VERSION ""

NS_ :

BS_:

BU_: PFAF_HS LVMPC_HS DCDC_HS AMP_HS VICM2_HS FICM_HS ARS_HS MCP_B_HS MCP_A_HS ICCM_OBD_HS SAS_HS ACCM_HS VLBS_HS EBCM_OBD_HS EDI_HS HPCC_HS VITM_OBD_HS PTAM_HS OBCM_HS VICM_HS HCP_HS FDCM_HS APPS_HS ICCM_HS EOCM_F_HS GPCM_HS FSCM_ITBC_HS SCM_HS ITBC_HS VCM_HS HMIM_HS FCP_HS VES_HS Dummy_HS MCP_C_HS RWS_HS ONSTAR_HS EPS_HS TestTool_HS MCP_HS BCP_HS ALC_HS AHL_AFL_HS SADS_HS EPB_HS FSCM_HS AFS_HS FCM_HS TCCM_HS RDCM_HS PTO_HS PCM_HS EBCM_HS ACC_HS BCM_HS TCM_HS ECM_HS

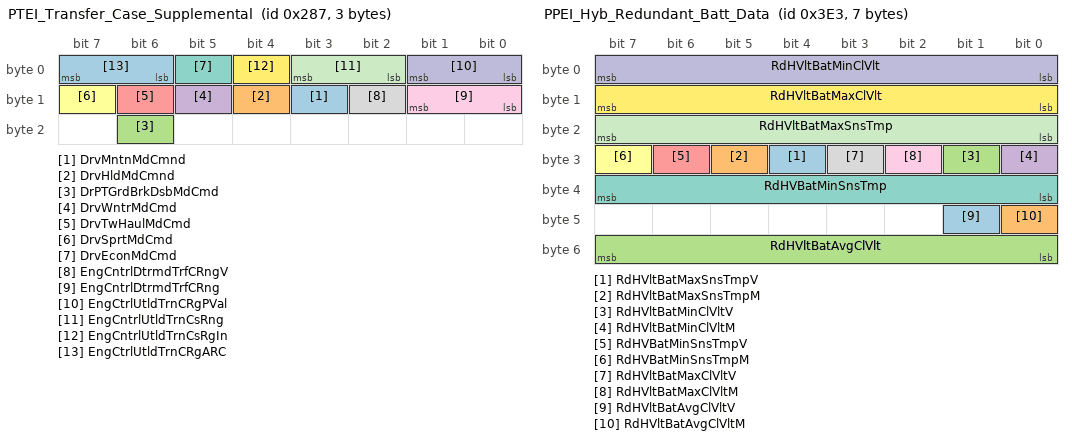
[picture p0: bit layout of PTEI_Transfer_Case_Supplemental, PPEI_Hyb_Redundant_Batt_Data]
BO_ 647 PTEI_Transfer_Case_Supplemental: 3 ECM_HS
 SG_ DrvMntnMdCmnd : 11|1@0+ (1,0) [0|1] ""  HCP_HS
 SG_ DrvHldMdCmnd : 12|1@0+ (1,0) [0|1] ""  HCP_HS
 SG_ DrPTGrdBrkDsbMdCmd : 22|1@0+ (1,0) [0|1] ""  TCM_HS
 SG_ DrvWntrMdCmd : 13|1@0+ (1,0) [0|1] ""  TCM_HS
 SG_ DrvTwHaulMdCmd : 14|1@0+ (1,0) [0|1] ""  TCM_HS
 SG_ DrvSprtMdCmd : 15|1@0+ (1,0) [0|1] ""  TCM_HS,HCP_HS
 SG_ DrvEconMdCmd : 5|1@0+ (1,0) [0|1] ""  TCM_HS
 SG_ EngCntrlDtrmdTrfCRngV : 10|1@0+ (1,0) [0|1] ""  ICCM_OBD_HS,ICCM_HS,TCM_HS
 SG_ EngCntrlDtrmdTrfCRng : 9|2@0+ (1,0) [0|3] ""  ICCM_OBD_HS,ICCM_HS,TCM_HS
 SG_ EngCtrlUtldTrnCRgPVal : 1|2@0+ (1,0) [0|3] ""  EBCM_OBD_HS,EBCM_HS,HCP_HS
 SG_ EngCntrlUtldTrnCsRng : 3|2@0+ (1,0) [0|3] ""  EBCM_OBD_HS,EBCM_HS,BCP_HS,HCP_HS
 SG_ EngCntrlUtldTrnCsRgIn : 4|1@0+ (1,0) [0|1] ""  EBCM_OBD_HS,EBCM_HS,HCP_HS
 SG_ EngCtrlUtldTrnCRgARC : 7|2@0+ (1,0) [0|3] ""  EBCM_OBD_HS,EBCM_HS,HCP_HS

BO_ 368 Environment_Id_Resp_5_HS: 3 ONSTAR_HS
 SG_ EnvIdRspSt5 : 17|2@0+ (1,0) [0|3] ""  BCM_HS
 SG_ EnvIdRsp5 : 7|16@0+ (1,0) [0|65535] ""  BCM_HS

BO_ 995 PPEI_Hyb_Redundant_Batt_Data: 7 VITM_OBD_HS
 SG_ RdHVltBatMaxSnsTmpV : 28|1@0+ (1,0) [0|1] ""  VICM_HS
 SG_ RdHVltBatMaxSnsTmpM : 29|1@0+ (1,0) [0|1] ""  VICM_HS
 SG_ RdHVltBatMinClVltV : 25|1@0+ (1,0) [0|1] ""  VICM_HS
 SG_ RdHVltBatMinClVltM : 24|1@0+ (1,0) [0|1] ""  VICM_HS
 SG_ RdHVBatMinSnsTmpV : 30|1@0+ (1,0) [0|1] ""  VICM_HS
 SG_ RdHVBatMinSnsTmpM : 31|1@0+ (1,0) [0|1] ""  VICM_HS
 SG_ RdHVBatMinSnsTmp : 39|8@0+ (0.5,-40) [-40|87.5] "deg C"  VICM_HS
 SG_ RdHVltBatMaxClVltV : 27|1@0+ (1,0) [0|1] ""  VICM_HS
 SG_ RdHVltBatMaxClVltM : 26|1@0+ (1,0) [0|1] ""  VICM_HS
 SG_ RdHVltBatMinClVlt : 7|8@0+ (0.02,0) [0|5.1] "V"  VICM_HS
 SG_ RdHVltBatMaxSnsTmp : 23|8@0+ (0.5,-40) [-40|87.5] "deg C"  VICM_HS
 SG_ RdHVltBatMaxClVlt : 15|8@0+ (0.02,0) [0|5.1] "V"  VICM_HS
 SG_ RdHVltBatAvgClVltV : 41|1@0+ (1,0) [0|1] ""  VICM_HS
 SG_ RdHVltBatAvgClVltM : 40|1@0+ (1,0) [0|1] ""  VICM_HS
 SG_ RdHVltBatAvgClVlt : 55|8@0+ (0.02,0) [0|5.1] "volts"  VICM_HS

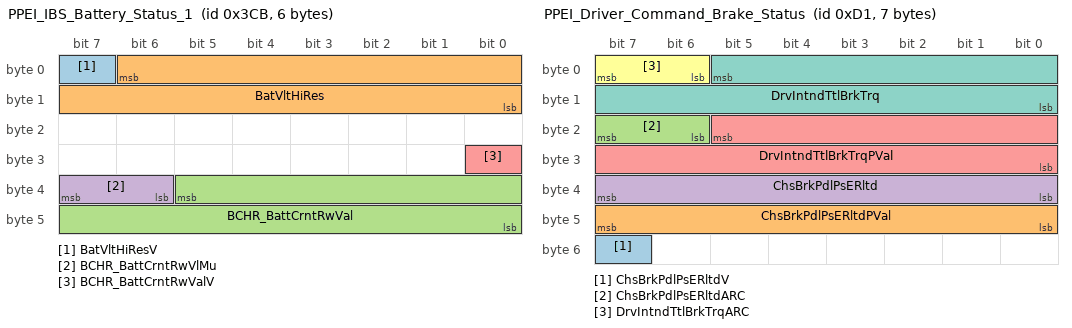
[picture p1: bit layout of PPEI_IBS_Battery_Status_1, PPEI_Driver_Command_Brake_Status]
BO_ 971 PPEI_IBS_Battery_Status_1: 6 BCM_HS
 SG_ BatVltHiResV : 7|1@0+ (1,0) [0|1] ""  ECM_HS
 SG_ BatVltHiRes : 6|15@0+ (0.001,0) [0|32.767] "volts"  ECM_HS
 SG_ BCHR_BattCrntRwVal : 37|14@0+ (0.001,-8.192) [-8.192|8.191] ""  ECM_HS
 SG_ BCHR_BattCrntRwVlMu : 39|2@0+ (1,0) [0|3] ""  ECM_HS
 SG_ BCHR_BattCrntRwValV : 24|1@0+ (1,0) [0|1] ""  ECM_HS

BO_ 209 PPEI_Driver_Command_Brake_Status: 7 EBCM_HS
 SG_ ChsBrkPdlPsERltdV : 55|1@0+ (1,0) [0|1] ""  ECM_HS
 SG_ ChsBrkPdlPsERltdPVal : 47|8@0+ (1,0) [0|255] ""  ECM_HS
 SG_ ChsBrkPdlPsERltdARC : 23|2@0+ (1,0) [0|3] ""  ECM_HS
 SG_ ChsBrkPdlPsERltd : 39|8@0+ (0.392157,0) [0|100.000035] "%"  ECM_HS
 SG_ DrvIntndTtlBrkTrqPVal : 21|14@0+ (1,0) [0|16383] ""  ECM_HS
 SG_ DrvIntndTtlBrkTrqARC : 7|2@0+ (1,0) [0|3] ""  ECM_HS
 SG_ DrvIntndTtlBrkTrq : 5|14@0+ (2,0) [0|32766] "Nm"  ECM_HS,HCP_HS,VICM_HS

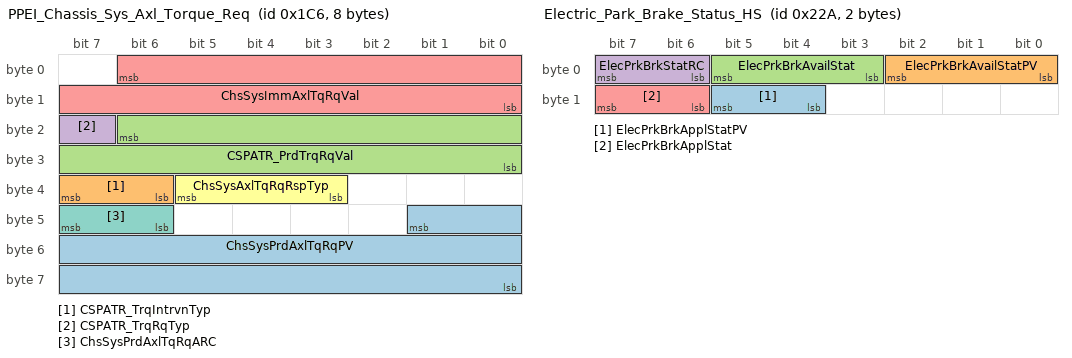
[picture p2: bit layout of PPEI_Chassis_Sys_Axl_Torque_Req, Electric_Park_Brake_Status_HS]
BO_ 454 PPEI_Chassis_Sys_Axl_Torque_Req: 8 EBCM_HS
 SG_ ChsSysPrdAxlTqRqPV : 41|18@0+ (1,0) [0|262143] ""  ECM_HS
 SG_ CSPATR_TrqIntrvnTyp : 39|2@0+ (1,0) [0|3] ""  ECM_HS
 SG_ CSPATR_PrdTrqRqVal : 22|15@0+ (2,-22534) [-22534|43000] "Nm"  ECM_HS
 SG_ CSPATR_TrqRqTyp : 23|1@0+ (1,0) [0|1] ""  ECM_HS
 SG_ ChsSysImmAxlTqRqVal : 6|15@0+ (2,-22534) [-22534|43000] "Nm"  ECM_HS
 SG_ ChsSysAxlTqRqRspTyp : 37|3@0+ (1,0) [0|7] ""  ECM_HS
 SG_ ChsSysPrdAxlTqRqARC : 47|2@0+ (1,0) [0|3] ""  ECM_HS

BO_ 554 Electric_Park_Brake_Status_HS: 2 EPB_HS
 SG_ ElecPrkBrkApplStatPV : 13|2@0+ (1,0) [0|3] ""  VICM_HS,EBCM_OBD_HS,EBCM_HS
 SG_ ElecPrkBrkAvailStatPV : 2|3@0+ (1,0) [0|7] ""  VICM_HS,EBCM_OBD_HS,EBCM_HS
 SG_ ElecPrkBrkAvailStat : 5|3@0+ (1,0) [0|7] ""  VICM_HS,EBCM_OBD_HS,EBCM_HS
 SG_ ElecPrkBrkStatRC : 7|2@0+ (1,0) [0|3] ""  VICM_HS,EBCM_OBD_HS,EBCM_HS
 SG_ ElecPrkBrkApplStat : 15|2@0+ (1,0) [0|3] ""  VICM_HS,EBCM_OBD_HS,EBCM_HS

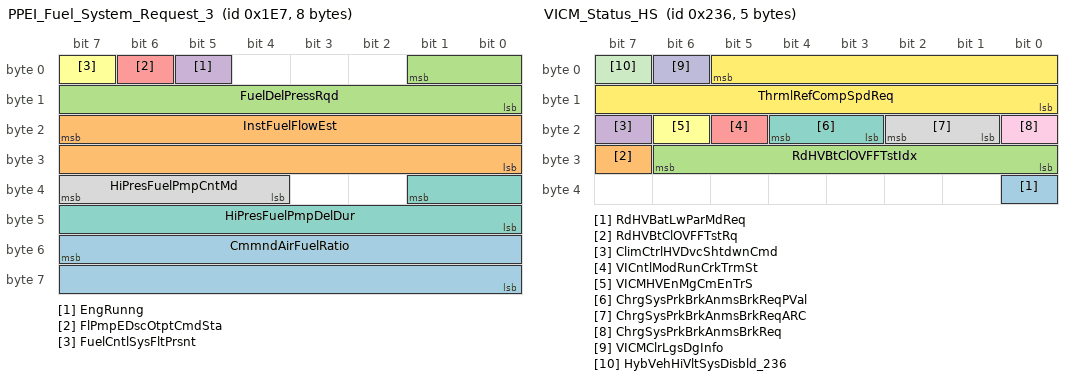
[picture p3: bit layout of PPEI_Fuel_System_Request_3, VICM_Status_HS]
BO_ 487 PPEI_Fuel_System_Request_3: 8 ECM_HS
 SG_ CmmndAirFuelRatio : 55|16@0+ (0.000488281,0) [0|31.999495335] ""  ICCM_OBD_HS,ICCM_HS,FSCM_ITBC_HS,FSCM_HS
 SG_ InstFuelFlowEst : 23|16@0+ (0.000976562,0) [0|63.99899067] "grams/s"  ICCM_OBD_HS,ICCM_HS,FSCM_ITBC_HS,FSCM_HS
 SG_ FuelDelPressRqd : 1|10@0+ (1,0) [0|1023] "kPa"  ICCM_OBD_HS,ICCM_HS,FSCM_ITBC_HS,FSCM_HS
 SG_ EngRunng : 5|1@0+ (1,0) [0|1] ""  ICCM_OBD_HS,ICCM_HS,FSCM_ITBC_HS,FSCM_HS
 SG_ FlPmpEDscOtptCmdSta : 6|1@0+ (1,0) [0|1] ""  ICCM_OBD_HS,ICCM_HS,FSCM_ITBC_HS,FSCM_HS
 SG_ FuelCntlSysFltPrsnt : 7|1@0+ (1,0) [0|1] ""  ICCM_OBD_HS,ICCM_HS,FSCM_ITBC_HS,FSCM_HS
 SG_ HiPresFuelPmpDelDur : 33|10@0+ (1,0) [0|1023] "deg"  ICCM_OBD_HS,ICCM_HS,FSCM_ITBC_HS,FSCM_HS
 SG_ HiPresFuelPmpCntMd : 39|4@0+ (1,0) [0|15] ""  ICCM_OBD_HS,ICCM_HS,FSCM_ITBC_HS,FSCM_HS

BO_ 566 VICM_Status_HS: 5 VICM_HS
 SG_ RdHVBatLwParMdReq : 32|1@0+ (1,0) [0|1] ""  VITM_OBD_HS
 SG_ RdHVBtClOVFFTstRq : 31|1@0+ (1,0) [0|1] ""  VITM_OBD_HS
 SG_ RdHVBtClOVFFTstIdx : 30|7@0+ (1,0) [0|127] ""  VITM_OBD_HS
 SG_ ClimCtrlHVDvcShtdwnCmd : 23|1@0+ (1,0) [0|1] ""  ACCM_HS
 SG_ VICntlModRunCrkTrmSt : 21|1@0+ (1,0) [0|1] ""  ACCM_HS
 SG_ VICMHVEnMgCmEnTrS : 22|1@0+ (1,0) [0|1] ""  VICM2_HS,VITM_OBD_HS,OBCM_HS
 SG_ ChrgSysPrkBrkAnmsBrkReqPVal : 20|2@0+ (1,0) [0|3] ""  EPB_HS
 SG_ ChrgSysPrkBrkAnmsBrkReqARC : 18|2@0+ (1,0) [0|3] ""  EPB_HS
 SG_ ChrgSysPrkBrkAnmsBrkReq : 16|1@0+ (1,0) [0|1] ""  EPB_HS
 SG_ VICMClrLgsDgInfo : 6|1@0+ (1,0) [0|1] ""  ACCM_HS
 SG_ HybVehHiVltSysDisbld_236 : 7|1@0+ (1,0) [0|1] ""  FCP_HS,ONSTAR_HS
 SG_ ThrmlRefCompSpdReq : 5|14@0+ (1,0) [0|16383] "rpm"  ACCM_HS

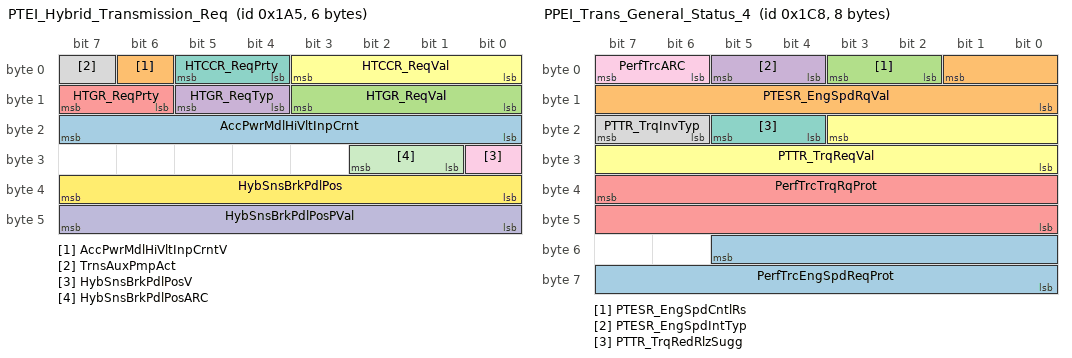
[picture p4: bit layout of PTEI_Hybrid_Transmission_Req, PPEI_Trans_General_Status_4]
BO_ 421 PTEI_Hybrid_Transmission_Req: 6 BCP_HS
 SG_ AccPwrMdlHiVltInpCrnt : 23|8@0+ (0.125,-5) [-5|26.875] "A"  MCP_HS
 SG_ AccPwrMdlHiVltInpCrntV : 6|1@0+ (1,0) [0|1] ""  MCP_HS
 SG_ HTGR_ReqVal : 11|4@0+ (1,0) [0|15] ""  TCM_HS
 SG_ HTGR_ReqTyp : 13|2@0+ (1,0) [0|3] ""  TCM_HS
 SG_ HTGR_ReqPrty : 15|2@0+ (1,0) [0|3] ""  TCM_HS
 SG_ HTCCR_ReqVal : 3|4@0+ (1,0) [0|15] ""  TCM_HS
 SG_ HTCCR_ReqPrty : 5|2@0+ (1,0) [0|3] ""  TCM_HS
 SG_ TrnsAuxPmpAct : 7|1@0+ (1,0) [0|1] ""  TCM_HS
 SG_ HybSnsBrkPdlPosV : 24|1@0+ (1,0) [0|1] ""  TCM_HS,PCM_HS,ECM_HS
 SG_ HybSnsBrkPdlPosPVal : 47|8@0+ (1,0) [0|255] ""  TCM_HS,PCM_HS,ECM_HS
 SG_ HybSnsBrkPdlPosARC : 26|2@0+ (1,0) [0|3] ""  TCM_HS,PCM_HS,ECM_HS
 SG_ HybSnsBrkPdlPos : 39|8@0+ (0.392157,0) [0|100.000035] "%"  TCM_HS,PCM_HS,ECM_HS

BO_ 456 PPEI_Trans_General_Status_4: 8 PTAM_HS
 SG_ PerfTrcEngSpdReqProt : 53|14@0+ (1,0) [0|16383] ""  PCM_HS,ECM_HS
 SG_ PTESR_EngSpdRqVal : 1|10@0+ (8,0) [0|8184] "rpm"  LVMPC_HS,PCM_HS,ECM_HS
 SG_ PTESR_EngSpdCntlRs : 3|2@0+ (1,0) [0|3] ""  LVMPC_HS,PCM_HS,ECM_HS
 SG_ PTESR_EngSpdIntTyp : 5|2@0+ (1,0) [0|3] ""  LVMPC_HS,PCM_HS,ECM_HS
 SG_ PerfTrcTrqRqProt : 39|16@0+ (1,0) [0|65535] ""  PCM_HS,ECM_HS
 SG_ PTTR_TrqReqVal : 19|12@0+ (0.5,-848) [-848|1199.5] "Nm"  ICCM_OBD_HS,ICCM_HS,PCM_HS,ECM_HS
 SG_ PTTR_TrqRedRlzSugg : 21|2@0+ (1,0) [0|3] ""  ICCM_OBD_HS,ICCM_HS,PCM_HS,ECM_HS
 SG_ PTTR_TrqInvTyp : 23|2@0+ (1,0) [0|3] ""  ICCM_OBD_HS,ICCM_HS,PCM_HS,ECM_HS
 SG_ PerfTrcARC : 7|2@0+ (1,0) [0|3] ""  PCM_HS,ECM_HS

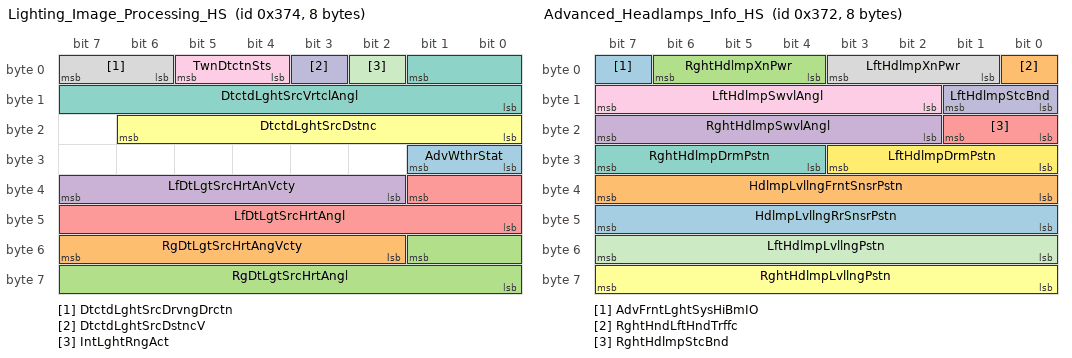
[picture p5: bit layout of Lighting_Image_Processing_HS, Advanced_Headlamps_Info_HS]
BO_ 884 Lighting_Image_Processing_HS: 8 FCM_HS
 SG_ AdvWthrStat : 25|2@0+ (1,0) [0|3] ""  EDI_HS,AHL_AFL_HS
 SG_ RgDtLgtSrcHrtAngVcty : 55|6@0- (1,0) [-32|31] "deg/sec"  AHL_AFL_HS
 SG_ RgDtLgtSrcHrtAngl : 49|10@0- (0.04,0) [-20.48|20.44] "deg"  AHL_AFL_HS
 SG_ LfDtLgtSrcHrtAnVcty : 39|6@0- (1,0) [-32|31] "deg/sec"  AHL_AFL_HS
 SG_ LfDtLgtSrcHrtAngl : 33|10@0- (0.04,0) [-20.48|20.44] "deg"  AHL_AFL_HS
 SG_ DtctdLghtSrcDstnc : 22|7@0+ (10,0) [0|1270] "m"  AHL_AFL_HS
 SG_ DtctdLghtSrcVrtclAngl : 1|10@0- (0.04,0) [-20.48|20.44] "deg"  AHL_AFL_HS
 SG_ DtctdLghtSrcDrvngDrctn : 7|2@0+ (1,0) [0|3] ""  AHL_AFL_HS
 SG_ TwnDtctnSts : 5|2@0+ (1,0) [0|3] ""  AHL_AFL_HS
 SG_ DtctdLghtSrcDstncV : 3|1@0+ (1,0) [0|1] ""  AHL_AFL_HS
 SG_ IntLghtRngAct : 2|1@0+ (1,0) [0|1] ""  AHL_AFL_HS

BO_ 882 Advanced_Headlamps_Info_HS: 8 AHL_AFL_HS
 SG_ AdvFrntLghtSysHiBmIO : 7|1@0+ (1,0) [0|1] ""  BCM_HS,FCM_HS
 SG_ RghtHndLftHndTrffc : 0|1@0+ (1,0) [0|1] ""  FCM_HS
 SG_ RghtHdlmpXnPwr : 6|3@0+ (1,32) [32|39] "Watt"  FCM_HS
 SG_ RghtHdlmpSwvlAngl : 23|6@0- (0.5,0) [-16|15.5] "deg"  FCM_HS
 SG_ RghtHdlmpStcBnd : 17|2@0+ (25,25) [25|100] "%"  FCM_HS
 SG_ RghtHdlmpLvllngPstn : 63|8@0- (0.05,0) [-6.4|6.35] "%"  FCM_HS
 SG_ RghtHdlmpDrmPstn : 31|4@0+ (1,1) [1|16] ""  FCM_HS
 SG_ LftHdlmpXnPwr : 3|3@0+ (1,32) [32|39] "Watt"  FCM_HS
 SG_ LftHdlmpSwvlAngl : 15|6@0- (0.5,0) [-16|15.5] "deg"  FCM_HS
 SG_ LftHdlmpStcBnd : 9|2@0+ (25,25) [25|100] "%"  FCM_HS
 SG_ LftHdlmpLvllngPstn : 55|8@0- (0.05,0) [-6.4|6.35] "%"  FCM_HS
 SG_ LftHdlmpDrmPstn : 27|4@0+ (1,1) [1|16] ""  FCM_HS
 SG_ HdlmpLvllngRrSnsrPstn : 47|8@0- (1,0) [-128|127] "mm"  FCM_HS
 SG_ HdlmpLvllngFrntSnsrPstn : 39|8@0- (1,0) [-128|127] "mm"  FCM_HS

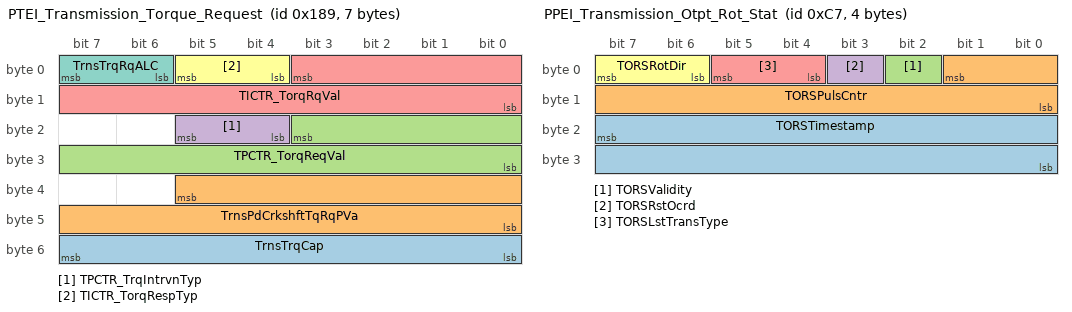
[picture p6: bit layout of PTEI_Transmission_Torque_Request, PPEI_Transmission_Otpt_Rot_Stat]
BO_ 393 PTEI_Transmission_Torque_Request: 7 ECM_HS
 SG_ TrnsTrqCap : 55|8@0+ (4,0) [0|1020] "Nm"  PCM_HS,ECM_HS
 SG_ TrnsPdCrkshftTqRqPVa : 37|14@0+ (1,0) [0|16383] ""  PCM_HS,ECM_HS
 SG_ TPCTR_TorqReqVal : 19|12@0+ (0.5,-848) [-848|1199.5] "Nm"  PCM_HS,ECM_HS
 SG_ TPCTR_TrqIntrvnTyp : 21|2@0+ (1,0) [0|3] ""  PCM_HS,ECM_HS
 SG_ TICTR_TorqRqVal : 3|12@0+ (0.5,-848) [-848|1199.5] "Nm"  PCM_HS,ECM_HS
 SG_ TICTR_TorqRespTyp : 5|2@0+ (1,0) [0|3] ""  PCM_HS,ECM_HS
 SG_ TrnsTrqRqALC : 7|2@0+ (1,0) [0|3] ""  PCM_HS,ECM_HS

BO_ 199 PPEI_Transmission_Otpt_Rot_Stat: 4 TCM_HS
 SG_ TORSTimestamp : 23|16@0+ (1,0) [0|65535] "counts"  ICCM_OBD_HS,ICCM_HS,TCCM_HS,BCP_HS
 SG_ TORSPulsCntr : 1|10@0+ (1,0) [0|1023] "counts"  ICCM_OBD_HS,ICCM_HS,TCCM_HS,BCP_HS
 SG_ TORSValidity : 2|1@0+ (1,0) [0|1] ""  ICCM_OBD_HS,ICCM_HS,TCCM_HS,BCP_HS
 SG_ TORSRstOcrd : 3|1@0+ (1,0) [0|1] ""  ICCM_OBD_HS,ICCM_HS,TCCM_HS,BCP_HS
 SG_ TORSLstTransType : 5|2@0+ (1,0) [0|3] ""  ICCM_OBD_HS,ICCM_HS,TCCM_HS,BCP_HS
 SG_ TORSRotDir : 7|2@0+ (1,0) [0|3] ""  ICCM_OBD_HS,ICCM_HS,TCCM_HS,BCP_HS

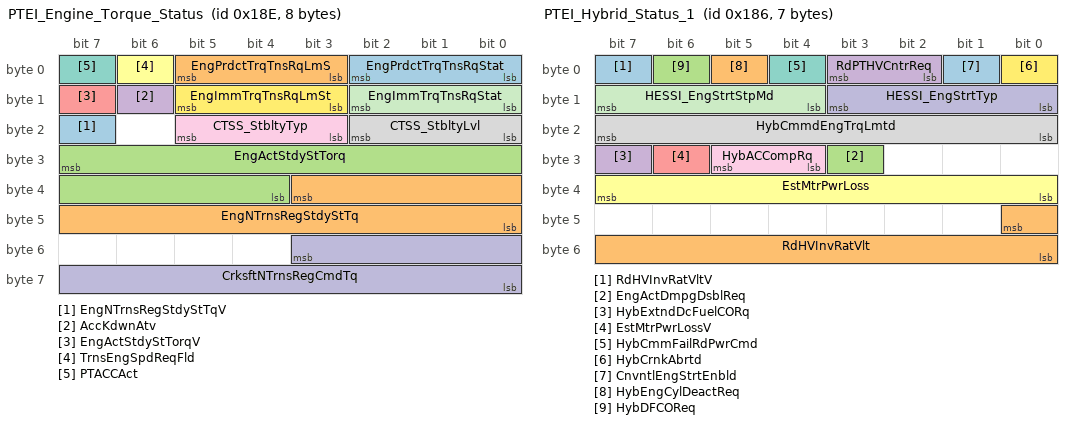
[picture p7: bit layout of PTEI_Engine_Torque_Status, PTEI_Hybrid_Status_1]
BO_ 398 PTEI_Engine_Torque_Status: 8 ECM_HS
 SG_ EngNTrnsRegStdyStTqV : 23|1@0+ (1,0) [0|1] ""  TCM_HS
 SG_ EngNTrnsRegStdyStTq : 35|12@0+ (0.5,-848) [-848|1199.5] "Nm"  TCM_HS
 SG_ EngActStdyStTorq : 31|12@0+ (0.5,-848) [-848|1199.5] "Nm"  TCCM_HS,TCM_HS
 SG_ AccKdwnAtv : 14|1@0+ (1,0) [0|1] ""  TCM_HS,TCCM_HS
 SG_ EngActStdyStTorqV : 15|1@0+ (1,0) [0|1] ""  TCM_HS,TCCM_HS
 SG_ TrnsEngSpdReqFld : 6|1@0+ (1,0) [0|1] ""  TCM_HS,TCCM_HS
 SG_ PTACCAct : 7|1@0+ (1,0) [0|1] ""  TCM_HS
 SG_ CTSS_StbltyLvl : 18|3@0+ (1,0) [0|7] ""  TCM_HS
 SG_ CTSS_StbltyTyp : 21|3@0+ (1,0) [0|7] ""  TCM_HS
 SG_ CrksftNTrnsRegCmdTq : 51|12@0+ (0.5,-848) [-848|1199.5] "Nm"  TCM_HS
 SG_ EngImmTrqTnsRqStat : 10|3@0+ (1,0) [0|7] ""  TCM_HS
 SG_ EngImmTrqTnsRqLmSt : 13|3@0+ (1,0) [0|7] ""  TCM_HS
 SG_ EngPrdctTrqTnsRqStat : 2|3@0+ (1,0) [0|7] ""  TCM_HS
 SG_ EngPrdctTrqTnsRqLmS : 5|3@0+ (1,0) [0|7] ""  TCM_HS

BO_ 464 PPEI_Front_Axle_Status: 4 TCCM_HS
 SG_ FrtAxlOpeMod : 31|3@0+ (1,0) [0|7] ""  EBCM_OBD_HS,EBCM_HS

BO_ 390 PTEI_Hybrid_Status_1: 7 HCP_HS
 SG_ RdHVInvRatVltV : 7|1@0+ (1,0) [0|1] ""  VICM_HS
 SG_ RdHVInvRatVlt : 40|9@0+ (1,0) [0|511] "volts"  VICM_HS
 SG_ EngActDmpgDsblReq : 27|1@0+ (1,0) [0|1] ""  PCM_HS,ECM_HS
 SG_ HybExtndDcFuelCORq : 31|1@0+ (1,0) [0|1] ""  PCM_HS,ECM_HS
 SG_ EstMtrPwrLossV : 30|1@0+ (1,0) [0|1] ""  TCM_HS
 SG_ EstMtrPwrLoss : 39|8@0+ (0.25,0) [0|63.75] "kW"  TCM_HS
 SG_ HybCmmFailRdPwrCmd : 4|1@0+ (1,0) [0|1] ""  PCM_HS,ECM_HS
 SG_ HybCmmdEngTrqLmtd : 23|8@0+ (0.75,-90) [-90|101.25] "Nm"  PCM_HS,ECM_HS
 SG_ HybACCompRq : 29|2@0+ (1,0) [0|3] ""  PCM_HS,ECM_HS
 SG_ HESSI_EngStrtTyp : 11|4@0+ (1,0) [0|15] ""  VICM2_HS,VICM_HS,PCM_HS,ECM_HS
 SG_ HESSI_EngStrtStpMd : 15|4@0+ (1,0) [0|15] ""  VICM2_HS,VICM_HS,PCM_HS,ECM_HS
 SG_ HybCrnkAbrtd : 0|1@0+ (1,0) [0|1] ""  PCM_HS,ECM_HS
 SG_ CnvntlEngStrtEnbld : 1|1@0+ (1,0) [0|1] ""  PCM_HS,ECM_HS
 SG_ HybEngCylDeactReq : 5|1@0+ (1,0) [0|1] ""  PCM_HS,ECM_HS
 SG_ HybDFCOReq : 6|1@0+ (1,0) [0|1] ""  PCM_HS,ECM_HS
 SG_ RdPTHVCntrReq : 3|2@0+ (1,0) [0|3] ""  VICM_HS

BO_ 817 Rear_Axle_General_Information_HS: 2 RDCM_HS
 SG_ RrDrvlnSysVehTpSpdLmVal : 15|8@0+ (2,0) [0|510] "km/h"  BCM_HS
 SG_ RrAxlTmpInhIO : 1|1@0+ (1,0) [0|1] ""  BCM_HS
 SG_ RrAxlMalfIO : 0|1@0+ (1,0) [0|1] ""  BCM_HS,EBCM_OBD_HS,EBCM_HS

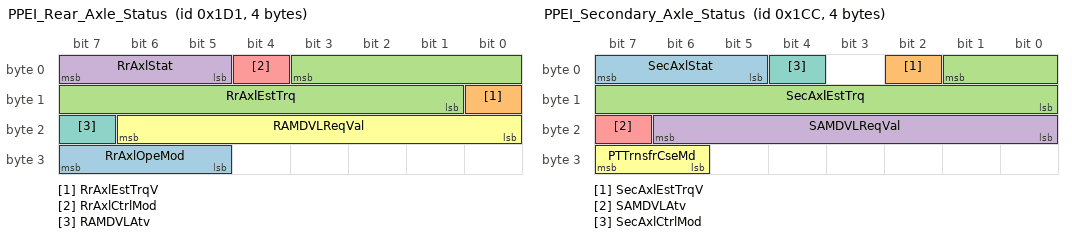
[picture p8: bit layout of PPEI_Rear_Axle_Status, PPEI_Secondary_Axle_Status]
BO_ 465 PPEI_Rear_Axle_Status: 4 TCCM_HS
 SG_ RrAxlOpeMod : 31|3@0+ (1,0) [0|3] ""  EBCM_OBD_HS,EBCM_HS
 SG_ RrAxlEstTrqV : 8|1@0+ (1,0) [0|1] ""  EBCM_OBD_HS,EBCM_HS
 SG_ RrAxlEstTrq : 3|11@0- (5,0) [-5120|5115] "Nm"  EBCM_OBD_HS,EBCM_HS
 SG_ RrAxlStat : 7|3@0+ (1,0) [0|3] ""  EBCM_OBD_HS,EBCM_HS
 SG_ RrAxlCtrlMod : 4|1@0+ (1,0) [0|1] ""  EBCM_OBD_HS,EBCM_HS
 SG_ RAMDVLReqVal : 22|7@0+ (2,0) [0|254] "rpm"  EBCM_OBD_HS,EBCM_HS
 SG_ RAMDVLAtv : 23|1@0+ (1,0) [0|1] ""  EBCM_OBD_HS,EBCM_HS

BO_ 460 PPEI_Secondary_Axle_Status: 4 TCCM_HS
 SG_ SecAxlStat : 7|3@0+ (1,0) [0|3] ""  EOCM_F_HS,ACC_HS,EBCM_OBD_HS,EBCM_HS
 SG_ SecAxlEstTrqV : 2|1@0+ (1,0) [0|1] ""  EBCM_OBD_HS,EBCM_HS
 SG_ SecAxlEstTrq : 1|10@0+ (10,0) [0|10230] "Nm"  EBCM_OBD_HS,EBCM_HS
 SG_ SAMDVLReqVal : 22|7@0+ (2,0) [0|254] ""  EBCM_OBD_HS,EBCM_HS
 SG_ SAMDVLAtv : 23|1@0+ (1,0) [0|1] ""  EBCM_OBD_HS,EBCM_HS
 SG_ PTTrnsfrCseMd : 31|2@0+ (1,0) [0|3] ""  PCM_HS,TCM_HS,ECM_HS
 SG_ SecAxlCtrlMod : 4|1@0+ (1,0) [0|1] ""  EBCM_OBD_HS,EBCM_HS

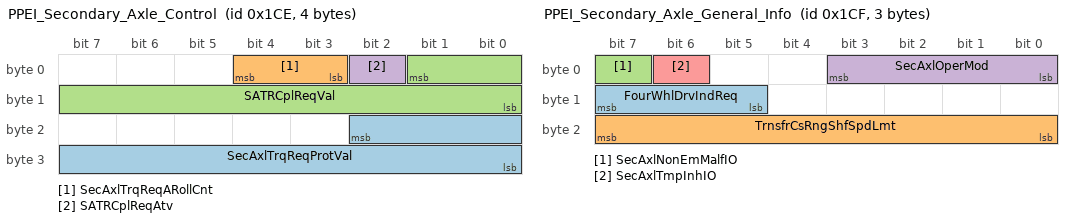
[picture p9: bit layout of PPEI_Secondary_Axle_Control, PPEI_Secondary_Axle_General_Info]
BO_ 462 PPEI_Secondary_Axle_Control: 4 EBCM_HS
 SG_ SecAxlTrqReqProtVal : 18|11@0+ (1,0) [0|2047] "Counts"  TCCM_HS
 SG_ SecAxlTrqReqARollCnt : 4|2@0+ (1,0) [0|3] "Counts"  TCCM_HS
 SG_ SATRCplReqVal : 1|10@0+ (10,0) [0|10230] "Nm"  TCCM_HS
 SG_ SATRCplReqAtv : 2|1@0+ (1,0) [0|1] ""  TCCM_HS

BO_ 463 PPEI_Secondary_Axle_General_Info: 3 ECM_HS
 SG_ FourWhlDrvIndReq : 15|3@0+ (1,0) [0|8] ""  BCM_HS
 SG_ TrnsfrCsRngShfSpdLmt : 23|8@0+ (1,0) [0|255] "km / h"  BCM_HS
 SG_ SecAxlNonEmMalfIO : 7|1@0+ (1,0) [0|1] ""  BCM_HS
 SG_ SecAxlOperMod : 3|4@0+ (1,0) [0|3] ""  VICM_HS,BCM_HS,FCP_HS,ONSTAR_HS,TCM_HS,PCM_HS,ECM_HS,ACC_HS,EOCM_F_HS,EBCM_OBD_HS,EBCM_HS
 SG_ SecAxlTmpInhIO : 6|1@0+ (1,0) [0|1] ""  BCM_HS,FCP_HS,ONSTAR_HS

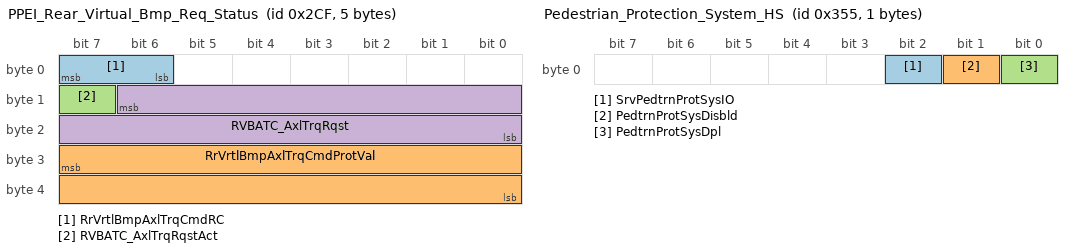
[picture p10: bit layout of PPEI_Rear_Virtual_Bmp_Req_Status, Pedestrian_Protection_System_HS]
BO_ 719 PPEI_Rear_Virtual_Bmp_Req_Status: 5 EOCM_F_HS
 SG_ RrVrtlBmpAxlTrqCmdRC : 7|2@0+ (1,0) [0|3] ""  PCM_HS,ECM_HS
 SG_ RrVrtlBmpAxlTrqCmdProtVal : 31|16@0+ (1,0) [0|65535] ""  PCM_HS,ECM_HS
 SG_ RVBATC_AxlTrqRqstAct : 15|1@0+ (1,0) [0|1] ""  PCM_HS,ECM_HS
 SG_ RVBATC_AxlTrqRqst : 14|15@0+ (2,-22534) [-22534|43000] "NM"  PCM_HS,ECM_HS

BO_ 853 Pedestrian_Protection_System_HS: 1 APPS_HS
 SG_ SrvPedtrnProtSysIO : 2|1@0+ (1,0) [0|1] ""  BCM_HS
 SG_ PedtrnProtSysDisbld : 1|1@0+ (1,0) [0|1] ""  BCM_HS
 SG_ PedtrnProtSysDpl : 0|1@0+ (1,0) [0|1] ""  BCM_HS

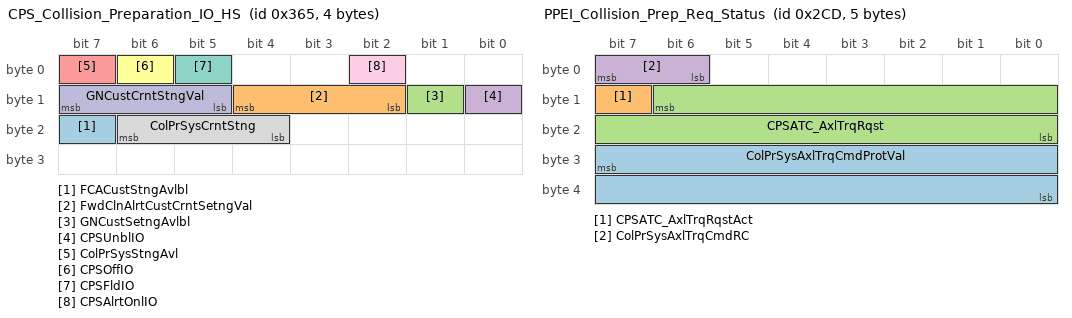
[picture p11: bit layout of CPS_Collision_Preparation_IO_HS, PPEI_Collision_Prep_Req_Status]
BO_ 869 CPS_Collision_Preparation_IO_HS: 4 EOCM_F_HS
 SG_ FCACustStngAvlbl : 23|1@0+ (1,0) [0|1] ""  BCM_HS
 SG_ FwdClnAlrtCustCrntSetngVal : 12|3@0+ (1,0) [0|7] ""  BCM_HS
 SG_ GNCustSetngAvlbl : 9|1@0+ (1,0) [0|1] ""  BCM_HS
 SG_ CPSUnblIO : 8|1@0+ (1,0) [0|1] ""  BCM_HS
 SG_ ColPrSysStngAvl : 7|1@0+ (1,0) [0|1] ""  BCM_HS
 SG_ CPSOffIO : 6|1@0+ (1,0) [0|1] ""  BCM_HS
 SG_ CPSFldIO : 5|1@0+ (1,0) [0|1] ""  BCM_HS
 SG_ ColPrSysCrntStng : 22|3@0+ (1,0) [0|7] ""  BCM_HS
 SG_ CPSAlrtOnlIO : 2|1@0+ (1,0) [0|1] ""  BCM_HS
 SG_ GNCustCrntStngVal : 15|3@0+ (1,0) [0|7] ""  BCM_HS

BO_ 717 PPEI_Collision_Prep_Req_Status: 5 EOCM_F_HS
 SG_ ColPrSysAxlTrqCmdProtVal : 31|16@0+ (1,0) [0|65535] ""  PCM_HS,ECM_HS
 SG_ CPSATC_AxlTrqRqstAct : 15|1@0+ (1,0) [0|1] ""  PCM_HS,ECM_HS
 SG_ CPSATC_AxlTrqRqst : 14|15@0+ (2,-22534) [-22534|43000] "NM"  PCM_HS,ECM_HS
 SG_ ColPrSysAxlTrqCmdRC : 7|2@0+ (1,0) [0|3] ""  PCM_HS,ECM_HS

BO_ 568 A_12V_System_Status_HS: 1 VICM_HS
 SG_ a_12VSysVlt : 7|8@0+ (0.125,0) [0|31.875] "volts"  VICM2_HS,ICCM_OBD_HS,ICCM_HS,FSCM_HS,ACCM_HS

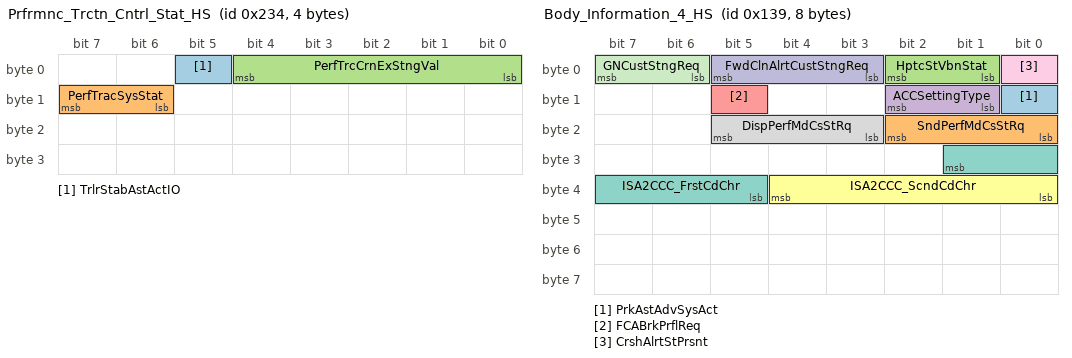
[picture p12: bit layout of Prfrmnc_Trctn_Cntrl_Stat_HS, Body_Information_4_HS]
BO_ 564 Prfrmnc_Trctn_Cntrl_Stat_HS: 4 PTAM_HS
 SG_ TrlrStabAstActIO : 5|1@0+ (1,0) [0|1] ""  BCM_HS
 SG_ PerfTracSysStat : 15|2@0+ (1,0) [0|3] ""  EBCM_OBD_HS,EBCM_HS
 SG_ PerfTrcCrnExStngVal : 4|5@0+ (1,0) [0|31] ""  LVMPC_HS,BCM_HS

BO_ 313 Body_Information_4_HS: 8 BCM_HS
 SG_ PrkAstAdvSysAct : 8|1@0+ (1,0) [0|1] ""  ACC_HS
 SG_ SndPerfMdCsStRq : 18|3@0+ (1,0) [0|7] ""  EBCM_OBD_HS,EBCM_HS
 SG_ HptcStVbnStat : 2|2@0+ (1,0) [0|3] ""  ACC_HS
 SG_ ACCSettingType : 10|2@0+ (1,0) [0|3] ""  ACC_HS
 SG_ FCABrkPrflReq : 13|1@0+ (1,0) [0|1] ""  EBCM_OBD_HS,EBCM_HS
 SG_ ISA2CCC_ScndCdChr : 36|5@0+ (1,0) [0|31] ""  AHL_AFL_HS
 SG_ ISA2CCC_FrstCdChr : 25|5@0+ (1,0) [0|31] ""  AHL_AFL_HS
 SG_ DispPerfMdCsStRq : 21|3@0+ (1,0) [0|7] ""  EBCM_OBD_HS,EBCM_HS
 SG_ CrshAlrtStPrsnt : 0|1@0+ (1,0) [0|1] ""  EBCM_OBD_HS,EBCM_HS,ACC_HS
 SG_ FwdClnAlrtCustStngReq : 5|3@0+ (1,0) [0|7] ""  EOCM_F_HS,ACC_HS
 SG_ GNCustStngReq : 7|2@0+ (1,0) [0|3] ""  EOCM_F_HS,ACC_HS

BO_ 818 Front_Axle_General_Info_HS: 1 FDCM_HS
 SG_ FrntAxlTmpInhIO : 1|1@0+ (1,0) [0|1] ""  BCM_HS
 SG_ FrAxlMalfIO : 0|1@0+ (1,0) [0|1] ""  BCM_HS

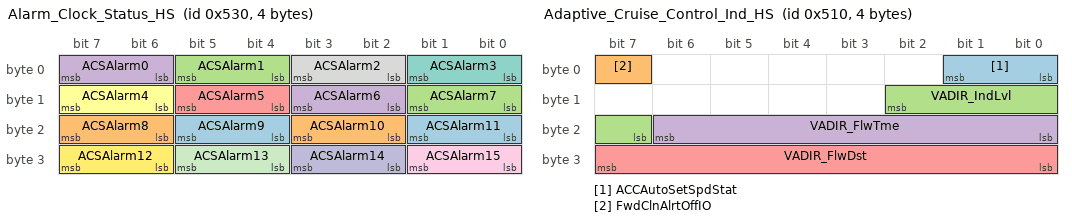
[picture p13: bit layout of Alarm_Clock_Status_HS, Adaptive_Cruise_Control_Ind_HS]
BO_ 1328 Alarm_Clock_Status_HS: 4 BCM_HS
 SG_ ACSAlarm9 : 21|2@0+ (1,0) [0|3] ""  ICCM_OBD_HS,ICCM_HS,ALC_HS
 SG_ ACSAlarm8 : 23|2@0+ (1,0) [0|3] ""  ICCM_OBD_HS,ICCM_HS,ALC_HS
 SG_ ACSAlarm7 : 9|2@0+ (1,0) [0|3] ""  ICCM_OBD_HS,ICCM_HS,ALC_HS
 SG_ ACSAlarm6 : 11|2@0+ (1,0) [0|3] ""  ICCM_OBD_HS,ICCM_HS,ALC_HS
 SG_ ACSAlarm5 : 13|2@0+ (1,0) [0|3] ""  ICCM_OBD_HS,ICCM_HS,ALC_HS
 SG_ ACSAlarm4 : 15|2@0+ (1,0) [0|3] ""  ICCM_OBD_HS,ICCM_HS,ALC_HS
 SG_ ACSAlarm3 : 1|2@0+ (1,0) [0|3] ""  ICCM_OBD_HS,ICCM_HS,ALC_HS
 SG_ ACSAlarm2 : 3|2@0+ (1,0) [0|3] ""  ICCM_OBD_HS,ICCM_HS,ALC_HS
 SG_ ACSAlarm15 : 25|2@0+ (1,0) [0|3] ""  ICCM_OBD_HS,ICCM_HS,ALC_HS
 SG_ ACSAlarm14 : 27|2@0+ (1,0) [0|3] ""  ICCM_OBD_HS,ICCM_HS,ALC_HS
 SG_ ACSAlarm13 : 29|2@0+ (1,0) [0|3] ""  ICCM_OBD_HS,ICCM_HS,ALC_HS
 SG_ ACSAlarm12 : 31|2@0+ (1,0) [0|3] ""  ICCM_OBD_HS,ICCM_HS,ALC_HS
 SG_ ACSAlarm11 : 17|2@0+ (1,0) [0|3] ""  ICCM_OBD_HS,ICCM_HS,ALC_HS
 SG_ ACSAlarm10 : 19|2@0+ (1,0) [0|3] ""  ICCM_OBD_HS,ICCM_HS,ALC_HS
 SG_ ACSAlarm1 : 5|2@0+ (1,0) [0|3] ""  ICCM_OBD_HS,ICCM_HS,ALC_HS
 SG_ ACSAlarm0 : 7|2@0+ (1,0) [0|3] ""  ICCM_OBD_HS,ICCM_HS,ALC_HS

BO_ 1296 Adaptive_Cruise_Control_Ind_HS: 4 ACC_HS
 SG_ ACCAutoSetSpdStat : 1|2@0+ (1,0) [0|3] ""  FCM_HS,BCM_HS
 SG_ FwdClnAlrtOffIO : 7|1@0+ (1,0) [0|1] ""  BCM_HS
 SG_ VADIR_IndLvl : 10|4@0+ (1,0) [0|15] ""  BCM_HS
 SG_ VADIR_FlwTme : 22|7@0+ (0.1,0) [0|12.7] "s"  BCM_HS
 SG_ VADIR_FlwDst : 31|8@0+ (1,0) [0|255] "m"  BCM_HS

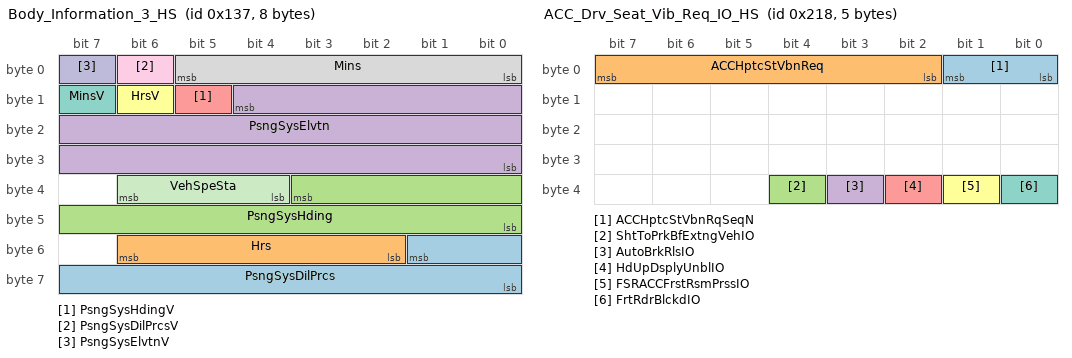
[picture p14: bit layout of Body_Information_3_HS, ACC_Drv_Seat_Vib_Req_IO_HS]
BO_ 311 Body_Information_3_HS: 8 BCM_HS
 SG_ PsngSysDilPrcs : 49|10@0+ (0.1,0) [0|102.3] ""  ACC_HS
 SG_ Hrs : 54|5@0+ (1,0) [0|31] "h"  ACC_HS
 SG_ PsngSysHding : 35|12@0+ (0.1,0) [0|409.5] "deg"  ACC_HS
 SG_ PsngSysElvtn : 12|21@0+ (1,-100000) [-100000|1997151] "cm"  ACC_HS
 SG_ PsngSysHdingV : 13|1@0+ (1,0) [0|1] ""  ACC_HS
 SG_ HrsV : 14|1@0+ (1,0) [0|1] ""  ACC_HS
 SG_ MinsV : 15|1@0+ (1,0) [0|1] ""  ACC_HS
 SG_ Mins : 5|6@0+ (1,0) [0|63] "min"  ACC_HS
 SG_ PsngSysDilPrcsV : 6|1@0+ (1,0) [0|1] ""  ACC_HS
 SG_ PsngSysElvtnV : 7|1@0+ (1,0) [0|1] ""  ACC_HS
 SG_ VehSpeSta : 38|3@0+ (1,0) [0|7] ""  ACC_HS

BO_ 536 ACC_Drv_Seat_Vib_Req_IO_HS: 5 ACC_HS
 SG_ ACCHptcStVbnRqSeqN : 1|2@0+ (1,0) [0|3] ""  BCM_HS
 SG_ ACCHptcStVbnReq : 7|6@0+ (1,0) [0|63] ""  BCM_HS
 SG_ ShtToPrkBfExtngVehIO : 36|1@0+ (1,0) [0|1] ""  BCM_HS
 SG_ AutoBrkRlsIO : 35|1@0+ (1,0) [0|1] ""  BCM_HS
 SG_ HdUpDsplyUnblIO : 34|1@0+ (1,0) [0|1] ""  BCM_HS
 SG_ FSRACCFrstRsmPrssIO : 33|1@0+ (1,0) [0|1] ""  BCM_HS
 SG_ FrtRdrBlckdIO : 32|1@0+ (1,0) [0|1] ""  BCM_HS

BO_ 570 Fwd_Cln_Alrt_Drv_Seat_Vib_Req_HS: 1 ACC_HS
 SG_ FCAHptcStVbnRqSeqN : 1|2@0+ (1,0) [0|3] ""  BCM_HS
 SG_ FCAHptcStVbnReq : 7|6@0+ (1,0) [0|63] ""  BCM_HS

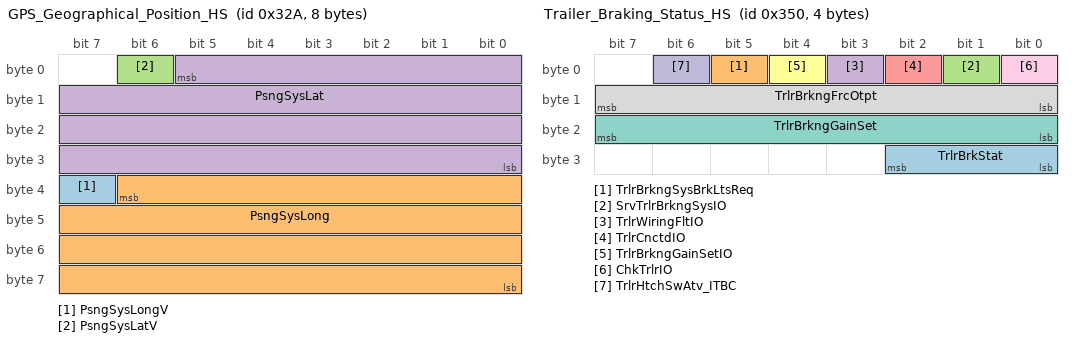
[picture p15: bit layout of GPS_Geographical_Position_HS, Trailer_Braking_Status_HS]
BO_ 810 GPS_Geographical_Position_HS: 8 BCM_HS
 SG_ PsngSysLongV : 39|1@0+ (1,0) [0|1] ""  LVMPC_HS,ACC_HS
 SG_ PsngSysLong : 38|31@0- (1,0) [-1073741824|1073741823] "ms arc"  LVMPC_HS,ACC_HS
 SG_ PsngSysLatV : 6|1@0+ (1,0) [0|1] ""  LVMPC_HS,ACC_HS
 SG_ PsngSysLat : 5|30@0- (1,0) [-536870912|536870911] "ms arc"  LVMPC_HS,ACC_HS

BO_ 848 Trailer_Braking_Status_HS: 4 FSCM_ITBC_HS
 SG_ TrlrBrkStat : 26|3@0+ (1,0) [0|7] ""  EBCM_OBD_HS,EBCM_HS
 SG_ TrlrBrkngSysBrkLtsReq : 5|1@0+ (1,0) [0|1] ""  BCM_HS
 SG_ SrvTrlrBrkngSysIO : 1|1@0+ (1,0) [0|1] ""  BCM_HS
 SG_ TrlrWiringFltIO : 3|1@0+ (1,0) [0|1] ""  BCM_HS
 SG_ TrlrCnctdIO : 2|1@0+ (1,0) [0|1] ""  BCM_HS
 SG_ TrlrBrkngGainSetIO : 4|1@0+ (1,0) [0|1] ""  BCM_HS
 SG_ TrlrBrkngGainSet : 23|8@0+ (0.392157,0) [0|100.000035] "%"  EBCM_OBD_HS,EBCM_HS,BCM_HS
 SG_ TrlrBrkngFrcOtpt : 15|8@0+ (0.392157,0) [0|100.000035] "%"  EBCM_OBD_HS,EBCM_HS,BCM_HS
 SG_ ChkTrlrIO : 0|1@0+ (1,0) [0|1] ""  BCM_HS
 SG_ TrlrHtchSwAtv_ITBC : 6|1@0+ (1,0) [0|1] ""  EOCM_F_HS,ICCM_OBD_HS,ICCM_HS,ALC_HS,SADS_HS,BCM_HS

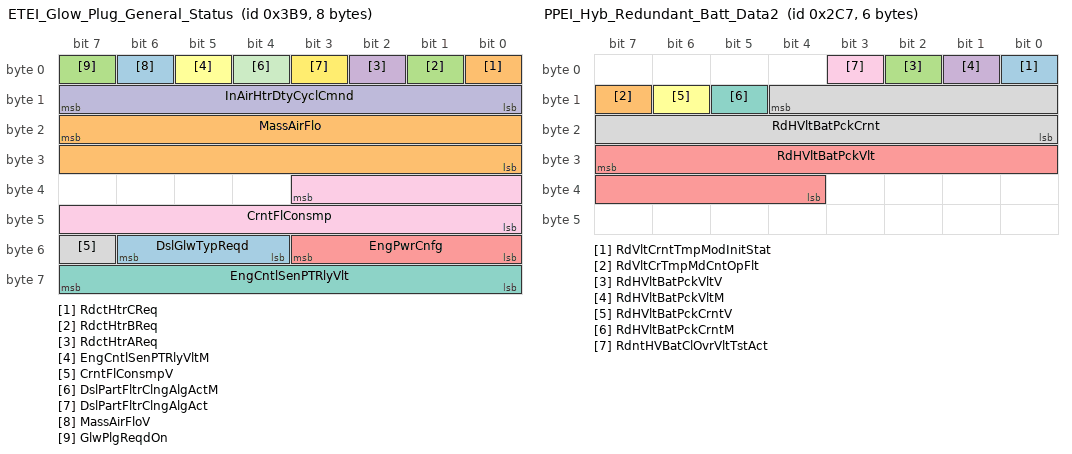
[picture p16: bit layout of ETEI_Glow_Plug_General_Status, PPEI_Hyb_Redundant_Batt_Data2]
BO_ 953 ETEI_Glow_Plug_General_Status: 8 ECM_HS
 SG_ DslGlwTypReqd : 54|3@0+ (1,0) [0|7] ""  GPCM_HS
 SG_ RdctHtrCReq : 0|1@0+ (1,0) [0|1] ""  GPCM_HS
 SG_ RdctHtrBReq : 1|1@0+ (1,0) [0|1] ""  GPCM_HS
 SG_ RdctHtrAReq : 2|1@0+ (1,0) [0|1] ""  GPCM_HS
 SG_ EngPwrCnfg : 51|4@0+ (1,0) [0|15] ""  GPCM_HS
 SG_ EngCntlSenPTRlyVltM : 5|1@0+ (1,0) [0|1] ""  GPCM_HS
 SG_ EngCntlSenPTRlyVlt : 63|8@0+ (0.1,0) [0|25.5] "volts"  GPCM_HS
 SG_ CrntFlConsmpV : 55|1@0+ (1,0) [0|1] ""  GPCM_HS
 SG_ CrntFlConsmp : 35|12@0+ (0.05,0) [0|204.75] "mm3/stk"  GPCM_HS
 SG_ InAirHtrDtyCyclCmnd : 15|8@0+ (0.392157,0) [0|100.000035] "%"  GPCM_HS
 SG_ DslPartFltrClngAlgActM : 4|1@0+ (1,0) [0|1] ""  GPCM_HS
 SG_ DslPartFltrClngAlgAct : 3|1@0+ (1,0) [0|1] ""  GPCM_HS
 SG_ MassAirFloV : 6|1@0+ (1,0) [0|1] ""  GPCM_HS
 SG_ MassAirFlo : 23|16@0+ (0.01,0) [0|655.35] "grams/s"  GPCM_HS
 SG_ GlwPlgReqdOn : 7|1@0+ (1,0) [0|1] ""  GPCM_HS

BO_ 711 PPEI_Hyb_Redundant_Batt_Data2: 6 VITM_OBD_HS
 SG_ RdVltCrntTmpModInitStat : 0|1@0+ (1,0) [0|1] ""  VICM_HS
 SG_ RdVltCrTmpMdCntOpFlt : 15|1@0+ (1,0) [0|1] ""  VICM_HS
 SG_ RdHVltBatPckVltV : 2|1@0+ (1,0) [0|1] ""  VICM_HS
 SG_ RdHVltBatPckVltM : 1|1@0+ (1,0) [0|1] ""  VICM_HS
 SG_ RdHVltBatPckVlt : 31|12@0+ (0.125,0) [0|511.875] "V"  VICM_HS
 SG_ RdHVltBatPckCrntV : 14|1@0+ (1,0) [0|1] ""  VICM_HS
 SG_ RdHVltBatPckCrntM : 13|1@0+ (1,0) [0|1] ""  VICM_HS
 SG_ RdHVltBatPckCrnt : 12|13@0- (0.15,0) [-614.4|614.25] "A"  VICM_HS
 SG_ RdntHVBatClOvrVltTstAct : 3|1@0+ (1,0) [0|1] ""  VICM_HS

BO_ 1011 PPEI_Hybrid_General_Status_3: 2 BCP_HS

BO_ 304 Content_Theft_Sensor_Status_HS: 1 BCM_HS
 SG_ PedFrndlyAlrtCsStReq : 5|3@0+ (1,0) [0|7] ""  PFAF_HS
 SG_ AlrmStat : 2|3@0+ (1,0) [0|7] ""  VLBS_HS,ICCM_OBD_HS,ICCM_HS,ALC_HS

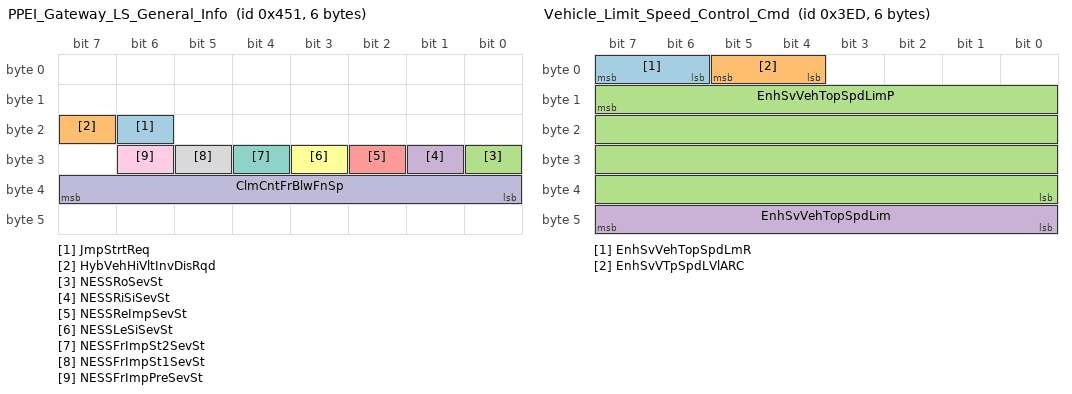
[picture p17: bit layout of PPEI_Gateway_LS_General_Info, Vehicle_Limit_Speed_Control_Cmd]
BO_ 1105 PPEI_Gateway_LS_General_Info: 6 BCM_HS
 SG_ JmpStrtReq : 22|1@0+ (1,0) [0|1] ""  BCP_HS
 SG_ HybVehHiVltInvDisRqd : 23|1@0+ (1,0) [0|1] ""  BCP_HS
 SG_ NESSRoSevSt : 24|1@0+ (1,0) [0|1] ""  ECM_HS,BCP_HS
 SG_ NESSRiSiSevSt : 25|1@0+ (1,0) [0|1] ""  ECM_HS,BCP_HS
 SG_ NESSReImpSevSt : 26|1@0+ (1,0) [0|1] ""  ECM_HS,BCP_HS
 SG_ NESSLeSiSevSt : 27|1@0+ (1,0) [0|1] ""  ECM_HS,BCP_HS
 SG_ NESSFrImpSt2SevSt : 28|1@0+ (1,0) [0|1] ""  ECM_HS,BCP_HS
 SG_ NESSFrImpSt1SevSt : 29|1@0+ (1,0) [0|1] ""  ECM_HS,BCP_HS
 SG_ NESSFrImpPreSevSt : 30|1@0+ (1,0) [0|1] ""  ECM_HS,BCP_HS
 SG_ ClmCntFrBlwFnSp : 39|8@0+ (0.392157,0) [0|100.000035] "%"  EBCM_OBD_HS,EBCM_HS,BCP_HS

BO_ 1005 Vehicle_Limit_Speed_Control_Cmd: 6 ONSTAR_HS
 SG_ EnhSvVehTopSpdLmR : 7|2@0+ (1,0) [0|3] ""  PCM_HS,ECM_HS
 SG_ EnhSvVTpSpdLVlARC : 5|2@0+ (1,0) [0|3] ""  PCM_HS,ECM_HS
 SG_ EnhSvVehTopSpdLimP : 15|32@0+ (1,0) [0|4294967295] ""  PCM_HS,ECM_HS
 SG_ EnhSvVehTopSpdLim : 47|8@0+ (2,0) [0|510] "km / h"  PCM_HS,ECM_HS

BO_ 688 Starter_Generator_Status_3: 5 BCP_HS
 SG_ StrtrGenSpdV : 39|1@0+ (1,0) [0|1] ""  PCM_HS,ECM_HS,EBCM_OBD_HS,EBCM_HS
 SG_ StrtrGenSpd : 21|14@0+ (1,0) [0|16383] "rpm"  PCM_HS,ECM_HS,EBCM_OBD_HS,EBCM_HS

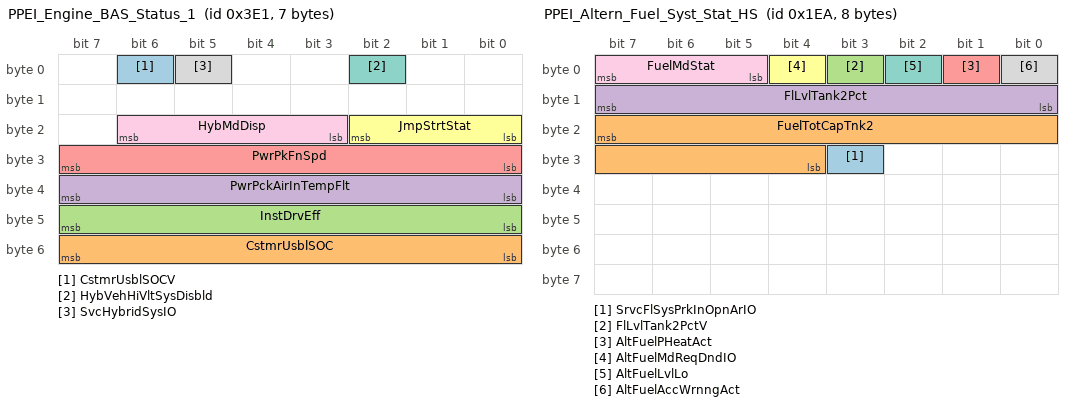
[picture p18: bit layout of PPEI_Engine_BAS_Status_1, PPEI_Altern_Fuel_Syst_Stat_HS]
BO_ 993 PPEI_Engine_BAS_Status_1: 7 BCP_HS
 SG_ CstmrUsblSOCV : 6|1@0+ (1,0) [0|1] ""  BCM_HS
 SG_ CstmrUsblSOC : 55|8@0+ (0.39216,0) [0|100.0008] "%"  BCM_HS
 SG_ InstDrvEff : 47|8@0- (0.7874,0) [-100.7872|99.9998] "%"  BCM_HS
 SG_ PwrPckAirInTempFlt : 39|8@0+ (1,-40) [-40|215] "deg C"  BCM_HS
 SG_ PwrPkFnSpd : 31|8@0+ (0.392157,0) [0|100.000035] "%"  BCM_HS
 SG_ JmpStrtStat : 18|3@0+ (1,0) [0|7] ""  BCM_HS
 SG_ HybVehHiVltSysDisbld : 2|1@0+ (1,0) [0|1] ""  FCP_HS,ONSTAR_HS
 SG_ SvcHybridSysIO : 5|1@0+ (1,0) [0|1] ""  BCM_HS
 SG_ HybMdDisp : 22|4@0+ (1,0) [0|15] ""  BCM_HS

BO_ 490 PPEI_Altern_Fuel_Syst_Stat_HS: 8 ECM_HS
 SG_ SrvcFlSysPrkInOpnArIO : 27|1@0+ (1,0) [0|1] ""  BCM_HS
 SG_ FuelTotCapTnk2 : 23|12@0+ (0.125,0) [0|511.875] "liters"  BCM_HS
 SG_ FlLvlTank2PctV : 3|1@0+ (1,0) [0|1] ""  BCM_HS
 SG_ FlLvlTank2Pct : 15|8@0+ (0.392157,0) [0|100.000035] "%"  BCM_HS
 SG_ AltFuelPHeatAct : 1|1@0+ (1,0) [0|1] ""  ECM_HS,BCM_HS
 SG_ AltFuelMdReqDndIO : 4|1@0+ (1,0) [0|1] ""  BCM_HS
 SG_ AltFuelLvlLo : 2|1@0+ (1,0) [0|1] ""  BCM_HS,ECM_HS
 SG_ AltFuelAccWrnngAct : 0|1@0+ (1,0) [0|1] ""  BCM_HS
 SG_ FuelMdStat : 7|3@0+ (1,0) [0|7] ""  ECM_HS,BCM_HS

BO_ 431 PTEI_Trans_General_Status_2: 8 TCM_HS
 SG_ TransVehTopSpdLim : 63|8@0+ (2,0) [0|510] "km / h"  PCM_HS,ECM_HS
 SG_ TransMinVoltReq : 55|8@0+ (0.07843,0) [0|19.99965] "volts"  PCM_HS,ECM_HS
 SG_ TDslPrtFltrIdlRgtnMdAtv : 6|1@0+ (1,0) [0|1] ""  PCM_HS,ECM_HS
 SG_ DrvlneTrqStabStat : 38|3@0+ (1,0) [0|7] ""  PCM_HS,ECM_HS
 SG_ TrnsTrqCnvCltCmdMdF : 19|1@0+ (1,0) [0|1] ""  PCM_HS,ECM_HS
 SG_ AutoTransGrSftDirectFl : 16|1@0+ (1,0) [0|1] ""  PCM_HS,ECM_HS
 SG_ AutoTransGrSftDirect : 18|2@0+ (1,0) [0|3] ""  PCM_HS,ECM_HS
 SG_ TrnsTrqCnvCltCmndMd : 22|3@0+ (1,0) [0|7] ""  PCM_HS,ECM_HS
 SG_ TrnsTrqCnvCltDsrSlp : 35|12@0- (1,0) [-2048|2047] "rpm"  PCM_HS,ECM_HS
 SG_ TrnsStWntrMdOvrd : 25|2@0+ (1,0) [0|3] ""  PCM_HS,ECM_HS
 SG_ TrnsStTwHaulMdOvrd : 27|2@0+ (1,0) [0|3] ""  PCM_HS,ECM_HS
 SG_ TrnsStSprtMdOvrd : 29|2@0+ (1,0) [0|3] ""  PCM_HS,ECM_HS
 SG_ TrnsStEconMdOvrd : 31|2@0+ (1,0) [0|3] ""  PCM_HS,ECM_HS
 SG_ TrnsInpCltchStat : 2|3@0+ (1,0) [0|7] ""  PCM_HS,ECM_HS
 SG_ TrnsAntcptdCrpTrqRRnV : 7|1@0+ (1,0) [0|1] ""  PCM_HS,ECM_HS
 SG_ TrnsAntcptdCrpTrqRRn : 15|8@0+ (0.5,0) [0|127.5] "Nm"  PCM_HS,ECM_HS
 SG_ TrnCltAdpAtv : 3|1@0+ (1,0) [0|1] ""  PCM_HS,ECM_HS
 SG_ TransCrnkPermsnStat : 5|1@0+ (1,0) [0|1] ""  PCM_HS,ECM_HS
 SG_ WrmUpShftPtrn : 4|1@0+ (1,0) [0|1] ""  PCM_HS,ECM_HS

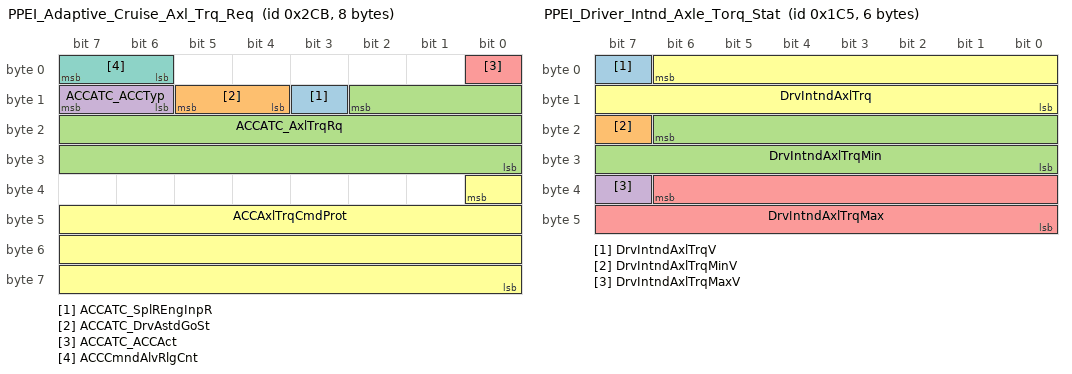
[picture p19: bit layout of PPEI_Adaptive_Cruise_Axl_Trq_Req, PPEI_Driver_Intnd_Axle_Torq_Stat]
BO_ 715 PPEI_Adaptive_Cruise_Axl_Trq_Req: 8 ACC_HS
 SG_ ACCATC_SplREngInpR : 11|1@0+ (1,0) [0|1] ""  PCM_HS,ECM_HS
 SG_ ACCATC_DrvAstdGoSt : 13|2@0+ (1,0) [0|3] ""  PCM_HS,ECM_HS
 SG_ ACCATC_AxlTrqRq : 10|19@0+ (0.125,-22534) [-22534|43001.875] "Nm"  PCM_HS,ECM_HS
 SG_ ACCATC_ACCTyp : 15|2@0+ (1,0) [0|3] ""  PCM_HS,ECM_HS
 SG_ ACCATC_ACCAct : 0|1@0+ (1,0) [0|1] ""  PCM_HS,ECM_HS
 SG_ ACCAxlTrqCmdProt : 32|25@0+ (1,0) [0|33554431] ""  PCM_HS,ECM_HS
 SG_ ACCCmndAlvRlgCnt : 7|2@0+ (1,0) [0|3] ""  PCM_HS,ECM_HS

BO_ 1267 PPEI_Powertrain_Config_Data_2: 1 ECM_HS
 SG_ VehMassNom : 7|8@0+ (20,500) [500|5600] "kg"  EOCM_F_HS,ACC_HS

BO_ 453 PPEI_Driver_Intnd_Axle_Torq_Stat: 6 ECM_HS
 SG_ DrvIntndAxlTrqV : 7|1@0+ (1,0) [0|1] ""  ICCM_OBD_HS,ICCM_HS,EBCM_OBD_HS,EBCM_HS,VICM_HS,HCP_HS,EOCM_F_HS,ACC_HS
 SG_ DrvIntndAxlTrqMinV : 23|1@0+ (1,0) [0|1] ""  EOCM_F_HS,ACC_HS
 SG_ DrvIntndAxlTrqMin : 22|15@0+ (2,-22534) [-22534|43000] "Nm"  EOCM_F_HS,ACC_HS
 SG_ DrvIntndAxlTrqMaxV : 39|1@0+ (1,0) [0|1] ""  EOCM_F_HS,ACC_HS
 SG_ DrvIntndAxlTrqMax : 38|15@0+ (2,-22534) [-22534|43000] "Nm"  EOCM_F_HS,ACC_HS
 SG_ DrvIntndAxlTrq : 6|15@0+ (2,-22534) [-22534|43000] "Nm"  ICCM_OBD_HS,ICCM_HS,EBCM_OBD_HS,EBCM_HS,VICM_HS,HCP_HS,EOCM_F_HS,ACC_HS

BO_TX_BU_ 647 : PCM_HS,ECM_HS;
BO_TX_BU_ 368 : VLBS_HS,ONSTAR_HS;
BO_TX_BU_ 209 : EBCM_OBD_HS,EBCM_HS;
BO_TX_BU_ 454 : EBCM_OBD_HS,EBCM_HS;
BO_TX_BU_ 456 : EBCM_OBD_HS,EBCM_HS,PTAM_HS;
BO_TX_BU_ 393 : PCM_HS,TCM_HS,ECM_HS;
BO_TX_BU_ 398 : PCM_HS,ECM_HS;
BO_TX_BU_ 390 : BCP_HS,HCP_HS;
BO_TX_BU_ 817 : ICCM_OBD_HS,ICCM_HS,RDCM_HS;
BO_TX_BU_ 462 : EBCM_OBD_HS,EBCM_HS;
BO_TX_BU_ 463 : RDCM_HS,TCCM_HS,PCM_HS,ECM_HS;
BO_TX_BU_ 869 : ACC_HS,EOCM_F_HS;
BO_TX_BU_ 717 : ACC_HS,EOCM_F_HS;
BO_TX_BU_ 564 : EBCM_OBD_HS,EBCM_HS,PTAM_HS;
BO_TX_BU_ 953 : PCM_HS,ECM_HS;
BO_TX_BU_ 1005 : VLBS_HS,FCP_HS,ONSTAR_HS;
BO_TX_BU_ 490 : VCM_HS,FICM_HS,PCM_HS,ECM_HS;
BO_TX_BU_ 715 : EOCM_F_HS,ACC_HS;
BO_TX_BU_ 1267 : PCM_HS,ECM_HS;
BO_TX_BU_ 453 : PCM_HS,ECM_HS;
CM_ SG_ 398 EngNTrnsRegStdyStTqV "ETEI 3.1";
CM_ SG_ 398 EngNTrnsRegStdyStTq "ETEI 3.1";
CM_ SG_ 398 EngActStdyStTorq "ETEI 3.1";
CM_ SG_ 398 EngActStdyStTorqV "ETEI 3.1";
CM_ SG_ 390 HybDFCOReq "DFCO = Deceleration Fuel Cut Off";
CM_ BO_ 719 "Application Is Tx ing this frame at the rate of 40 ms";
CM_ BO_ 869 "Note that the ACC algorithm will transmit this message at a 50 ms periodic rate and the EOCM algorithm will transmit this message at a 40 ms periodic rate";
CM_ BO_ 717 "Note that the ACC algorithm will transmit this message at a 50 ms periodic rate and the EOCM algorithm will transmit this message at a 40 ms periodic rate";
CM_ SG_ 311 PsngSysHding "The 'usable' range is somewhat less than the encoded range (0.0 to 359.9 degrees).  0.0 degrees represents North, 90.0 degrees represents East.";
CM_ SG_ 810 PsngSysLong "The units of the data are milli-arcseconds (1/3,600,000 of a degree).  The actual 'usable' range of this data is somewhat less than the encoded range (+/- 648,000,000, corresponding to +/- 180 degrees)";
CM_ SG_ 810 PsngSysLat "The units of the data are milli-arcseconds (1/3,600,000 of a degree).  The actual 'usable' range of this data is somewhat less than the encoded range (+/- 324,000,000, corresponding to +/- 90 degrees)";
CM_ SG_ 1005 EnhSvVehTopSpdLimP "4 ASCII characters";
CM_ BO_ 715 "Note that the ACC algorithm will transmit this message at a 50 ms periodic rate and the EOCM algorithm will transmit this message at a 40 ms periodic rate";
BA_DEF_ SG_  "VNSigSLHS_VNReq" ENUM  "No","Yes";
BA_DEF_ SG_  "VNSigSLHSSharedDiagnostic" ENUM  "No","Yes";
BA_DEF_ SG_  "SignalType" STRING ;
BA_DEF_ SG_  "PacketOrder" INT 0 65535;
BA_DEF_ SG_  "SignalLongName" STRING ;
BA_DEF_ SG_  "GenSigStartValue" INT 0 65535;
BA_DEF_ SG_  "VNSigAllNodes" ENUM  "No","Yes";
BA_DEF_ SG_  "GenSigDeltaValue" INT 0 0;
BA_DEF_ SG_  "GenSigSendType" ENUM  "not used","not used","not used","not used","not used","not used","not used","NoSigSendType","not used","not used","OnAnyChange","OnChangeIfActive","OnDelta";
BA_DEF_ SG_  "GenSigSendOnInit" ENUM  "Not Initialized","Application","Handler";
BA_DEF_ BO_  "AppGenMsgCycleTime" INT 0 0;
BA_DEF_ BO_  "GenMsgILSupport" ENUM  "No","Yes";
BA_DEF_ BO_  "TpApplType" STRING ;
BA_DEF_ BO_  "Prio" INT 0 7;
BA_DEF_ BO_  "MessageSubnet" ENUM  "LS","MS","HS","CE","PE","HV","FO";
BA_DEF_ BO_  "DiagState" ENUM  "No","Yes";
BA_DEF_ BO_  "GenMsgDelayTime" INT 0 100000;
BA_DEF_ BO_  "GenMsgCycleTime" INT 0 100000;
BA_DEF_ BO_  "GenMsgSendType" ENUM  "cyclicX","spontanX","cyclicIfActiveX","spontanWithDelay","cyclicAndSpontanX","cyclicAndSpontanWithDelay","spontanWithRepitition","cyclicIfActiveAndSpontanWD";
BA_DEF_ BO_  "DiagResponse" ENUM  "No","Yes";
BA_DEF_ BO_  "DiagRequest" ENUM  "No","Yes";
BA_DEF_ BO_  "NmMessage" ENUM  "No","Yes";
BA_DEF_REL_ BU_SG_REL_  "GenSigSuprvRespComment" STRING ;
BA_DEF_REL_ BU_SG_REL_  "GenSigVBitResp" ENUM  "No","Yes";
BA_DEF_REL_ BU_SG_REL_  "GenSigVBitRespComment" STRING ;
BA_DEF_REL_ BU_SG_REL_  "GenSigVDAFailComment" STRING ;
BA_DEF_REL_ BU_SG_REL_  "GenSigVDAFailResp" ENUM  "No","Yes";
BA_DEF_REL_ BU_SG_REL_  "GenSigRxStartValue" STRING ;
BA_DEF_REL_ BU_SG_REL_  "GenSigSuprvRespSubValue" INT 0 65535;
BA_DEF_REL_ BU_SG_REL_  "GenSigSuprvResp" ENUM  "None","Notify App","Substitute Default";
BA_DEF_REL_ BU_SG_REL_  "GenSigTimeoutMsg" HEX -2147483648 268435455;
BA_DEF_REL_ BU_SG_REL_  "GenSigTimeoutTime" INT 0 15000;
BA_DEF_DEF_  "VNSigSLHS_VNReq" "No";
BA_DEF_DEF_  "VNSigSLHSSharedDiagnostic" "No";
BA_DEF_DEF_  "SignalType" "";
BA_DEF_DEF_  "PacketOrder" 0;
BA_DEF_DEF_  "SignalLongName" "";
BA_DEF_DEF_  "GenSigStartValue" 0;
BA_DEF_DEF_  "VNSigAllNodes" "No";
BA_DEF_DEF_  "GenSigDeltaValue" 0;
BA_DEF_DEF_  "GenSigSendType" "NoSigSendType";
BA_DEF_DEF_  "GenSigSendOnInit" "Not Initialized";
BA_DEF_DEF_  "AppGenMsgCycleTime" 0;
BA_DEF_DEF_  "GenMsgILSupport" "Yes";
BA_DEF_DEF_  "TpApplType" "";
BA_DEF_DEF_  "Prio" 4;
BA_DEF_DEF_  "MessageSubnet" "FO";
BA_DEF_DEF_  "DiagState" "No";
BA_DEF_DEF_  "GenMsgDelayTime" 0;
BA_DEF_DEF_  "GenMsgCycleTime" 0;
BA_DEF_DEF_  "GenMsgSendType" "spontanX";
BA_DEF_DEF_  "DiagResponse" "No";
BA_DEF_DEF_  "DiagRequest" "No";
BA_DEF_DEF_  "NmMessage" "No";
BA_DEF_DEF_REL_ "GenSigSuprvRespComment" "";
BA_DEF_DEF_REL_ "GenSigVBitResp" "No";
BA_DEF_DEF_REL_ "GenSigVBitRespComment" "";
BA_DEF_DEF_REL_ "GenSigVDAFailComment" "";
BA_DEF_DEF_REL_ "GenSigVDAFailResp" "No";
BA_DEF_DEF_REL_ "GenSigRxStartValue" "";
BA_DEF_DEF_REL_ "GenSigSuprvRespSubValue" 0;
BA_DEF_DEF_REL_ "GenSigSuprvResp" "None";
BA_DEF_DEF_REL_ "GenSigTimeoutMsg" 0;
BA_DEF_DEF_REL_ "GenSigTimeoutTime" 0;
BA_ "Prio" BO_ 647 0;
BA_ "MessageSubnet" BO_ 647 2;
BA_ "GenMsgCycleTime" BO_ 647 25;
BA_ "GenMsgSendType" BO_ 647 0;
BA_ "Prio" BO_ 368 0;
BA_ "MessageSubnet" BO_ 368 2;
BA_ "GenMsgCycleTime" BO_ 368 100;
BA_ "GenMsgSendType" BO_ 368 0;
BA_ "Prio" BO_ 995 0;
BA_ "MessageSubnet" BO_ 995 2;
BA_ "GenMsgCycleTime" BO_ 995 100;
BA_ "GenMsgSendType" BO_ 995 0;
BA_ "Prio" BO_ 971 0;
BA_ "MessageSubnet" BO_ 971 2;
BA_ "GenMsgCycleTime" BO_ 971 100;
BA_ "GenMsgSendType" BO_ 971 0;
BA_ "Prio" BO_ 209 0;
BA_ "MessageSubnet" BO_ 209 2;
BA_ "GenMsgCycleTime" BO_ 209 10;
BA_ "GenMsgSendType" BO_ 209 0;
BA_ "Prio" BO_ 454 0;
BA_ "MessageSubnet" BO_ 454 2;
BA_ "GenMsgCycleTime" BO_ 454 25;
BA_ "GenMsgSendType" BO_ 454 0;
BA_ "Prio" BO_ 554 0;
BA_ "MessageSubnet" BO_ 554 2;
BA_ "GenMsgCycleTime" BO_ 554 100;
BA_ "GenMsgSendType" BO_ 554 0;
BA_ "Prio" BO_ 487 0;
BA_ "MessageSubnet" BO_ 487 2;
BA_ "GenMsgCycleTime" BO_ 487 12;
BA_ "GenMsgSendType" BO_ 487 0;
BA_ "Prio" BO_ 566 0;
BA_ "MessageSubnet" BO_ 566 2;
BA_ "GenMsgCycleTime" BO_ 566 100;
BA_ "GenMsgSendType" BO_ 566 0;
BA_ "Prio" BO_ 421 0;
BA_ "MessageSubnet" BO_ 421 2;
BA_ "GenMsgCycleTime" BO_ 421 25;
BA_ "GenMsgSendType" BO_ 421 0;
BA_ "Prio" BO_ 456 0;
BA_ "MessageSubnet" BO_ 456 2;
BA_ "GenMsgCycleTime" BO_ 456 12;
BA_ "GenMsgSendType" BO_ 456 0;
BA_ "Prio" BO_ 884 0;
BA_ "MessageSubnet" BO_ 884 2;
BA_ "GenMsgCycleTime" BO_ 884 40;
BA_ "GenMsgSendType" BO_ 884 0;
BA_ "Prio" BO_ 882 0;
BA_ "MessageSubnet" BO_ 882 2;
BA_ "GenMsgCycleTime" BO_ 882 40;
BA_ "GenMsgSendType" BO_ 882 0;
BA_ "Prio" BO_ 393 0;
BA_ "MessageSubnet" BO_ 393 2;
BA_ "GenMsgCycleTime" BO_ 393 25;
BA_ "GenMsgSendType" BO_ 393 0;
BA_ "Prio" BO_ 199 0;
BA_ "MessageSubnet" BO_ 199 2;
BA_ "GenMsgCycleTime" BO_ 199 12;
BA_ "GenMsgSendType" BO_ 199 0;
BA_ "Prio" BO_ 398 0;
BA_ "MessageSubnet" BO_ 398 2;
BA_ "GenMsgCycleTime" BO_ 398 12;
BA_ "GenMsgSendType" BO_ 398 0;
BA_ "Prio" BO_ 464 0;
BA_ "MessageSubnet" BO_ 464 2;
BA_ "GenMsgCycleTime" BO_ 464 20;
BA_ "GenMsgSendType" BO_ 464 0;
BA_ "Prio" BO_ 390 0;
BA_ "MessageSubnet" BO_ 390 2;
BA_ "GenMsgCycleTime" BO_ 390 12;
BA_ "GenMsgSendType" BO_ 390 0;
BA_ "Prio" BO_ 817 0;
BA_ "MessageSubnet" BO_ 817 2;
BA_ "GenMsgCycleTime" BO_ 817 100;
BA_ "GenMsgSendType" BO_ 817 0;
BA_ "Prio" BO_ 465 0;
BA_ "MessageSubnet" BO_ 465 2;
BA_ "GenMsgCycleTime" BO_ 465 20;
BA_ "GenMsgSendType" BO_ 465 0;
BA_ "Prio" BO_ 460 0;
BA_ "MessageSubnet" BO_ 460 2;
BA_ "GenMsgCycleTime" BO_ 460 20;
BA_ "GenMsgSendType" BO_ 460 0;
BA_ "Prio" BO_ 462 0;
BA_ "MessageSubnet" BO_ 462 2;
BA_ "GenMsgCycleTime" BO_ 462 20;
BA_ "GenMsgSendType" BO_ 462 0;
BA_ "Prio" BO_ 463 0;
BA_ "MessageSubnet" BO_ 463 2;
BA_ "GenMsgCycleTime" BO_ 463 100;
BA_ "GenMsgSendType" BO_ 463 0;
BA_ "AppGenMsgCycleTime" BO_ 719 40;
BA_ "Prio" BO_ 719 0;
BA_ "MessageSubnet" BO_ 719 2;
BA_ "Prio" BO_ 853 0;
BA_ "MessageSubnet" BO_ 853 2;
BA_ "GenMsgCycleTime" BO_ 853 100;
BA_ "GenMsgSendType" BO_ 853 0;
BA_ "AppGenMsgCycleTime" BO_ 869 40;
BA_ "Prio" BO_ 869 0;
BA_ "MessageSubnet" BO_ 869 2;
BA_ "AppGenMsgCycleTime" BO_ 717 40;
BA_ "Prio" BO_ 717 0;
BA_ "MessageSubnet" BO_ 717 2;
BA_ "Prio" BO_ 568 0;
BA_ "MessageSubnet" BO_ 568 2;
BA_ "GenMsgCycleTime" BO_ 568 10;
BA_ "GenMsgSendType" BO_ 568 0;
BA_ "Prio" BO_ 564 0;
BA_ "MessageSubnet" BO_ 564 2;
BA_ "GenMsgCycleTime" BO_ 564 100;
BA_ "GenMsgSendType" BO_ 564 0;
BA_ "Prio" BO_ 313 0;
BA_ "MessageSubnet" BO_ 313 2;
BA_ "GenMsgCycleTime" BO_ 313 100;
BA_ "GenMsgSendType" BO_ 313 0;
BA_ "Prio" BO_ 818 0;
BA_ "MessageSubnet" BO_ 818 2;
BA_ "GenMsgCycleTime" BO_ 818 100;
BA_ "GenMsgSendType" BO_ 818 0;
BA_ "Prio" BO_ 1328 0;
BA_ "MessageSubnet" BO_ 1328 2;
BA_ "GenMsgCycleTime" BO_ 1328 1000;
BA_ "GenMsgSendType" BO_ 1328 0;
BA_ "Prio" BO_ 1296 0;
BA_ "MessageSubnet" BO_ 1296 2;
BA_ "GenMsgCycleTime" BO_ 1296 100;
BA_ "GenMsgSendType" BO_ 1296 0;
BA_ "Prio" BO_ 311 0;
BA_ "MessageSubnet" BO_ 311 2;
BA_ "GenMsgCycleTime" BO_ 311 100;
BA_ "GenMsgSendType" BO_ 311 0;
BA_ "Prio" BO_ 536 0;
BA_ "MessageSubnet" BO_ 536 2;
BA_ "GenMsgCycleTime" BO_ 536 200;
BA_ "GenMsgSendType" BO_ 536 0;
BA_ "Prio" BO_ 570 0;
BA_ "MessageSubnet" BO_ 570 2;
BA_ "GenMsgCycleTime" BO_ 570 200;
BA_ "GenMsgSendType" BO_ 570 0;
BA_ "Prio" BO_ 810 0;
BA_ "MessageSubnet" BO_ 810 2;
BA_ "GenMsgCycleTime" BO_ 810 100;
BA_ "GenMsgSendType" BO_ 810 0;
BA_ "Prio" BO_ 848 0;
BA_ "MessageSubnet" BO_ 848 2;
BA_ "GenMsgCycleTime" BO_ 848 50;
BA_ "GenMsgSendType" BO_ 848 0;
BA_ "Prio" BO_ 953 0;
BA_ "MessageSubnet" BO_ 953 2;
BA_ "GenMsgCycleTime" BO_ 953 100;
BA_ "GenMsgSendType" BO_ 953 0;
BA_ "Prio" BO_ 711 0;
BA_ "MessageSubnet" BO_ 711 2;
BA_ "GenMsgCycleTime" BO_ 711 25;
BA_ "GenMsgSendType" BO_ 711 0;
BA_ "Prio" BO_ 1011 0;
BA_ "MessageSubnet" BO_ 1011 2;
BA_ "GenMsgCycleTime" BO_ 1011 500;
BA_ "GenMsgSendType" BO_ 1011 0;
BA_ "Prio" BO_ 304 0;
BA_ "MessageSubnet" BO_ 304 2;
BA_ "GenMsgCycleTime" BO_ 304 1000;
BA_ "GenMsgSendType" BO_ 304 0;
BA_ "Prio" BO_ 1105 0;
BA_ "MessageSubnet" BO_ 1105 2;
BA_ "GenMsgCycleTime" BO_ 1105 25;
BA_ "GenMsgSendType" BO_ 1105 0;
BA_ "Prio" BO_ 1005 0;
BA_ "MessageSubnet" BO_ 1005 2;
BA_ "GenMsgCycleTime" BO_ 1005 250;
BA_ "GenMsgSendType" BO_ 1005 0;
BA_ "Prio" BO_ 688 0;
BA_ "MessageSubnet" BO_ 688 2;
BA_ "GenMsgCycleTime" BO_ 688 20;
BA_ "GenMsgSendType" BO_ 688 0;
BA_ "Prio" BO_ 993 0;
BA_ "MessageSubnet" BO_ 993 2;
BA_ "GenMsgCycleTime" BO_ 993 100;
BA_ "GenMsgSendType" BO_ 993 0;
BA_ "Prio" BO_ 490 0;
BA_ "MessageSubnet" BO_ 490 2;
BA_ "GenMsgCycleTime" BO_ 490 12;
BA_ "GenMsgSendType" BO_ 490 0;
BA_ "Prio" BO_ 431 0;
BA_ "MessageSubnet" BO_ 431 2;
BA_ "GenMsgCycleTime" BO_ 431 25;
BA_ "GenMsgSendType" BO_ 431 0;
BA_ "AppGenMsgCycleTime" BO_ 715 40;
BA_ "Prio" BO_ 715 0;
BA_ "MessageSubnet" BO_ 715 2;
BA_ "Prio" BO_ 1267 0;
BA_ "MessageSubnet" BO_ 1267 2;
BA_ "GenMsgCycleTime" BO_ 1267 1000;
BA_ "GenMsgSendType" BO_ 1267 0;
BA_ "Prio" BO_ 453 0;
BA_ "MessageSubnet" BO_ 453 2;
BA_ "GenMsgCycleTime" BO_ 453 25;
BA_ "GenMsgSendType" BO_ 453 0;
BA_ "SignalType" SG_ 647 DrvMntnMdCmnd "BLN";
BA_ "SignalLongName" SG_ 647 DrvMntnMdCmnd "Driver Mountain Mode Commanded";
BA_ "VNSigAllNodes" SG_ 647 DrvMntnMdCmnd 1;
BA_ "SignalType" SG_ 647 DrvHldMdCmnd "BLN";
BA_ "SignalLongName" SG_ 647 DrvHldMdCmnd "Driver Hold Mode Commanded";
BA_ "VNSigAllNodes" SG_ 647 DrvHldMdCmnd 1;
BA_ "SignalType" SG_ 647 DrPTGrdBrkDsbMdCmd "BLN";
BA_ "SignalLongName" SG_ 647 DrPTGrdBrkDsbMdCmd "Driver Powertrain Grade Braking Disable Mode Commanded";
BA_ "VNSigAllNodes" SG_ 647 DrPTGrdBrkDsbMdCmd 1;
BA_ "SignalType" SG_ 647 DrvWntrMdCmd "BLN";
BA_ "SignalLongName" SG_ 647 DrvWntrMdCmd "Driver Winter Mode Commanded";
BA_ "VNSigAllNodes" SG_ 647 DrvWntrMdCmd 1;
BA_ "SignalType" SG_ 647 DrvTwHaulMdCmd "BLN";
BA_ "SignalLongName" SG_ 647 DrvTwHaulMdCmd "Driver Tow Haul Mode Commanded";
BA_ "VNSigAllNodes" SG_ 647 DrvTwHaulMdCmd 1;
BA_ "SignalType" SG_ 647 DrvSprtMdCmd "BLN";
BA_ "SignalLongName" SG_ 647 DrvSprtMdCmd "Driver Sport Mode Commanded";
BA_ "VNSigAllNodes" SG_ 647 DrvSprtMdCmd 1;
BA_ "SignalType" SG_ 647 DrvEconMdCmd "BLN";
BA_ "SignalLongName" SG_ 647 DrvEconMdCmd "Driver Economy Mode Commanded";
BA_ "VNSigAllNodes" SG_ 647 DrvEconMdCmd 1;
BA_ "SignalType" SG_ 647 EngCntrlDtrmdTrfCRngV "ENM";
BA_ "SignalLongName" SG_ 647 EngCntrlDtrmdTrfCRngV "Engine Controller Determined Transfer Case Range Validity";
BA_ "VNSigAllNodes" SG_ 647 EngCntrlDtrmdTrfCRngV 1;
BA_ "SignalType" SG_ 647 EngCntrlDtrmdTrfCRng "ENM";
BA_ "SignalLongName" SG_ 647 EngCntrlDtrmdTrfCRng "Engine Controller Determined Transfer Case Range";
BA_ "VNSigAllNodes" SG_ 647 EngCntrlDtrmdTrfCRng 1;
BA_ "SignalType" SG_ 647 EngCtrlUtldTrnCRgPVal "UNM";
BA_ "SignalLongName" SG_ 647 EngCtrlUtldTrnCRgPVal "Engine Controller Utilized Transfer Case Range Protection Value";
BA_ "VNSigAllNodes" SG_ 647 EngCtrlUtldTrnCRgPVal 1;
BA_ "SignalType" SG_ 647 EngCntrlUtldTrnCsRng "ENM";
BA_ "SignalLongName" SG_ 647 EngCntrlUtldTrnCsRng "Engine Controller Utilized Transfer Case Range";
BA_ "VNSigAllNodes" SG_ 647 EngCntrlUtldTrnCsRng 1;
BA_ "SignalType" SG_ 647 EngCntrlUtldTrnCsRgIn "BLN";
BA_ "SignalLongName" SG_ 647 EngCntrlUtldTrnCsRgIn "Engine Controller Utilized Transfer Case Range Inconsistent";
BA_ "VNSigAllNodes" SG_ 647 EngCntrlUtldTrnCsRgIn 1;
BA_ "SignalType" SG_ 647 EngCtrlUtldTrnCRgARC "UNM";
BA_ "SignalLongName" SG_ 647 EngCtrlUtldTrnCRgARC "Engine Controller Utilized Transfer Case Range Alive Rolling Count";
BA_ "VNSigAllNodes" SG_ 647 EngCtrlUtldTrnCRgARC 1;
BA_ "SignalType" SG_ 368 EnvIdRspSt5 "ENM";
BA_ "SignalLongName" SG_ 368 EnvIdRspSt5 "Environment Identification Response Status 5";
BA_ "VNSigAllNodes" SG_ 368 EnvIdRspSt5 1;
BA_ "SignalType" SG_ 368 EnvIdRsp5 "UNM";
BA_ "SignalLongName" SG_ 368 EnvIdRsp5 "Environment Identification Response 5";
BA_ "VNSigAllNodes" SG_ 368 EnvIdRsp5 1;
BA_ "SignalType" SG_ 995 RdHVltBatMaxSnsTmpV "ENM";
BA_ "SignalLongName" SG_ 995 RdHVltBatMaxSnsTmpV "Redundant High Voltage Battery Maximum Sensor Temperature Validity";
BA_ "VNSigAllNodes" SG_ 995 RdHVltBatMaxSnsTmpV 1;
BA_ "SignalType" SG_ 995 RdHVltBatMaxSnsTmpM "ENM";
BA_ "SignalLongName" SG_ 995 RdHVltBatMaxSnsTmpM "Redundant High Voltage Battery Maximum Sensor Temperature Mask";
BA_ "VNSigAllNodes" SG_ 995 RdHVltBatMaxSnsTmpM 1;
BA_ "SignalType" SG_ 995 RdHVltBatMinClVltV "ENM";
BA_ "SignalLongName" SG_ 995 RdHVltBatMinClVltV "Redundant High Voltage Battery Minimum Cell Voltage Validity";
BA_ "VNSigAllNodes" SG_ 995 RdHVltBatMinClVltV 1;
BA_ "SignalType" SG_ 995 RdHVltBatMinClVltM "ENM";
BA_ "SignalLongName" SG_ 995 RdHVltBatMinClVltM "Redundant High Voltage Battery Minimum Cell Voltage Mask";
BA_ "VNSigAllNodes" SG_ 995 RdHVltBatMinClVltM 1;
BA_ "SignalType" SG_ 995 RdHVBatMinSnsTmpV "ENM";
BA_ "SignalLongName" SG_ 995 RdHVBatMinSnsTmpV "Redundant High Voltage Battery Minimum Sensor Temperature Validity";
BA_ "VNSigAllNodes" SG_ 995 RdHVBatMinSnsTmpV 1;
BA_ "SignalType" SG_ 995 RdHVBatMinSnsTmpM "ENM";
BA_ "SignalLongName" SG_ 995 RdHVBatMinSnsTmpM "Redundant High Voltage Battery Minimum Sensor Temperature Mask";
BA_ "VNSigAllNodes" SG_ 995 RdHVBatMinSnsTmpM 1;
BA_ "SignalType" SG_ 995 RdHVBatMinSnsTmp "UNM";
BA_ "SignalLongName" SG_ 995 RdHVBatMinSnsTmp "Redundant High Voltage Battery Minimum Sensor Temperature";
BA_ "VNSigAllNodes" SG_ 995 RdHVBatMinSnsTmp 1;
BA_ "SignalType" SG_ 995 RdHVltBatMaxClVltV "ENM";
BA_ "SignalLongName" SG_ 995 RdHVltBatMaxClVltV "Redundant High Voltage Battery Maximum Cell Voltage Validity";
BA_ "VNSigAllNodes" SG_ 995 RdHVltBatMaxClVltV 1;
BA_ "SignalType" SG_ 995 RdHVltBatMaxClVltM "ENM";
BA_ "SignalLongName" SG_ 995 RdHVltBatMaxClVltM "Redundant High Voltage Battery Maximum Cell Voltage Mask";
BA_ "VNSigAllNodes" SG_ 995 RdHVltBatMaxClVltM 1;
BA_ "SignalType" SG_ 995 RdHVltBatMinClVlt "UNM";
BA_ "SignalLongName" SG_ 995 RdHVltBatMinClVlt "Redundant High Voltage Battery Minimum Cell Voltage";
BA_ "VNSigAllNodes" SG_ 995 RdHVltBatMinClVlt 1;
BA_ "SignalType" SG_ 995 RdHVltBatMaxSnsTmp "UNM";
BA_ "SignalLongName" SG_ 995 RdHVltBatMaxSnsTmp "Redundant High Voltage Battery Maximum Sensor Temperature";
BA_ "VNSigAllNodes" SG_ 995 RdHVltBatMaxSnsTmp 1;
BA_ "SignalType" SG_ 995 RdHVltBatMaxClVlt "UNM";
BA_ "SignalLongName" SG_ 995 RdHVltBatMaxClVlt "Redundant High Voltage Battery Maximum Cell Voltage";
BA_ "VNSigAllNodes" SG_ 995 RdHVltBatMaxClVlt 1;
BA_ "SignalType" SG_ 995 RdHVltBatAvgClVltV "ENM";
BA_ "SignalLongName" SG_ 995 RdHVltBatAvgClVltV "Redundant High Voltage Battery Average Cell Voltage Validity";
BA_ "VNSigAllNodes" SG_ 995 RdHVltBatAvgClVltV 1;
BA_ "SignalType" SG_ 995 RdHVltBatAvgClVltM "ENM";
BA_ "SignalLongName" SG_ 995 RdHVltBatAvgClVltM "Redundant High Voltage Battery Average Cell Voltage Mask";
BA_ "VNSigAllNodes" SG_ 995 RdHVltBatAvgClVltM 1;
BA_ "SignalType" SG_ 995 RdHVltBatAvgClVlt "UNM";
BA_ "SignalLongName" SG_ 995 RdHVltBatAvgClVlt "Redundant High Voltage Battery Average Cell Voltage";
BA_ "VNSigAllNodes" SG_ 995 RdHVltBatAvgClVlt 1;
BA_ "SignalType" SG_ 971 BatVltHiResV "ENM";
BA_ "SignalLongName" SG_ 971 BatVltHiResV "Battery Voltage High Resolution Validity";
BA_ "VNSigAllNodes" SG_ 971 BatVltHiResV 1;
BA_ "SignalType" SG_ 971 BatVltHiRes "UNM";
BA_ "SignalLongName" SG_ 971 BatVltHiRes "Battery Voltage High Resolution";
BA_ "VNSigAllNodes" SG_ 971 BatVltHiRes 1;
BA_ "SignalType" SG_ 971 BCHR_BattCrntRwVal "UNM";
BA_ "PacketOrder" SG_ 971 BCHR_BattCrntRwVal 3;
BA_ "SignalLongName" SG_ 971 BCHR_BattCrntRwVal "Battery Current High Resolution : Battery Current Raw Value";
BA_ "VNSigAllNodes" SG_ 971 BCHR_BattCrntRwVal 1;
BA_ "SignalType" SG_ 971 BCHR_BattCrntRwVlMu "ENM";
BA_ "PacketOrder" SG_ 971 BCHR_BattCrntRwVlMu 2;
BA_ "SignalLongName" SG_ 971 BCHR_BattCrntRwVlMu "Battery Current High Resolution : Battery Current Raw Value Multiplier";
BA_ "VNSigAllNodes" SG_ 971 BCHR_BattCrntRwVlMu 1;
BA_ "SignalType" SG_ 971 BCHR_BattCrntRwValV "ENM";
BA_ "PacketOrder" SG_ 971 BCHR_BattCrntRwValV 1;
BA_ "SignalLongName" SG_ 971 BCHR_BattCrntRwValV "Battery Current High Resolution : Battery Current Raw Value Validity";
BA_ "VNSigAllNodes" SG_ 971 BCHR_BattCrntRwValV 1;
BA_ "SignalType" SG_ 209 ChsBrkPdlPsERltdV "ENM";
BA_ "SignalLongName" SG_ 209 ChsBrkPdlPsERltdV "Chassis Brake Pedal Position Emissions Related Validity";
BA_ "VNSigAllNodes" SG_ 209 ChsBrkPdlPsERltdV 1;
BA_ "SignalType" SG_ 209 ChsBrkPdlPsERltdPVal "UNM";
BA_ "SignalLongName" SG_ 209 ChsBrkPdlPsERltdPVal "Chassis Brake Pedal Position Emissions Related Protection Value";
BA_ "VNSigAllNodes" SG_ 209 ChsBrkPdlPsERltdPVal 1;
BA_ "SignalType" SG_ 209 ChsBrkPdlPsERltdARC "UNM";
BA_ "SignalLongName" SG_ 209 ChsBrkPdlPsERltdARC "Chassis Brake Pedal Position Emissions Related Alive Rolling Count";
BA_ "VNSigAllNodes" SG_ 209 ChsBrkPdlPsERltdARC 1;
BA_ "SignalType" SG_ 209 ChsBrkPdlPsERltd "UNM";
BA_ "SignalLongName" SG_ 209 ChsBrkPdlPsERltd "Chassis Brake Pedal Position Emissions Related";
BA_ "VNSigAllNodes" SG_ 209 ChsBrkPdlPsERltd 1;
BA_ "SignalType" SG_ 209 DrvIntndTtlBrkTrqPVal "UNM";
BA_ "SignalLongName" SG_ 209 DrvIntndTtlBrkTrqPVal "Driver Intended Total Brake Torque Protection Value";
BA_ "VNSigAllNodes" SG_ 209 DrvIntndTtlBrkTrqPVal 1;
BA_ "SignalType" SG_ 209 DrvIntndTtlBrkTrqARC "UNM";
BA_ "SignalLongName" SG_ 209 DrvIntndTtlBrkTrqARC "Driver Intended Total Brake Torque Alive Rolling Count";
BA_ "VNSigAllNodes" SG_ 209 DrvIntndTtlBrkTrqARC 1;
BA_ "SignalType" SG_ 209 DrvIntndTtlBrkTrq "UNM";
BA_ "SignalLongName" SG_ 209 DrvIntndTtlBrkTrq "Driver Intended Total Brake Torque";
BA_ "VNSigAllNodes" SG_ 209 DrvIntndTtlBrkTrq 1;
BA_ "SignalType" SG_ 454 ChsSysPrdAxlTqRqPV "UNM";
BA_ "SignalLongName" SG_ 454 ChsSysPrdAxlTqRqPV "Chassis System Predicted Axle Torque Request Protection Value";
BA_ "VNSigAllNodes" SG_ 454 ChsSysPrdAxlTqRqPV 1;
BA_ "SignalType" SG_ 454 CSPATR_TrqIntrvnTyp "ENM";
BA_ "PacketOrder" SG_ 454 CSPATR_TrqIntrvnTyp 3;
BA_ "SignalLongName" SG_ 454 CSPATR_TrqIntrvnTyp "Chassis System Predicted Axle Torque Request : Torque Intervention Type";
BA_ "VNSigAllNodes" SG_ 454 CSPATR_TrqIntrvnTyp 1;
BA_ "SignalType" SG_ 454 CSPATR_PrdTrqRqVal "UNM";
BA_ "PacketOrder" SG_ 454 CSPATR_PrdTrqRqVal 2;
BA_ "SignalLongName" SG_ 454 CSPATR_PrdTrqRqVal "Chassis System Predicted Axle Torque Request : Predicted Torque Request Value";
BA_ "VNSigAllNodes" SG_ 454 CSPATR_PrdTrqRqVal 1;
BA_ "SignalType" SG_ 454 CSPATR_TrqRqTyp "ENM";
BA_ "PacketOrder" SG_ 454 CSPATR_TrqRqTyp 1;
BA_ "SignalLongName" SG_ 454 CSPATR_TrqRqTyp "Chassis System Predicted Axle Torque Request : Torque Request Type";
BA_ "VNSigAllNodes" SG_ 454 CSPATR_TrqRqTyp 1;
BA_ "SignalType" SG_ 454 ChsSysImmAxlTqRqVal "UNM";
BA_ "SignalLongName" SG_ 454 ChsSysImmAxlTqRqVal "Chassis System Immediate Axle Torque Request Value";
BA_ "VNSigAllNodes" SG_ 454 ChsSysImmAxlTqRqVal 1;
BA_ "SignalType" SG_ 454 ChsSysAxlTqRqRspTyp "ENM";
BA_ "SignalLongName" SG_ 454 ChsSysAxlTqRqRspTyp "Chassis System Axle Torque Request Response Type";
BA_ "VNSigAllNodes" SG_ 454 ChsSysAxlTqRqRspTyp 1;
BA_ "SignalType" SG_ 454 ChsSysPrdAxlTqRqARC "UNM";
BA_ "SignalLongName" SG_ 454 ChsSysPrdAxlTqRqARC "Chassis System Predicted Axle Torque Request Alive Rolling Count";
BA_ "VNSigAllNodes" SG_ 454 ChsSysPrdAxlTqRqARC 1;
BA_ "SignalType" SG_ 554 ElecPrkBrkApplStatPV "UNM";
BA_ "SignalLongName" SG_ 554 ElecPrkBrkApplStatPV "Electric Park Brake Application Status Protection Value";
BA_ "VNSigAllNodes" SG_ 554 ElecPrkBrkApplStatPV 1;
BA_ "SignalType" SG_ 554 ElecPrkBrkAvailStatPV "UNM";
BA_ "SignalLongName" SG_ 554 ElecPrkBrkAvailStatPV "Electric Park Brake Availability Status Protection Value";
BA_ "VNSigAllNodes" SG_ 554 ElecPrkBrkAvailStatPV 1;
BA_ "SignalType" SG_ 554 ElecPrkBrkAvailStat "ENM";
BA_ "SignalLongName" SG_ 554 ElecPrkBrkAvailStat "Electric Park Brake Availability Status";
BA_ "VNSigAllNodes" SG_ 554 ElecPrkBrkAvailStat 1;
BA_ "SignalType" SG_ 554 ElecPrkBrkStatRC "UNM";
BA_ "SignalLongName" SG_ 554 ElecPrkBrkStatRC "Electric Park Brake Status Rolling Count";
BA_ "VNSigAllNodes" SG_ 554 ElecPrkBrkStatRC 1;
BA_ "SignalType" SG_ 554 ElecPrkBrkApplStat "ENM";
BA_ "SignalLongName" SG_ 554 ElecPrkBrkApplStat "Electric Park Brake Application Status";
BA_ "VNSigAllNodes" SG_ 554 ElecPrkBrkApplStat 1;
BA_ "SignalType" SG_ 487 CmmndAirFuelRatio "UNM";
BA_ "SignalLongName" SG_ 487 CmmndAirFuelRatio "Commanded Air Fuel Ratio";
BA_ "VNSigAllNodes" SG_ 487 CmmndAirFuelRatio 1;
BA_ "SignalType" SG_ 487 InstFuelFlowEst "UNM";
BA_ "SignalLongName" SG_ 487 InstFuelFlowEst "Instantaneous Fuel Flow Estimate";
BA_ "VNSigAllNodes" SG_ 487 InstFuelFlowEst 1;
BA_ "SignalType" SG_ 487 FuelDelPressRqd "UNM";
BA_ "SignalLongName" SG_ 487 FuelDelPressRqd "Fuel Delivery Pressure Requested";
BA_ "VNSigAllNodes" SG_ 487 FuelDelPressRqd 1;
BA_ "SignalType" SG_ 487 EngRunng "BLN";
BA_ "SignalLongName" SG_ 487 EngRunng "Engine Running";
BA_ "VNSigAllNodes" SG_ 487 EngRunng 1;
BA_ "SignalType" SG_ 487 FlPmpEDscOtptCmdSta "ENM";
BA_ "SignalLongName" SG_ 487 FlPmpEDscOtptCmdSta "Fuel Pump Enabled Discrete Output Commanded Status";
BA_ "VNSigAllNodes" SG_ 487 FlPmpEDscOtptCmdSta 1;
BA_ "SignalType" SG_ 487 FuelCntlSysFltPrsnt "BLN";
BA_ "SignalLongName" SG_ 487 FuelCntlSysFltPrsnt "Fuel Control System Fault Present";
BA_ "VNSigAllNodes" SG_ 487 FuelCntlSysFltPrsnt 1;
BA_ "SignalType" SG_ 487 HiPresFuelPmpDelDur "UNM";
BA_ "SignalLongName" SG_ 487 HiPresFuelPmpDelDur "High Pressure Fuel Pump Delivery Duration";
BA_ "VNSigAllNodes" SG_ 487 HiPresFuelPmpDelDur 1;
BA_ "SignalType" SG_ 487 HiPresFuelPmpCntMd "ENM";
BA_ "SignalLongName" SG_ 487 HiPresFuelPmpCntMd "High Pressure Fuel Pump Control Mode";
BA_ "VNSigAllNodes" SG_ 487 HiPresFuelPmpCntMd 1;
BA_ "SignalType" SG_ 566 RdHVBatLwParMdReq "BLN";
BA_ "SignalLongName" SG_ 566 RdHVBatLwParMdReq "Redundant High Voltage Battery Low Parasitic Mode Requested";
BA_ "VNSigAllNodes" SG_ 566 RdHVBatLwParMdReq 1;
BA_ "SignalType" SG_ 566 RdHVBtClOVFFTstRq "BLN";
BA_ "SignalLongName" SG_ 566 RdHVBtClOVFFTstRq "Redundant High Voltage Battery Cell Over Voltage Fault Flag Test Req";
BA_ "VNSigAllNodes" SG_ 566 RdHVBtClOVFFTstRq 1;
BA_ "SignalType" SG_ 566 RdHVBtClOVFFTstIdx "UNM";
BA_ "SignalLongName" SG_ 566 RdHVBtClOVFFTstIdx "Redundant High Voltage Battery Cell Over Voltage Fault Flag Test Index";
BA_ "VNSigAllNodes" SG_ 566 RdHVBtClOVFFTstIdx 1;
BA_ "SignalType" SG_ 566 ClimCtrlHVDvcShtdwnCmd "BLN";
BA_ "SignalLongName" SG_ 566 ClimCtrlHVDvcShtdwnCmd "Climate Control High Voltage Device Shutdown Commanded";
BA_ "VNSigAllNodes" SG_ 566 ClimCtrlHVDvcShtdwnCmd 1;
BA_ "SignalType" SG_ 566 VICntlModRunCrkTrmSt "ENM";
BA_ "SignalLongName" SG_ 566 VICntlModRunCrkTrmSt "Vehicle Integration Control Module Run Crank Terminal Status";
BA_ "VNSigAllNodes" SG_ 566 VICntlModRunCrkTrmSt 1;
BA_ "SignalType" SG_ 566 VICMHVEnMgCmEnTrS "ENM";
BA_ "SignalLongName" SG_ 566 VICMHVEnMgCmEnTrS "VICM High Voltage Energy Management Comm Enable Terminal Status";
BA_ "VNSigAllNodes" SG_ 566 VICMHVEnMgCmEnTrS 1;
BA_ "SignalType" SG_ 566 ChrgSysPrkBrkAnmsBrkReqPVal "UNM";
BA_ "SignalLongName" SG_ 566 ChrgSysPrkBrkAnmsBrkReqPVal "Charging System Park Brake Autonomous Apply Request Protection Value";
BA_ "VNSigAllNodes" SG_ 566 ChrgSysPrkBrkAnmsBrkReqPVal 1;
BA_ "SignalType" SG_ 566 ChrgSysPrkBrkAnmsBrkReqARC "UNM";
BA_ "SignalLongName" SG_ 566 ChrgSysPrkBrkAnmsBrkReqARC "Charging System Park Brake Autonomous Apply Request Alive Rolling Count";
BA_ "VNSigAllNodes" SG_ 566 ChrgSysPrkBrkAnmsBrkReqARC 1;
BA_ "SignalType" SG_ 566 ChrgSysPrkBrkAnmsBrkReq "BLN";
BA_ "SignalLongName" SG_ 566 ChrgSysPrkBrkAnmsBrkReq "Charging System Park Brake Autonomous Apply Request";
BA_ "VNSigAllNodes" SG_ 566 ChrgSysPrkBrkAnmsBrkReq 1;
BA_ "SignalType" SG_ 566 VICMClrLgsDgInfo "BLN";
BA_ "SignalLongName" SG_ 566 VICMClrLgsDgInfo "Vehicle Integration Controller Module Clear Legislative Diagnostic Info";
BA_ "VNSigAllNodes" SG_ 566 VICMClrLgsDgInfo 1;
BA_ "SignalType" SG_ 566 HybVehHiVltSysDisbld_236 "BLN";
BA_ "SignalLongName" SG_ 566 HybVehHiVltSysDisbld_236 "Hybrid Vehicle High Voltage System Disabled";
BA_ "VNSigAllNodes" SG_ 566 HybVehHiVltSysDisbld_236 1;
BA_ "SignalType" SG_ 566 ThrmlRefCompSpdReq "UNM";
BA_ "SignalLongName" SG_ 566 ThrmlRefCompSpdReq "Thermal Refrigerant Compressor Speed Request";
BA_ "VNSigAllNodes" SG_ 566 ThrmlRefCompSpdReq 1;
BA_ "SignalType" SG_ 421 AccPwrMdlHiVltInpCrnt "UNM";
BA_ "SignalLongName" SG_ 421 AccPwrMdlHiVltInpCrnt "Accessory Power Module High Voltage Input Current";
BA_ "GenSigStartValue" SG_ 421 AccPwrMdlHiVltInpCrnt 40;
BA_ "VNSigAllNodes" SG_ 421 AccPwrMdlHiVltInpCrnt 1;
BA_ "SignalType" SG_ 421 AccPwrMdlHiVltInpCrntV "ENM";
BA_ "SignalLongName" SG_ 421 AccPwrMdlHiVltInpCrntV "Accessory Power Module High Voltage Input Current Validity";
BA_ "VNSigAllNodes" SG_ 421 AccPwrMdlHiVltInpCrntV 1;
BA_ "SignalType" SG_ 421 HTGR_ReqVal "ENM";
BA_ "SignalLongName" SG_ 421 HTGR_ReqVal "Hybrid Transmission Gear Request : Request Value";
BA_ "VNSigAllNodes" SG_ 421 HTGR_ReqVal 1;
BA_ "SignalType" SG_ 421 HTGR_ReqTyp "ENM";
BA_ "SignalLongName" SG_ 421 HTGR_ReqTyp "Hybrid Transmission Gear Request : Request Type";
BA_ "VNSigAllNodes" SG_ 421 HTGR_ReqTyp 1;
BA_ "SignalType" SG_ 421 HTGR_ReqPrty "ENM";
BA_ "SignalLongName" SG_ 421 HTGR_ReqPrty "Hybrid Transmission Gear Request : Request Priority";
BA_ "VNSigAllNodes" SG_ 421 HTGR_ReqPrty 1;
BA_ "SignalType" SG_ 421 HTCCR_ReqVal "ENM";
BA_ "SignalLongName" SG_ 421 HTCCR_ReqVal "Hybrid Torque Converter Clutch Request : Request Value";
BA_ "VNSigAllNodes" SG_ 421 HTCCR_ReqVal 1;
BA_ "SignalType" SG_ 421 HTCCR_ReqPrty "ENM";
BA_ "SignalLongName" SG_ 421 HTCCR_ReqPrty "Hybrid Torque Converter Clutch Request : Request Priority";
BA_ "VNSigAllNodes" SG_ 421 HTCCR_ReqPrty 1;
BA_ "SignalType" SG_ 421 TrnsAuxPmpAct "BLN";
BA_ "SignalLongName" SG_ 421 TrnsAuxPmpAct "Transmission Auxiliary Pump Active";
BA_ "VNSigAllNodes" SG_ 421 TrnsAuxPmpAct 1;
BA_ "SignalType" SG_ 421 HybSnsBrkPdlPosV "ENM";
BA_ "SignalLongName" SG_ 421 HybSnsBrkPdlPosV "Hybrid Sensed Brake Pedal Position Validity";
BA_ "VNSigAllNodes" SG_ 421 HybSnsBrkPdlPosV 1;
BA_ "SignalType" SG_ 421 HybSnsBrkPdlPosPVal "UNM";
BA_ "SignalLongName" SG_ 421 HybSnsBrkPdlPosPVal "Hybrid Sensed Brake Pedal Position Protection Value";
BA_ "VNSigAllNodes" SG_ 421 HybSnsBrkPdlPosPVal 1;
BA_ "SignalType" SG_ 421 HybSnsBrkPdlPosARC "UNM";
BA_ "SignalLongName" SG_ 421 HybSnsBrkPdlPosARC "Hybrid Sensed Brake Pedal Position Alive Rolling Count";
BA_ "VNSigAllNodes" SG_ 421 HybSnsBrkPdlPosARC 1;
BA_ "SignalType" SG_ 421 HybSnsBrkPdlPos "UNM";
BA_ "SignalLongName" SG_ 421 HybSnsBrkPdlPos "Hybrid Sensed Brake Pedal Position";
BA_ "VNSigAllNodes" SG_ 421 HybSnsBrkPdlPos 1;
BA_ "SignalType" SG_ 456 PerfTrcEngSpdReqProt "UNM";
BA_ "SignalLongName" SG_ 456 PerfTrcEngSpdReqProt "Performance Traction Engine Speed Request Protection";
BA_ "VNSigAllNodes" SG_ 456 PerfTrcEngSpdReqProt 1;
BA_ "SignalType" SG_ 456 PTESR_EngSpdRqVal "UNM";
BA_ "PacketOrder" SG_ 456 PTESR_EngSpdRqVal 3;
BA_ "SignalLongName" SG_ 456 PTESR_EngSpdRqVal "Performance Traction Engine Speed Request : Engine Speed Request Value";
BA_ "VNSigAllNodes" SG_ 456 PTESR_EngSpdRqVal 1;
BA_ "SignalType" SG_ 456 PTESR_EngSpdCntlRs "ENM";
BA_ "PacketOrder" SG_ 456 PTESR_EngSpdCntlRs 2;
BA_ "SignalLongName" SG_ 456 PTESR_EngSpdCntlRs "Performance Traction Engine Speed Request : Engine Speed Control Response";
BA_ "VNSigAllNodes" SG_ 456 PTESR_EngSpdCntlRs 1;
BA_ "SignalType" SG_ 456 PTESR_EngSpdIntTyp "ENM";
BA_ "PacketOrder" SG_ 456 PTESR_EngSpdIntTyp 1;
BA_ "SignalLongName" SG_ 456 PTESR_EngSpdIntTyp "Performance Traction Engine Speed Request : Engine Speed Intervention Type";
BA_ "VNSigAllNodes" SG_ 456 PTESR_EngSpdIntTyp 1;
BA_ "SignalType" SG_ 456 PerfTrcTrqRqProt "UNM";
BA_ "SignalLongName" SG_ 456 PerfTrcTrqRqProt "Performance Traction Torque Request Protection";
BA_ "VNSigAllNodes" SG_ 456 PerfTrcTrqRqProt 1;
BA_ "SignalType" SG_ 456 PTTR_TrqReqVal "UNM";
BA_ "PacketOrder" SG_ 456 PTTR_TrqReqVal 3;
BA_ "SignalLongName" SG_ 456 PTTR_TrqReqVal "Performance Traction Torque Request : Torque Request Value";
BA_ "VNSigAllNodes" SG_ 456 PTTR_TrqReqVal 1;
BA_ "SignalType" SG_ 456 PTTR_TrqRedRlzSugg "ENM";
BA_ "PacketOrder" SG_ 456 PTTR_TrqRedRlzSugg 2;
BA_ "SignalLongName" SG_ 456 PTTR_TrqRedRlzSugg "Performance Traction Torque Request : Torque Reduction Realization Suggestion";
BA_ "VNSigAllNodes" SG_ 456 PTTR_TrqRedRlzSugg 1;
BA_ "SignalType" SG_ 456 PTTR_TrqInvTyp "ENM";
BA_ "PacketOrder" SG_ 456 PTTR_TrqInvTyp 1;
BA_ "SignalLongName" SG_ 456 PTTR_TrqInvTyp "Performance Traction Torque Request : Torque Intervention Type";
BA_ "VNSigAllNodes" SG_ 456 PTTR_TrqInvTyp 1;
BA_ "SignalType" SG_ 456 PerfTrcARC "UNM";
BA_ "SignalLongName" SG_ 456 PerfTrcARC "Performance Traction Alive Rolling Count";
BA_ "VNSigAllNodes" SG_ 456 PerfTrcARC 1;
BA_ "SignalType" SG_ 884 AdvWthrStat "ENM";
BA_ "SignalLongName" SG_ 884 AdvWthrStat "Adverse Weather Status";
BA_ "VNSigAllNodes" SG_ 884 AdvWthrStat 1;
BA_ "SignalType" SG_ 884 RgDtLgtSrcHrtAngVcty "SNM";
BA_ "SignalLongName" SG_ 884 RgDtLgtSrcHrtAngVcty "Right Detected Light Source Horizontal Angular Velocity";
BA_ "VNSigAllNodes" SG_ 884 RgDtLgtSrcHrtAngVcty 1;
BA_ "SignalType" SG_ 884 RgDtLgtSrcHrtAngl "SNM";
BA_ "SignalLongName" SG_ 884 RgDtLgtSrcHrtAngl "Right Detected Light Source Horizontal Angle";
BA_ "VNSigAllNodes" SG_ 884 RgDtLgtSrcHrtAngl 1;
BA_ "SignalType" SG_ 884 LfDtLgtSrcHrtAnVcty "SNM";
BA_ "SignalLongName" SG_ 884 LfDtLgtSrcHrtAnVcty "Left Detected Light Source Horizontal Angular Velocity";
BA_ "VNSigAllNodes" SG_ 884 LfDtLgtSrcHrtAnVcty 1;
BA_ "SignalType" SG_ 884 LfDtLgtSrcHrtAngl "SNM";
BA_ "SignalLongName" SG_ 884 LfDtLgtSrcHrtAngl "Left Detected Light Source Horizontal Angle";
BA_ "VNSigAllNodes" SG_ 884 LfDtLgtSrcHrtAngl 1;
BA_ "SignalType" SG_ 884 DtctdLghtSrcDstnc "UNM";
BA_ "SignalLongName" SG_ 884 DtctdLghtSrcDstnc "Detected Light Source Distance";
BA_ "VNSigAllNodes" SG_ 884 DtctdLghtSrcDstnc 1;
BA_ "SignalType" SG_ 884 DtctdLghtSrcVrtclAngl "SNM";
BA_ "SignalLongName" SG_ 884 DtctdLghtSrcVrtclAngl "Detected Light Source Vertical Angle";
BA_ "VNSigAllNodes" SG_ 884 DtctdLghtSrcVrtclAngl 1;
BA_ "SignalType" SG_ 884 DtctdLghtSrcDrvngDrctn "ENM";
BA_ "SignalLongName" SG_ 884 DtctdLghtSrcDrvngDrctn "Detected Light Source Driving Direction";
BA_ "VNSigAllNodes" SG_ 884 DtctdLghtSrcDrvngDrctn 1;
BA_ "SignalType" SG_ 884 TwnDtctnSts "ENM";
BA_ "SignalLongName" SG_ 884 TwnDtctnSts "Town Detection Status";
BA_ "VNSigAllNodes" SG_ 884 TwnDtctnSts 1;
BA_ "SignalType" SG_ 884 DtctdLghtSrcDstncV "ENM";
BA_ "SignalLongName" SG_ 884 DtctdLghtSrcDstncV "Detected Light Source Distance Validity";
BA_ "VNSigAllNodes" SG_ 884 DtctdLghtSrcDstncV 1;
BA_ "SignalType" SG_ 884 IntLghtRngAct "BLN";
BA_ "SignalLongName" SG_ 884 IntLghtRngAct "Intelligent Light Ranging Active";
BA_ "VNSigAllNodes" SG_ 884 IntLghtRngAct 1;
BA_ "SignalType" SG_ 882 AdvFrntLghtSysHiBmIO "BLN";
BA_ "SignalLongName" SG_ 882 AdvFrntLghtSysHiBmIO "Advanced Front Lighting System High Beam Indication On";
BA_ "VNSigAllNodes" SG_ 882 AdvFrntLghtSysHiBmIO 1;
BA_ "SignalType" SG_ 882 RghtHndLftHndTrffc "ENM";
BA_ "SignalLongName" SG_ 882 RghtHndLftHndTrffc "Righthand Lefthand Traffic";
BA_ "VNSigAllNodes" SG_ 882 RghtHndLftHndTrffc 1;
BA_ "SignalType" SG_ 882 RghtHdlmpXnPwr "UNM";
BA_ "SignalLongName" SG_ 882 RghtHdlmpXnPwr "Right Headlamp Xenon Power";
BA_ "VNSigAllNodes" SG_ 882 RghtHdlmpXnPwr 1;
BA_ "SignalType" SG_ 882 RghtHdlmpSwvlAngl "SNM";
BA_ "SignalLongName" SG_ 882 RghtHdlmpSwvlAngl "Right Headlamp Swivel Angle";
BA_ "VNSigAllNodes" SG_ 882 RghtHdlmpSwvlAngl 1;
BA_ "SignalType" SG_ 882 RghtHdlmpStcBnd "UNM";
BA_ "SignalLongName" SG_ 882 RghtHdlmpStcBnd "Right Headlamp Static Bend";
BA_ "VNSigAllNodes" SG_ 882 RghtHdlmpStcBnd 1;
BA_ "SignalType" SG_ 882 RghtHdlmpLvllngPstn "SNM";
BA_ "SignalLongName" SG_ 882 RghtHdlmpLvllngPstn "Right Headlamp Levelling Position";
BA_ "VNSigAllNodes" SG_ 882 RghtHdlmpLvllngPstn 1;
BA_ "SignalType" SG_ 882 RghtHdlmpDrmPstn "UNM";
BA_ "SignalLongName" SG_ 882 RghtHdlmpDrmPstn "Right Headlamp Drum Position";
BA_ "VNSigAllNodes" SG_ 882 RghtHdlmpDrmPstn 1;
BA_ "SignalType" SG_ 882 LftHdlmpXnPwr "UNM";
BA_ "SignalLongName" SG_ 882 LftHdlmpXnPwr "Left Headlamp Xenon Power";
BA_ "VNSigAllNodes" SG_ 882 LftHdlmpXnPwr 1;
BA_ "SignalType" SG_ 882 LftHdlmpSwvlAngl "SNM";
BA_ "SignalLongName" SG_ 882 LftHdlmpSwvlAngl "Left Headlamp Swivel Angle";
BA_ "VNSigAllNodes" SG_ 882 LftHdlmpSwvlAngl 1;
BA_ "SignalType" SG_ 882 LftHdlmpStcBnd "UNM";
BA_ "SignalLongName" SG_ 882 LftHdlmpStcBnd "Left Headlamp Static Bend";
BA_ "VNSigAllNodes" SG_ 882 LftHdlmpStcBnd 1;
BA_ "SignalType" SG_ 882 LftHdlmpLvllngPstn "SNM";
BA_ "SignalLongName" SG_ 882 LftHdlmpLvllngPstn "Left Headlamp Levelling Position";
BA_ "VNSigAllNodes" SG_ 882 LftHdlmpLvllngPstn 1;
BA_ "SignalType" SG_ 882 LftHdlmpDrmPstn "UNM";
BA_ "SignalLongName" SG_ 882 LftHdlmpDrmPstn "Left Headlamp Drum Position";
BA_ "VNSigAllNodes" SG_ 882 LftHdlmpDrmPstn 1;
BA_ "SignalType" SG_ 882 HdlmpLvllngRrSnsrPstn "SNM";
BA_ "SignalLongName" SG_ 882 HdlmpLvllngRrSnsrPstn "Headlamp Levelling Rear Sensor Position";
BA_ "VNSigAllNodes" SG_ 882 HdlmpLvllngRrSnsrPstn 1;
BA_ "SignalType" SG_ 882 HdlmpLvllngFrntSnsrPstn "SNM";
BA_ "SignalLongName" SG_ 882 HdlmpLvllngFrntSnsrPstn "Headlamp Levelling Front Sensor Position";
BA_ "VNSigAllNodes" SG_ 882 HdlmpLvllngFrntSnsrPstn 1;
BA_ "SignalType" SG_ 393 TrnsTrqCap "UNM";
BA_ "SignalLongName" SG_ 393 TrnsTrqCap "Transmission Torque Capacity";
BA_ "VNSigAllNodes" SG_ 393 TrnsTrqCap 1;
BA_ "SignalType" SG_ 393 TrnsPdCrkshftTqRqPVa "UNM";
BA_ "SignalLongName" SG_ 393 TrnsPdCrkshftTqRqPVa "Transmission Predicted Crankshaft Torque Request Protection Value";
BA_ "VNSigAllNodes" SG_ 393 TrnsPdCrkshftTqRqPVa 1;
BA_ "SignalType" SG_ 393 TPCTR_TorqReqVal "UNM";
BA_ "PacketOrder" SG_ 393 TPCTR_TorqReqVal 2;
BA_ "SignalLongName" SG_ 393 TPCTR_TorqReqVal "Transmission Predicted Crankshaft Torque Request : Torque Request Value";
BA_ "VNSigAllNodes" SG_ 393 TPCTR_TorqReqVal 1;
BA_ "SignalType" SG_ 393 TPCTR_TrqIntrvnTyp "ENM";
BA_ "PacketOrder" SG_ 393 TPCTR_TrqIntrvnTyp 1;
BA_ "SignalLongName" SG_ 393 TPCTR_TrqIntrvnTyp "Transmission Predicted Crankshaft Torque Request : Torque Intervention Type";
BA_ "VNSigAllNodes" SG_ 393 TPCTR_TrqIntrvnTyp 1;
BA_ "SignalType" SG_ 393 TICTR_TorqRqVal "UNM";
BA_ "PacketOrder" SG_ 393 TICTR_TorqRqVal 2;
BA_ "SignalLongName" SG_ 393 TICTR_TorqRqVal "Transmission Immediate Crankshaft Torque Request : Torque Request Value";
BA_ "VNSigAllNodes" SG_ 393 TICTR_TorqRqVal 1;
BA_ "SignalType" SG_ 393 TICTR_TorqRespTyp "ENM";
BA_ "PacketOrder" SG_ 393 TICTR_TorqRespTyp 1;
BA_ "SignalLongName" SG_ 393 TICTR_TorqRespTyp "Transmission Immediate Crankshaft Torque Request : Torque Response Type";
BA_ "VNSigAllNodes" SG_ 393 TICTR_TorqRespTyp 1;
BA_ "SignalType" SG_ 393 TrnsTrqRqALC "UNM";
BA_ "SignalLongName" SG_ 393 TrnsTrqRqALC "Transmission Torque Request Alive Rolling Count";
BA_ "VNSigAllNodes" SG_ 393 TrnsTrqRqALC 1;
BA_ "SignalType" SG_ 199 TORSTimestamp "UNM";
BA_ "PacketOrder" SG_ 199 TORSTimestamp 6;
BA_ "SignalLongName" SG_ 199 TORSTimestamp "Transmission Output Rotational Status : Transmission Output Rotational Status Timestamp";
BA_ "VNSigAllNodes" SG_ 199 TORSTimestamp 1;
BA_ "SignalType" SG_ 199 TORSPulsCntr "UNM";
BA_ "PacketOrder" SG_ 199 TORSPulsCntr 5;
BA_ "SignalLongName" SG_ 199 TORSPulsCntr "Transmission Output Rotational Status : Transmission Output Rotational Status Pulse Counter";
BA_ "VNSigAllNodes" SG_ 199 TORSPulsCntr 1;
BA_ "SignalType" SG_ 199 TORSValidity "ENM";
BA_ "PacketOrder" SG_ 199 TORSValidity 4;
BA_ "SignalLongName" SG_ 199 TORSValidity "Transmission Output Rotational Status : Transmission Output Rotational Status Validity";
BA_ "VNSigAllNodes" SG_ 199 TORSValidity 1;
BA_ "SignalType" SG_ 199 TORSRstOcrd "BLN";
BA_ "PacketOrder" SG_ 199 TORSRstOcrd 3;
BA_ "SignalLongName" SG_ 199 TORSRstOcrd "Transmission Output Rotational Status : Transmission Output Rotational Status Reset Occurred";
BA_ "VNSigAllNodes" SG_ 199 TORSRstOcrd 1;
BA_ "SignalType" SG_ 199 TORSLstTransType "ENM";
BA_ "PacketOrder" SG_ 199 TORSLstTransType 2;
BA_ "SignalLongName" SG_ 199 TORSLstTransType "Transmission Output Rotational Status : Transmission Output Rotational Status Last Transition Type";
BA_ "VNSigAllNodes" SG_ 199 TORSLstTransType 1;
BA_ "SignalType" SG_ 199 TORSRotDir "ENM";
BA_ "PacketOrder" SG_ 199 TORSRotDir 1;
BA_ "SignalLongName" SG_ 199 TORSRotDir "Transmission Output Rotational Status : Transmission Output Rotational Status Rotation Direction";
BA_ "VNSigAllNodes" SG_ 199 TORSRotDir 1;
BA_ "SignalType" SG_ 398 EngNTrnsRegStdyStTqV "ENM";
BA_ "SignalLongName" SG_ 398 EngNTrnsRegStdyStTqV "Engine Non-Transmission Regulated Steady State Torque Validity";
BA_ "VNSigAllNodes" SG_ 398 EngNTrnsRegStdyStTqV 1;
BA_ "SignalType" SG_ 398 EngNTrnsRegStdyStTq "UNM";
BA_ "SignalLongName" SG_ 398 EngNTrnsRegStdyStTq "Engine Non-Transmission Regulated Steady State Torque";
BA_ "VNSigAllNodes" SG_ 398 EngNTrnsRegStdyStTq 1;
BA_ "SignalType" SG_ 398 EngActStdyStTorq "UNM";
BA_ "SignalLongName" SG_ 398 EngActStdyStTorq "Engine Actual Steady State Torque";
BA_ "VNSigAllNodes" SG_ 398 EngActStdyStTorq 1;
BA_ "SignalType" SG_ 398 AccKdwnAtv "BLN";
BA_ "SignalLongName" SG_ 398 AccKdwnAtv "Accelerator Kick Down Detected";
BA_ "VNSigAllNodes" SG_ 398 AccKdwnAtv 1;
BA_ "SignalType" SG_ 398 EngActStdyStTorqV "ENM";
BA_ "SignalLongName" SG_ 398 EngActStdyStTorqV "Engine Actual Steady State Torque Validity";
BA_ "VNSigAllNodes" SG_ 398 EngActStdyStTorqV 1;
BA_ "SignalType" SG_ 398 TrnsEngSpdReqFld "BLN";
BA_ "SignalLongName" SG_ 398 TrnsEngSpdReqFld "Transmission Engine Speed Request Failed";
BA_ "VNSigAllNodes" SG_ 398 TrnsEngSpdReqFld 1;
BA_ "SignalType" SG_ 398 PTACCAct "BLN";
BA_ "SignalLongName" SG_ 398 PTACCAct "Powertrain Adaptive Cruise Control Active";
BA_ "VNSigAllNodes" SG_ 398 PTACCAct 1;
BA_ "SignalType" SG_ 398 CTSS_StbltyLvl "ENM";
BA_ "PacketOrder" SG_ 398 CTSS_StbltyLvl 2;
BA_ "SignalLongName" SG_ 398 CTSS_StbltyLvl "Crankshaft Torque Stability Status : Stability Level";
BA_ "VNSigAllNodes" SG_ 398 CTSS_StbltyLvl 1;
BA_ "SignalType" SG_ 398 CTSS_StbltyTyp "ENM";
BA_ "PacketOrder" SG_ 398 CTSS_StbltyTyp 1;
BA_ "SignalLongName" SG_ 398 CTSS_StbltyTyp "Crankshaft Torque Stability Status : Stability Type";
BA_ "VNSigAllNodes" SG_ 398 CTSS_StbltyTyp 1;
BA_ "SignalType" SG_ 398 CrksftNTrnsRegCmdTq "UNM";
BA_ "SignalLongName" SG_ 398 CrksftNTrnsRegCmdTq "Crankshaft Non-Transmission Regulated Commanded Torque";
BA_ "VNSigAllNodes" SG_ 398 CrksftNTrnsRegCmdTq 1;
BA_ "SignalType" SG_ 398 EngImmTrqTnsRqStat "ENM";
BA_ "SignalLongName" SG_ 398 EngImmTrqTnsRqStat "Engine Immediate Torque Transmission Request Status";
BA_ "VNSigAllNodes" SG_ 398 EngImmTrqTnsRqStat 1;
BA_ "SignalType" SG_ 398 EngImmTrqTnsRqLmSt "ENM";
BA_ "SignalLongName" SG_ 398 EngImmTrqTnsRqLmSt "Engine Immediate Torque Transmission Request Limiting Status";
BA_ "VNSigAllNodes" SG_ 398 EngImmTrqTnsRqLmSt 1;
BA_ "SignalType" SG_ 398 EngPrdctTrqTnsRqStat "ENM";
BA_ "SignalLongName" SG_ 398 EngPrdctTrqTnsRqStat "Engine Predicted Torque Transmission Request Status";
BA_ "VNSigAllNodes" SG_ 398 EngPrdctTrqTnsRqStat 1;
BA_ "SignalType" SG_ 398 EngPrdctTrqTnsRqLmS "ENM";
BA_ "SignalLongName" SG_ 398 EngPrdctTrqTnsRqLmS "Engine Predicted Torque Transmission Request Limiting Status";
BA_ "VNSigAllNodes" SG_ 398 EngPrdctTrqTnsRqLmS 1;
BA_ "SignalType" SG_ 464 FrtAxlOpeMod "ENM";
BA_ "SignalLongName" SG_ 464 FrtAxlOpeMod "Front Axle Operational Mode";
BA_ "VNSigAllNodes" SG_ 464 FrtAxlOpeMod 1;
BA_ "SignalType" SG_ 390 RdHVInvRatVltV "ENM";
BA_ "SignalLongName" SG_ 390 RdHVInvRatVltV "Redundant High Voltage Inverter Rationalized Voltage Validity";
BA_ "VNSigAllNodes" SG_ 390 RdHVInvRatVltV 1;
BA_ "SignalType" SG_ 390 RdHVInvRatVlt "UNM";
BA_ "SignalLongName" SG_ 390 RdHVInvRatVlt "Redundant High Voltage Inverter Rationalized Voltage";
BA_ "VNSigAllNodes" SG_ 390 RdHVInvRatVlt 1;
BA_ "SignalType" SG_ 390 EngActDmpgDsblReq "BLN";
BA_ "SignalLongName" SG_ 390 EngActDmpgDsblReq "Engine Active Damping Disable Requested";
BA_ "VNSigAllNodes" SG_ 390 EngActDmpgDsblReq 1;
BA_ "SignalType" SG_ 390 HybExtndDcFuelCORq "BLN";
BA_ "SignalLongName" SG_ 390 HybExtndDcFuelCORq "Hybrid Extended Deceleration Fuel Cut Off Requested";
BA_ "VNSigAllNodes" SG_ 390 HybExtndDcFuelCORq 1;
BA_ "SignalType" SG_ 390 EstMtrPwrLossV "ENM";
BA_ "SignalLongName" SG_ 390 EstMtrPwrLossV "Estimated Motor Power Loss Validity";
BA_ "VNSigAllNodes" SG_ 390 EstMtrPwrLossV 1;
BA_ "SignalType" SG_ 390 EstMtrPwrLoss "UNM";
BA_ "SignalLongName" SG_ 390 EstMtrPwrLoss "Estimated Motor Power Loss";
BA_ "VNSigAllNodes" SG_ 390 EstMtrPwrLoss 1;
BA_ "SignalType" SG_ 390 HybCmmFailRdPwrCmd "BLN";
BA_ "SignalLongName" SG_ 390 HybCmmFailRdPwrCmd "Hybrid Communication Failure Reduced Power Commanded";
BA_ "VNSigAllNodes" SG_ 390 HybCmmFailRdPwrCmd 1;
BA_ "SignalType" SG_ 390 HybCmmdEngTrqLmtd "UNM";
BA_ "SignalLongName" SG_ 390 HybCmmdEngTrqLmtd "Hybrid Commanded Engine Torque Limited";
BA_ "VNSigAllNodes" SG_ 390 HybCmmdEngTrqLmtd 1;
BA_ "SignalType" SG_ 390 HybACCompRq "ENM";
BA_ "SignalLongName" SG_ 390 HybACCompRq "Hybrid Air Conditioning Compressor Request";
BA_ "VNSigAllNodes" SG_ 390 HybACCompRq 1;
BA_ "SignalType" SG_ 390 HESSI_EngStrtTyp "ENM";
BA_ "PacketOrder" SG_ 390 HESSI_EngStrtTyp 2;
BA_ "SignalLongName" SG_ 390 HESSI_EngStrtTyp "Hybrid Engine Start Stop Information : Engine Start Type";
BA_ "VNSigAllNodes" SG_ 390 HESSI_EngStrtTyp 1;
BA_ "SignalType" SG_ 390 HESSI_EngStrtStpMd "ENM";
BA_ "PacketOrder" SG_ 390 HESSI_EngStrtStpMd 1;
BA_ "SignalLongName" SG_ 390 HESSI_EngStrtStpMd "Hybrid Engine Start Stop Information : Engine Start Stop Mode";
BA_ "VNSigAllNodes" SG_ 390 HESSI_EngStrtStpMd 1;
BA_ "SignalType" SG_ 390 HybCrnkAbrtd "BLN";
BA_ "SignalLongName" SG_ 390 HybCrnkAbrtd "Hybrid Crank Aborted";
BA_ "VNSigAllNodes" SG_ 390 HybCrnkAbrtd 1;
BA_ "SignalType" SG_ 390 CnvntlEngStrtEnbld "BLN";
BA_ "SignalLongName" SG_ 390 CnvntlEngStrtEnbld "Conventional Engine Start Enabled";
BA_ "VNSigAllNodes" SG_ 390 CnvntlEngStrtEnbld 1;
BA_ "SignalType" SG_ 390 HybEngCylDeactReq "BLN";
BA_ "SignalLongName" SG_ 390 HybEngCylDeactReq "Hybrid Engine Cylinder Deactivation Requested";
BA_ "VNSigAllNodes" SG_ 390 HybEngCylDeactReq 1;
BA_ "SignalType" SG_ 390 HybDFCOReq "ENM";
BA_ "SignalLongName" SG_ 390 HybDFCOReq "Hybrid Deceleration Fuel Cut Off Request";
BA_ "VNSigAllNodes" SG_ 390 HybDFCOReq 1;
BA_ "SignalType" SG_ 390 RdPTHVCntrReq "ENM";
BA_ "SignalLongName" SG_ 390 RdPTHVCntrReq "Redundant Powertrain High Voltage Contactor Request";
BA_ "VNSigAllNodes" SG_ 390 RdPTHVCntrReq 1;
BA_ "SignalType" SG_ 817 RrDrvlnSysVehTpSpdLmVal "UNM";
BA_ "SignalLongName" SG_ 817 RrDrvlnSysVehTpSpdLmVal "Rear Driveline System Vehicle Top Speed Limit Value";
BA_ "VNSigAllNodes" SG_ 817 RrDrvlnSysVehTpSpdLmVal 1;
BA_ "SignalType" SG_ 817 RrAxlTmpInhIO "BLN";
BA_ "SignalLongName" SG_ 817 RrAxlTmpInhIO "Rear Axle Temporary Inhibit Indication On";
BA_ "VNSigAllNodes" SG_ 817 RrAxlTmpInhIO 1;
BA_ "SignalType" SG_ 817 RrAxlMalfIO "BLN";
BA_ "SignalLongName" SG_ 817 RrAxlMalfIO "Rear Axle Malfunction Indication On";
BA_ "VNSigAllNodes" SG_ 817 RrAxlMalfIO 1;
BA_ "SignalType" SG_ 465 RrAxlOpeMod "ENM";
BA_ "SignalLongName" SG_ 465 RrAxlOpeMod "Rear Axle Operational Mode";
BA_ "VNSigAllNodes" SG_ 465 RrAxlOpeMod 1;
BA_ "SignalType" SG_ 465 RrAxlEstTrqV "ENM";
BA_ "SignalLongName" SG_ 465 RrAxlEstTrqV "Rear Axle Estimated Torque Validity";
BA_ "VNSigAllNodes" SG_ 465 RrAxlEstTrqV 1;
BA_ "SignalType" SG_ 465 RrAxlEstTrq "SNM";
BA_ "SignalLongName" SG_ 465 RrAxlEstTrq "Rear Axle Estimated Torque";
BA_ "VNSigAllNodes" SG_ 465 RrAxlEstTrq 1;
BA_ "SignalType" SG_ 465 RrAxlStat "ENM";
BA_ "SignalLongName" SG_ 465 RrAxlStat "Rear Axle Status";
BA_ "VNSigAllNodes" SG_ 465 RrAxlStat 1;
BA_ "SignalType" SG_ 465 RrAxlCtrlMod "ENM";
BA_ "SignalLongName" SG_ 465 RrAxlCtrlMod "Rear Axle Control Mode";
BA_ "VNSigAllNodes" SG_ 465 RrAxlCtrlMod 1;
BA_ "SignalType" SG_ 465 RAMDVLReqVal "UNM";
BA_ "SignalLongName" SG_ 465 RAMDVLReqVal "Rear Axle Maximum Differential Velocity Limit : Request Value";
BA_ "VNSigAllNodes" SG_ 465 RAMDVLReqVal 1;
BA_ "SignalType" SG_ 465 RAMDVLAtv "BLN";
BA_ "SignalLongName" SG_ 465 RAMDVLAtv "Rear Axle Maximum Differential Velocity Limit : Active";
BA_ "VNSigAllNodes" SG_ 465 RAMDVLAtv 1;
BA_ "SignalType" SG_ 460 SecAxlStat "ENM";
BA_ "SignalLongName" SG_ 460 SecAxlStat "Secondary Axle Status";
BA_ "VNSigAllNodes" SG_ 460 SecAxlStat 1;
BA_ "SignalType" SG_ 460 SecAxlEstTrqV "ENM";
BA_ "SignalLongName" SG_ 460 SecAxlEstTrqV "Secondary Axle Estimated Torque Validity";
BA_ "VNSigAllNodes" SG_ 460 SecAxlEstTrqV 1;
BA_ "SignalType" SG_ 460 SecAxlEstTrq "UNM";
BA_ "SignalLongName" SG_ 460 SecAxlEstTrq "Secondary Axle Estimated Torque";
BA_ "VNSigAllNodes" SG_ 460 SecAxlEstTrq 1;
BA_ "SignalType" SG_ 460 SAMDVLReqVal "UNM";
BA_ "SignalLongName" SG_ 460 SAMDVLReqVal "Secondary Axle Maximum Differential Velocity Limit : Request Value";
BA_ "VNSigAllNodes" SG_ 460 SAMDVLReqVal 1;
BA_ "SignalType" SG_ 460 SAMDVLAtv "BLN";
BA_ "SignalLongName" SG_ 460 SAMDVLAtv "Secondary Axle Maximum Differential Velocity Limit : Active";
BA_ "VNSigAllNodes" SG_ 460 SAMDVLAtv 1;
BA_ "SignalType" SG_ 460 PTTrnsfrCseMd "ENM";
BA_ "SignalLongName" SG_ 460 PTTrnsfrCseMd "Powertrain Transfer Case Mode";
BA_ "VNSigAllNodes" SG_ 460 PTTrnsfrCseMd 1;
BA_ "SignalType" SG_ 460 SecAxlCtrlMod "ENM";
BA_ "SignalLongName" SG_ 460 SecAxlCtrlMod "Secondary Axle Control Mode";
BA_ "VNSigAllNodes" SG_ 460 SecAxlCtrlMod 1;
BA_ "SignalType" SG_ 462 SecAxlTrqReqProtVal "UNM";
BA_ "SignalLongName" SG_ 462 SecAxlTrqReqProtVal "Secondary Axle Torque Request Protection Value";
BA_ "VNSigAllNodes" SG_ 462 SecAxlTrqReqProtVal 1;
BA_ "SignalType" SG_ 462 SecAxlTrqReqARollCnt "UNM";
BA_ "SignalLongName" SG_ 462 SecAxlTrqReqARollCnt "Secondary Axle Torque Request Alive Rolling Count";
BA_ "VNSigAllNodes" SG_ 462 SecAxlTrqReqARollCnt 1;
BA_ "SignalType" SG_ 462 SATRCplReqVal "UNM";
BA_ "PacketOrder" SG_ 462 SATRCplReqVal 1;
BA_ "SignalLongName" SG_ 462 SATRCplReqVal "Secondary Axle Torque Request : Coupling Request Value";
BA_ "VNSigAllNodes" SG_ 462 SATRCplReqVal 1;
BA_ "SignalType" SG_ 462 SATRCplReqAtv "BLN";
BA_ "SignalLongName" SG_ 462 SATRCplReqAtv "Secondary Axle Torque Request : Coupling Request Active";
BA_ "VNSigAllNodes" SG_ 462 SATRCplReqAtv 1;
BA_ "SignalType" SG_ 463 FourWhlDrvIndReq "ENM";
BA_ "SignalLongName" SG_ 463 FourWhlDrvIndReq "Four Wheel Drive Indication Request";
BA_ "VNSigAllNodes" SG_ 463 FourWhlDrvIndReq 1;
BA_ "SignalType" SG_ 463 TrnsfrCsRngShfSpdLmt "UNM";
BA_ "SignalLongName" SG_ 463 TrnsfrCsRngShfSpdLmt "Transfer Case Range Shift Speed Limit";
BA_ "VNSigAllNodes" SG_ 463 TrnsfrCsRngShfSpdLmt 1;
BA_ "SignalType" SG_ 463 SecAxlNonEmMalfIO "BLN";
BA_ "SignalLongName" SG_ 463 SecAxlNonEmMalfIO "Secondary Axle Non-emissions Malf Ind On";
BA_ "VNSigAllNodes" SG_ 463 SecAxlNonEmMalfIO 1;
BA_ "SignalType" SG_ 463 SecAxlOperMod "ENM";
BA_ "SignalLongName" SG_ 463 SecAxlOperMod "Secondary Axle Operational Mode";
BA_ "VNSigAllNodes" SG_ 463 SecAxlOperMod 1;
BA_ "SignalType" SG_ 463 SecAxlTmpInhIO "BLN";
BA_ "SignalLongName" SG_ 463 SecAxlTmpInhIO "Secondary Axle Temporary Inhibit Indication On";
BA_ "VNSigAllNodes" SG_ 463 SecAxlTmpInhIO 1;
BA_ "SignalType" SG_ 719 RrVrtlBmpAxlTrqCmdRC "UNM";
BA_ "SignalLongName" SG_ 719 RrVrtlBmpAxlTrqCmdRC "Rear Virtual Bumper Axle Torque Command Rolling Count";
BA_ "VNSigAllNodes" SG_ 719 RrVrtlBmpAxlTrqCmdRC 1;
BA_ "SignalType" SG_ 719 RrVrtlBmpAxlTrqCmdProtVal "UNM";
BA_ "SignalLongName" SG_ 719 RrVrtlBmpAxlTrqCmdProtVal "Rear Virtual Bumper Axle Torque Command Protection Value";
BA_ "VNSigAllNodes" SG_ 719 RrVrtlBmpAxlTrqCmdProtVal 1;
BA_ "SignalType" SG_ 719 RVBATC_AxlTrqRqstAct "BLN";
BA_ "PacketOrder" SG_ 719 RVBATC_AxlTrqRqstAct 1;
BA_ "SignalLongName" SG_ 719 RVBATC_AxlTrqRqstAct "Rear Virtual Bumper Axle Torque Command : Axle Torque Request Active";
BA_ "VNSigAllNodes" SG_ 719 RVBATC_AxlTrqRqstAct 1;
BA_ "SignalType" SG_ 719 RVBATC_AxlTrqRqst "UNM";
BA_ "PacketOrder" SG_ 719 RVBATC_AxlTrqRqst 2;
BA_ "SignalLongName" SG_ 719 RVBATC_AxlTrqRqst "Rear Virtual Bumper Axle Torque Command : Axle Torque Request";
BA_ "GenSigStartValue" SG_ 719 RVBATC_AxlTrqRqst 32767;
BA_ "VNSigAllNodes" SG_ 719 RVBATC_AxlTrqRqst 1;
BA_ "SignalType" SG_ 853 SrvPedtrnProtSysIO "BLN";
BA_ "SignalLongName" SG_ 853 SrvPedtrnProtSysIO "Service Pedestrian Protection System Indication On";
BA_ "VNSigAllNodes" SG_ 853 SrvPedtrnProtSysIO 1;
BA_ "SignalType" SG_ 853 PedtrnProtSysDisbld "BLN";
BA_ "SignalLongName" SG_ 853 PedtrnProtSysDisbld "Pedestrian Protection System Disabled";
BA_ "VNSigAllNodes" SG_ 853 PedtrnProtSysDisbld 1;
BA_ "SignalType" SG_ 853 PedtrnProtSysDpl "BLN";
BA_ "SignalLongName" SG_ 853 PedtrnProtSysDpl "Pedestrian Protection System Deployed";
BA_ "VNSigAllNodes" SG_ 853 PedtrnProtSysDpl 1;
BA_ "SignalType" SG_ 869 FCACustStngAvlbl "BLN";
BA_ "SignalLongName" SG_ 869 FCACustStngAvlbl "Forward Collision Alert Customization Setting Available";
BA_ "VNSigAllNodes" SG_ 869 FCACustStngAvlbl 1;
BA_ "SignalType" SG_ 869 FwdClnAlrtCustCrntSetngVal "ENM";
BA_ "SignalLongName" SG_ 869 FwdClnAlrtCustCrntSetngVal "Forward Collision Alert Customization Current Setting Value";
BA_ "VNSigAllNodes" SG_ 869 FwdClnAlrtCustCrntSetngVal 1;
BA_ "SignalType" SG_ 869 GNCustSetngAvlbl "BLN";
BA_ "SignalLongName" SG_ 869 GNCustSetngAvlbl "Go Notifier Customization Setting Available";
BA_ "VNSigAllNodes" SG_ 869 GNCustSetngAvlbl 1;
BA_ "SignalType" SG_ 869 CPSUnblIO "BLN";
BA_ "SignalLongName" SG_ 869 CPSUnblIO "Collision Preparation System Unavailable Indication On";
BA_ "VNSigAllNodes" SG_ 869 CPSUnblIO 1;
BA_ "SignalType" SG_ 869 ColPrSysStngAvl "BLN";
BA_ "SignalLongName" SG_ 869 ColPrSysStngAvl "Collision Preparation System Setting Available";
BA_ "VNSigAllNodes" SG_ 869 ColPrSysStngAvl 1;
BA_ "SignalType" SG_ 869 CPSOffIO "BLN";
BA_ "SignalLongName" SG_ 869 CPSOffIO "Collision Preparation System Off Indication On";
BA_ "VNSigAllNodes" SG_ 869 CPSOffIO 1;
BA_ "SignalType" SG_ 869 CPSFldIO "BLN";
BA_ "SignalLongName" SG_ 869 CPSFldIO "Collision Preparation System Failed Indication On";
BA_ "VNSigAllNodes" SG_ 869 CPSFldIO 1;
BA_ "SignalType" SG_ 869 ColPrSysCrntStng "ENM";
BA_ "SignalLongName" SG_ 869 ColPrSysCrntStng "Collision Preparation System Current Setting Value";
BA_ "VNSigAllNodes" SG_ 869 ColPrSysCrntStng 1;
BA_ "SignalType" SG_ 869 CPSAlrtOnlIO "BLN";
BA_ "SignalLongName" SG_ 869 CPSAlrtOnlIO "Collision Preparation System Alert Only Indication On";
BA_ "VNSigAllNodes" SG_ 869 CPSAlrtOnlIO 1;
BA_ "SignalType" SG_ 869 GNCustCrntStngVal "ENM";
BA_ "SignalLongName" SG_ 869 GNCustCrntStngVal "Go Notifier Customization Current Setting Value";
BA_ "VNSigAllNodes" SG_ 869 GNCustCrntStngVal 1;
BA_ "SignalType" SG_ 717 ColPrSysAxlTrqCmdProtVal "UNM";
BA_ "SignalLongName" SG_ 717 ColPrSysAxlTrqCmdProtVal "Collision Preparation System Axle Torque Command Protection Value";
BA_ "VNSigAllNodes" SG_ 717 ColPrSysAxlTrqCmdProtVal 1;
BA_ "SignalType" SG_ 717 CPSATC_AxlTrqRqstAct "BLN";
BA_ "PacketOrder" SG_ 717 CPSATC_AxlTrqRqstAct 1;
BA_ "SignalLongName" SG_ 717 CPSATC_AxlTrqRqstAct "Collision Preparation System Axle Torque Command : Axle Torque Request Active";
BA_ "VNSigAllNodes" SG_ 717 CPSATC_AxlTrqRqstAct 1;
BA_ "SignalType" SG_ 717 CPSATC_AxlTrqRqst "UNM";
BA_ "PacketOrder" SG_ 717 CPSATC_AxlTrqRqst 2;
BA_ "SignalLongName" SG_ 717 CPSATC_AxlTrqRqst "Collision Preparation System Axle Torque Command : Axle Torque Request";
BA_ "GenSigStartValue" SG_ 717 CPSATC_AxlTrqRqst 32767;
BA_ "VNSigAllNodes" SG_ 717 CPSATC_AxlTrqRqst 1;
BA_ "SignalType" SG_ 717 ColPrSysAxlTrqCmdRC "UNM";
BA_ "SignalLongName" SG_ 717 ColPrSysAxlTrqCmdRC "Collision Preparation System Axle Torque Command Rolling Count";
BA_ "VNSigAllNodes" SG_ 717 ColPrSysAxlTrqCmdRC 1;
BA_ "SignalType" SG_ 568 a_12VSysVlt "UNM";
BA_ "SignalLongName" SG_ 568 a_12VSysVlt "12V System Voltage";
BA_ "VNSigAllNodes" SG_ 568 a_12VSysVlt 1;
BA_ "SignalType" SG_ 564 TrlrStabAstActIO "BLN";
BA_ "SignalLongName" SG_ 564 TrlrStabAstActIO "Trailer Stability Assist Active Indication On";
BA_ "VNSigAllNodes" SG_ 564 TrlrStabAstActIO 1;
BA_ "SignalType" SG_ 564 PerfTracSysStat "ENM";
BA_ "SignalLongName" SG_ 564 PerfTracSysStat "Performance Traction System Status";
BA_ "VNSigAllNodes" SG_ 564 PerfTracSysStat 1;
BA_ "SignalType" SG_ 564 PerfTrcCrnExStngVal "ENM";
BA_ "SignalLongName" SG_ 564 PerfTrcCrnExStngVal "Performance Traction Corner Exit Setting Value";
BA_ "VNSigAllNodes" SG_ 564 PerfTrcCrnExStngVal 1;
BA_ "SignalType" SG_ 313 PrkAstAdvSysAct "BLN";
BA_ "SignalLongName" SG_ 313 PrkAstAdvSysAct "Parking Assistance Advanced  System Active";
BA_ "VNSigAllNodes" SG_ 313 PrkAstAdvSysAct 1;
BA_ "SignalType" SG_ 313 SndPerfMdCsStRq "ENM";
BA_ "SignalLongName" SG_ 313 SndPerfMdCsStRq "Sound Performance Mode Customization Setting Request";
BA_ "VNSigAllNodes" SG_ 313 SndPerfMdCsStRq 1;
BA_ "SignalType" SG_ 313 HptcStVbnStat "ENM";
BA_ "SignalLongName" SG_ 313 HptcStVbnStat "Haptic Seat Vibration Status";
BA_ "VNSigAllNodes" SG_ 313 HptcStVbnStat 1;
BA_ "SignalType" SG_ 313 ACCSettingType "ENM";
BA_ "SignalLongName" SG_ 313 ACCSettingType "Adaptive Cruise Control Setting Type";
BA_ "VNSigAllNodes" SG_ 313 ACCSettingType 1;
BA_ "SignalType" SG_ 313 FCABrkPrflReq "BLN";
BA_ "SignalLongName" SG_ 313 FCABrkPrflReq "Forward Collision Alert Brake Prefill Request";
BA_ "VNSigAllNodes" SG_ 313 FCABrkPrflReq 1;
BA_ "PacketOrder" SG_ 313 ISA2CCC_ScndCdChr 1;
BA_ "SignalType" SG_ 313 ISA2CCC_ScndCdChr "ENM";
BA_ "SignalLongName" SG_ 313 ISA2CCC_ScndCdChr "International Standard Alpha 2 Coded Country Code : Second Code Character";
BA_ "VNSigAllNodes" SG_ 313 ISA2CCC_ScndCdChr 1;
BA_ "SignalType" SG_ 313 ISA2CCC_FrstCdChr "ENM";
BA_ "PacketOrder" SG_ 313 ISA2CCC_FrstCdChr 2;
BA_ "SignalLongName" SG_ 313 ISA2CCC_FrstCdChr "International Standard Alpha 2 Coded Country Code : First Code Character";
BA_ "VNSigAllNodes" SG_ 313 ISA2CCC_FrstCdChr 1;
BA_ "SignalType" SG_ 313 DispPerfMdCsStRq "ENM";
BA_ "SignalLongName" SG_ 313 DispPerfMdCsStRq "Display Performance Mode Customization Setting Request";
BA_ "VNSigAllNodes" SG_ 313 DispPerfMdCsStRq 1;
BA_ "SignalType" SG_ 313 CrshAlrtStPrsnt "BLN";
BA_ "SignalLongName" SG_ 313 CrshAlrtStPrsnt "Crash Alert Seat Present";
BA_ "VNSigAllNodes" SG_ 313 CrshAlrtStPrsnt 1;
BA_ "SignalType" SG_ 313 FwdClnAlrtCustStngReq "ENM";
BA_ "SignalLongName" SG_ 313 FwdClnAlrtCustStngReq "Forward Collision Alert Customization Setting Request";
BA_ "VNSigAllNodes" SG_ 313 FwdClnAlrtCustStngReq 1;
BA_ "SignalType" SG_ 313 GNCustStngReq "ENM";
BA_ "SignalLongName" SG_ 313 GNCustStngReq "Go Notifier Customization Setting Request";
BA_ "VNSigAllNodes" SG_ 313 GNCustStngReq 1;
BA_ "SignalType" SG_ 818 FrntAxlTmpInhIO "BLN";
BA_ "SignalLongName" SG_ 818 FrntAxlTmpInhIO "Front Axle Temporary Inhibit Indication On";
BA_ "VNSigAllNodes" SG_ 818 FrntAxlTmpInhIO 1;
BA_ "SignalType" SG_ 818 FrAxlMalfIO "BLN";
BA_ "SignalLongName" SG_ 818 FrAxlMalfIO "Front Axle Malfunction Indication On";
BA_ "VNSigAllNodes" SG_ 818 FrAxlMalfIO 1;
BA_ "SignalType" SG_ 1328 ACSAlarm9 "ENM";
BA_ "PacketOrder" SG_ 1328 ACSAlarm9 10;
BA_ "SignalLongName" SG_ 1328 ACSAlarm9 "Alarm Clock Status : Alarm 9";
BA_ "VNSigAllNodes" SG_ 1328 ACSAlarm9 1;
BA_ "SignalType" SG_ 1328 ACSAlarm8 "ENM";
BA_ "PacketOrder" SG_ 1328 ACSAlarm8 9;
BA_ "SignalLongName" SG_ 1328 ACSAlarm8 "Alarm Clock Status : Alarm 8";
BA_ "VNSigAllNodes" SG_ 1328 ACSAlarm8 1;
BA_ "SignalType" SG_ 1328 ACSAlarm7 "ENM";
BA_ "PacketOrder" SG_ 1328 ACSAlarm7 8;
BA_ "SignalLongName" SG_ 1328 ACSAlarm7 "Alarm Clock Status : Alarm 7";
BA_ "VNSigAllNodes" SG_ 1328 ACSAlarm7 1;
BA_ "SignalType" SG_ 1328 ACSAlarm6 "ENM";
BA_ "PacketOrder" SG_ 1328 ACSAlarm6 7;
BA_ "SignalLongName" SG_ 1328 ACSAlarm6 "Alarm Clock Status : Alarm 6";
BA_ "VNSigAllNodes" SG_ 1328 ACSAlarm6 1;
BA_ "SignalType" SG_ 1328 ACSAlarm5 "ENM";
BA_ "PacketOrder" SG_ 1328 ACSAlarm5 6;
BA_ "SignalLongName" SG_ 1328 ACSAlarm5 "Alarm Clock Status : Alarm 5";
BA_ "VNSigAllNodes" SG_ 1328 ACSAlarm5 1;
BA_ "SignalType" SG_ 1328 ACSAlarm4 "ENM";
BA_ "PacketOrder" SG_ 1328 ACSAlarm4 5;
BA_ "SignalLongName" SG_ 1328 ACSAlarm4 "Alarm Clock Status : Alarm 4";
BA_ "VNSigAllNodes" SG_ 1328 ACSAlarm4 1;
BA_ "SignalType" SG_ 1328 ACSAlarm3 "ENM";
BA_ "PacketOrder" SG_ 1328 ACSAlarm3 4;
BA_ "SignalLongName" SG_ 1328 ACSAlarm3 "Alarm Clock Status : Alarm 3";
BA_ "VNSigAllNodes" SG_ 1328 ACSAlarm3 1;
BA_ "SignalType" SG_ 1328 ACSAlarm2 "ENM";
BA_ "PacketOrder" SG_ 1328 ACSAlarm2 3;
BA_ "SignalLongName" SG_ 1328 ACSAlarm2 "Alarm Clock Status : Alarm 2";
BA_ "VNSigAllNodes" SG_ 1328 ACSAlarm2 1;
BA_ "SignalType" SG_ 1328 ACSAlarm15 "ENM";
BA_ "PacketOrder" SG_ 1328 ACSAlarm15 16;
BA_ "SignalLongName" SG_ 1328 ACSAlarm15 "Alarm Clock Status : Alarm 15";
BA_ "VNSigAllNodes" SG_ 1328 ACSAlarm15 1;
BA_ "SignalType" SG_ 1328 ACSAlarm14 "ENM";
BA_ "PacketOrder" SG_ 1328 ACSAlarm14 15;
BA_ "SignalLongName" SG_ 1328 ACSAlarm14 "Alarm Clock Status : Alarm 14";
BA_ "VNSigAllNodes" SG_ 1328 ACSAlarm14 1;
BA_ "SignalType" SG_ 1328 ACSAlarm13 "ENM";
BA_ "PacketOrder" SG_ 1328 ACSAlarm13 14;
BA_ "SignalLongName" SG_ 1328 ACSAlarm13 "Alarm Clock Status : Alarm 13";
BA_ "VNSigAllNodes" SG_ 1328 ACSAlarm13 1;
BA_ "SignalType" SG_ 1328 ACSAlarm12 "ENM";
BA_ "PacketOrder" SG_ 1328 ACSAlarm12 13;
BA_ "SignalLongName" SG_ 1328 ACSAlarm12 "Alarm Clock Status : Alarm 12";
BA_ "VNSigAllNodes" SG_ 1328 ACSAlarm12 1;
BA_ "SignalType" SG_ 1328 ACSAlarm11 "ENM";
BA_ "PacketOrder" SG_ 1328 ACSAlarm11 12;
BA_ "SignalLongName" SG_ 1328 ACSAlarm11 "Alarm Clock Status : Alarm 11";
BA_ "VNSigAllNodes" SG_ 1328 ACSAlarm11 1;
BA_ "SignalType" SG_ 1328 ACSAlarm10 "ENM";
BA_ "PacketOrder" SG_ 1328 ACSAlarm10 11;
BA_ "SignalLongName" SG_ 1328 ACSAlarm10 "Alarm Clock Status : Alarm 10";
BA_ "VNSigAllNodes" SG_ 1328 ACSAlarm10 1;
BA_ "SignalType" SG_ 1328 ACSAlarm1 "ENM";
BA_ "PacketOrder" SG_ 1328 ACSAlarm1 2;
BA_ "SignalLongName" SG_ 1328 ACSAlarm1 "Alarm Clock Status : Alarm 1";
BA_ "VNSigAllNodes" SG_ 1328 ACSAlarm1 1;
BA_ "SignalType" SG_ 1328 ACSAlarm0 "ENM";
BA_ "PacketOrder" SG_ 1328 ACSAlarm0 1;
BA_ "SignalLongName" SG_ 1328 ACSAlarm0 "Alarm Clock Status : Alarm 0";
BA_ "VNSigAllNodes" SG_ 1328 ACSAlarm0 1;
BA_ "SignalType" SG_ 1296 ACCAutoSetSpdStat "ENM";
BA_ "SignalLongName" SG_ 1296 ACCAutoSetSpdStat "Adaptive Cruise Control Auto Set Speed Status";
BA_ "VNSigAllNodes" SG_ 1296 ACCAutoSetSpdStat 1;
BA_ "SignalType" SG_ 1296 FwdClnAlrtOffIO "BLN";
BA_ "SignalLongName" SG_ 1296 FwdClnAlrtOffIO "Forward Collision Alert Off Indication On";
BA_ "VNSigAllNodes" SG_ 1296 FwdClnAlrtOffIO 1;
BA_ "SignalType" SG_ 1296 VADIR_IndLvl "ENM";
BA_ "PacketOrder" SG_ 1296 VADIR_IndLvl 3;
BA_ "SignalLongName" SG_ 1296 VADIR_IndLvl "Vehicle Ahead Distance Indication Request : Indication Level";
BA_ "VNSigAllNodes" SG_ 1296 VADIR_IndLvl 1;
BA_ "SignalType" SG_ 1296 VADIR_FlwTme "UNM";
BA_ "PacketOrder" SG_ 1296 VADIR_FlwTme 2;
BA_ "SignalLongName" SG_ 1296 VADIR_FlwTme "Vehicle Ahead Distance Indication Request : Following Time";
BA_ "VNSigAllNodes" SG_ 1296 VADIR_FlwTme 1;
BA_ "SignalType" SG_ 1296 VADIR_FlwDst "UNM";
BA_ "PacketOrder" SG_ 1296 VADIR_FlwDst 1;
BA_ "SignalLongName" SG_ 1296 VADIR_FlwDst "Vehicle Ahead Distance Indication Request : Following Distance";
BA_ "VNSigAllNodes" SG_ 1296 VADIR_FlwDst 1;
BA_ "SignalType" SG_ 311 PsngSysDilPrcs "UNM";
BA_ "SignalLongName" SG_ 311 PsngSysDilPrcs "Positioning System Dilution of Precision";
BA_ "VNSigAllNodes" SG_ 311 PsngSysDilPrcs 1;
BA_ "SignalType" SG_ 311 Hrs "UNM";
BA_ "SignalLongName" SG_ 311 Hrs "Hours";
BA_ "VNSigAllNodes" SG_ 311 Hrs 1;
BA_ "SignalType" SG_ 311 PsngSysHding "UNM";
BA_ "SignalLongName" SG_ 311 PsngSysHding "Positioning System Heading";
BA_ "VNSigAllNodes" SG_ 311 PsngSysHding 1;
BA_ "SignalType" SG_ 311 PsngSysElvtn "UNM";
BA_ "SignalLongName" SG_ 311 PsngSysElvtn "Positioning System Elevation";
BA_ "VNSigAllNodes" SG_ 311 PsngSysElvtn 1;
BA_ "SignalType" SG_ 311 PsngSysHdingV "ENM";
BA_ "SignalLongName" SG_ 311 PsngSysHdingV "Positioning System Heading Validity";
BA_ "VNSigAllNodes" SG_ 311 PsngSysHdingV 1;
BA_ "SignalType" SG_ 311 HrsV "ENM";
BA_ "SignalLongName" SG_ 311 HrsV "Hours Validity";
BA_ "VNSigAllNodes" SG_ 311 HrsV 1;
BA_ "SignalType" SG_ 311 MinsV "ENM";
BA_ "SignalLongName" SG_ 311 MinsV "Minutes Validity";
BA_ "VNSigAllNodes" SG_ 311 MinsV 1;
BA_ "SignalType" SG_ 311 Mins "UNM";
BA_ "SignalLongName" SG_ 311 Mins "Minutes";
BA_ "VNSigAllNodes" SG_ 311 Mins 1;
BA_ "SignalType" SG_ 311 PsngSysDilPrcsV "ENM";
BA_ "SignalLongName" SG_ 311 PsngSysDilPrcsV "Positioning System Dilution of Precision Validity";
BA_ "VNSigAllNodes" SG_ 311 PsngSysDilPrcsV 1;
BA_ "SignalType" SG_ 311 PsngSysElvtnV "ENM";
BA_ "SignalLongName" SG_ 311 PsngSysElvtnV "Positioning System Elevation Validity";
BA_ "VNSigAllNodes" SG_ 311 PsngSysElvtnV 1;
BA_ "SignalType" SG_ 311 VehSpeSta "ENM";
BA_ "SignalLongName" SG_ 311 VehSpeSta "Vehicle Speed State";
BA_ "VNSigAllNodes" SG_ 311 VehSpeSta 1;
BA_ "SignalType" SG_ 536 ACCHptcStVbnRqSeqN "UNM";
BA_ "SignalLongName" SG_ 536 ACCHptcStVbnRqSeqN "Adaptive Cruise Control Haptic Seat Vibration Request Sequence Number";
BA_ "VNSigAllNodes" SG_ 536 ACCHptcStVbnRqSeqN 1;
BA_ "SignalType" SG_ 536 ACCHptcStVbnReq "UNM";
BA_ "SignalLongName" SG_ 536 ACCHptcStVbnReq "Adaptive Cruise Control Haptic Seat Vibration Request";
BA_ "VNSigAllNodes" SG_ 536 ACCHptcStVbnReq 1;
BA_ "SignalType" SG_ 536 ShtToPrkBfExtngVehIO "BLN";
BA_ "SignalLongName" SG_ 536 ShtToPrkBfExtngVehIO "Shift to Park Before Exiting Vehicle Indication On";
BA_ "VNSigAllNodes" SG_ 536 ShtToPrkBfExtngVehIO 1;
BA_ "SignalType" SG_ 536 AutoBrkRlsIO "BLN";
BA_ "SignalLongName" SG_ 536 AutoBrkRlsIO "Autonomous Brake Release Indication On";
BA_ "VNSigAllNodes" SG_ 536 AutoBrkRlsIO 1;
BA_ "SignalType" SG_ 536 HdUpDsplyUnblIO "BLN";
BA_ "SignalLongName" SG_ 536 HdUpDsplyUnblIO "Head Up Display Unavailable Indication On";
BA_ "VNSigAllNodes" SG_ 536 HdUpDsplyUnblIO 1;
BA_ "SignalType" SG_ 536 FSRACCFrstRsmPrssIO "BLN";
BA_ "SignalLongName" SG_ 536 FSRACCFrstRsmPrssIO "Full Speed Range Adaptive Cruise Control First Resume Press Indication On";
BA_ "VNSigAllNodes" SG_ 536 FSRACCFrstRsmPrssIO 1;
BA_ "SignalType" SG_ 536 FrtRdrBlckdIO "BLN";
BA_ "SignalLongName" SG_ 536 FrtRdrBlckdIO "Front Radar Blocked Indication On";
BA_ "VNSigAllNodes" SG_ 536 FrtRdrBlckdIO 1;
BA_ "SignalType" SG_ 570 FCAHptcStVbnRqSeqN "UNM";
BA_ "SignalLongName" SG_ 570 FCAHptcStVbnRqSeqN "Forward Collision Alert Haptic Seat Vibration Request Sequence Number";
BA_ "VNSigAllNodes" SG_ 570 FCAHptcStVbnRqSeqN 1;
BA_ "SignalType" SG_ 570 FCAHptcStVbnReq "UNM";
BA_ "SignalLongName" SG_ 570 FCAHptcStVbnReq "Forward Collision Alert Haptic Seat Vibration Request";
BA_ "VNSigAllNodes" SG_ 570 FCAHptcStVbnReq 1;
BA_ "SignalType" SG_ 810 PsngSysLongV "ENM";
BA_ "SignalLongName" SG_ 810 PsngSysLongV "Positioning System Longitude Validity";
BA_ "VNSigAllNodes" SG_ 810 PsngSysLongV 1;
BA_ "SignalType" SG_ 810 PsngSysLong "SNM";
BA_ "SignalLongName" SG_ 810 PsngSysLong "Positioning System Longitude";
BA_ "VNSigAllNodes" SG_ 810 PsngSysLong 1;
BA_ "SignalType" SG_ 810 PsngSysLatV "ENM";
BA_ "SignalLongName" SG_ 810 PsngSysLatV "Positioning System Latitude Validity";
BA_ "VNSigAllNodes" SG_ 810 PsngSysLatV 1;
BA_ "SignalType" SG_ 810 PsngSysLat "SNM";
BA_ "SignalLongName" SG_ 810 PsngSysLat "Positioning System Latitude";
BA_ "VNSigAllNodes" SG_ 810 PsngSysLat 1;
BA_ "SignalType" SG_ 848 TrlrBrkStat "ENM";
BA_ "SignalLongName" SG_ 848 TrlrBrkStat "Trailer Brake Status";
BA_ "VNSigAllNodes" SG_ 848 TrlrBrkStat 1;
BA_ "SignalType" SG_ 848 TrlrBrkngSysBrkLtsReq "BLN";
BA_ "SignalLongName" SG_ 848 TrlrBrkngSysBrkLtsReq "Trailer Braking System Brake Lights Requested";
BA_ "VNSigAllNodes" SG_ 848 TrlrBrkngSysBrkLtsReq 1;
BA_ "SignalType" SG_ 848 SrvTrlrBrkngSysIO "BLN";
BA_ "SignalLongName" SG_ 848 SrvTrlrBrkngSysIO "ServiceTrailer Braking System Indication On";
BA_ "VNSigAllNodes" SG_ 848 SrvTrlrBrkngSysIO 1;
BA_ "SignalType" SG_ 848 TrlrWiringFltIO "BLN";
BA_ "SignalLongName" SG_ 848 TrlrWiringFltIO "Trailer Wiring Fault Indication On";
BA_ "VNSigAllNodes" SG_ 848 TrlrWiringFltIO 1;
BA_ "SignalType" SG_ 848 TrlrCnctdIO "BLN";
BA_ "SignalLongName" SG_ 848 TrlrCnctdIO "Trailer Connected Indication On";
BA_ "VNSigAllNodes" SG_ 848 TrlrCnctdIO 1;
BA_ "SignalType" SG_ 848 TrlrBrkngGainSetIO "BLN";
BA_ "SignalLongName" SG_ 848 TrlrBrkngGainSetIO "Trailer Braking Gain Setting Indication On";
BA_ "VNSigAllNodes" SG_ 848 TrlrBrkngGainSetIO 1;
BA_ "SignalType" SG_ 848 TrlrBrkngGainSet "UNM";
BA_ "SignalLongName" SG_ 848 TrlrBrkngGainSet "Trailer Braking Gain Setting";
BA_ "VNSigAllNodes" SG_ 848 TrlrBrkngGainSet 1;
BA_ "SignalType" SG_ 848 TrlrBrkngFrcOtpt "UNM";
BA_ "SignalLongName" SG_ 848 TrlrBrkngFrcOtpt "Trailer Braking Force Output";
BA_ "VNSigAllNodes" SG_ 848 TrlrBrkngFrcOtpt 1;
BA_ "SignalType" SG_ 848 ChkTrlrIO "BLN";
BA_ "SignalLongName" SG_ 848 ChkTrlrIO "Check Trailer Indication On";
BA_ "VNSigAllNodes" SG_ 848 ChkTrlrIO 1;
BA_ "SignalType" SG_ 848 TrlrHtchSwAtv_ITBC "BLN";
BA_ "SignalLongName" SG_ 848 TrlrHtchSwAtv_ITBC "Trailer Hitch Switch Active ITBC";
BA_ "VNSigAllNodes" SG_ 848 TrlrHtchSwAtv_ITBC 1;
BA_ "SignalType" SG_ 953 DslGlwTypReqd "ENM";
BA_ "SignalLongName" SG_ 953 DslGlwTypReqd "Diesel Glow Type Requested";
BA_ "VNSigAllNodes" SG_ 953 DslGlwTypReqd 1;
BA_ "SignalType" SG_ 953 RdctHtrCReq "ENM";
BA_ "SignalLongName" SG_ 953 RdctHtrCReq "Reductant Heater C Request";
BA_ "VNSigAllNodes" SG_ 953 RdctHtrCReq 1;
BA_ "SignalType" SG_ 953 RdctHtrBReq "ENM";
BA_ "SignalLongName" SG_ 953 RdctHtrBReq "Reductant Heater B Request";
BA_ "VNSigAllNodes" SG_ 953 RdctHtrBReq 1;
BA_ "SignalType" SG_ 953 RdctHtrAReq "ENM";
BA_ "SignalLongName" SG_ 953 RdctHtrAReq "Reductant Heater A Request";
BA_ "VNSigAllNodes" SG_ 953 RdctHtrAReq 1;
BA_ "SignalType" SG_ 953 EngPwrCnfg "ENM";
BA_ "SignalLongName" SG_ 953 EngPwrCnfg "Engine Power Configuration";
BA_ "VNSigAllNodes" SG_ 953 EngPwrCnfg 1;
BA_ "SignalType" SG_ 953 EngCntlSenPTRlyVltM "ENM";
BA_ "SignalLongName" SG_ 953 EngCntlSenPTRlyVltM "Engine Controller Sensed Powertrain Relay Voltage Mask";
BA_ "VNSigAllNodes" SG_ 953 EngCntlSenPTRlyVltM 1;
BA_ "SignalType" SG_ 953 EngCntlSenPTRlyVlt "UNM";
BA_ "SignalLongName" SG_ 953 EngCntlSenPTRlyVlt "Engine Controller Sensed Powertrain Relay Voltage";
BA_ "VNSigAllNodes" SG_ 953 EngCntlSenPTRlyVlt 1;
BA_ "SignalType" SG_ 953 CrntFlConsmpV "ENM";
BA_ "SignalLongName" SG_ 953 CrntFlConsmpV "Current Fuel Consumption Validity";
BA_ "VNSigAllNodes" SG_ 953 CrntFlConsmpV 1;
BA_ "SignalType" SG_ 953 CrntFlConsmp "UNM";
BA_ "SignalLongName" SG_ 953 CrntFlConsmp "Current Fuel Consumption";
BA_ "VNSigAllNodes" SG_ 953 CrntFlConsmp 1;
BA_ "SignalType" SG_ 953 InAirHtrDtyCyclCmnd "UNM";
BA_ "SignalLongName" SG_ 953 InAirHtrDtyCyclCmnd "Intake Air Heater Duty Cycle Command";
BA_ "VNSigAllNodes" SG_ 953 InAirHtrDtyCyclCmnd 1;
BA_ "SignalType" SG_ 953 DslPartFltrClngAlgActM "ENM";
BA_ "SignalLongName" SG_ 953 DslPartFltrClngAlgActM "Diesel Particle Filter Cleaning Algorithm Active Mask";
BA_ "VNSigAllNodes" SG_ 953 DslPartFltrClngAlgActM 1;
BA_ "SignalType" SG_ 953 DslPartFltrClngAlgAct "BLN";
BA_ "SignalLongName" SG_ 953 DslPartFltrClngAlgAct "Diesel Particle Filter Cleaning Algorithm Active";
BA_ "VNSigAllNodes" SG_ 953 DslPartFltrClngAlgAct 1;
BA_ "SignalType" SG_ 953 MassAirFloV "ENM";
BA_ "SignalLongName" SG_ 953 MassAirFloV "Mass Air Flow Validity";
BA_ "VNSigAllNodes" SG_ 953 MassAirFloV 1;
BA_ "SignalType" SG_ 953 MassAirFlo "UNM";
BA_ "SignalLongName" SG_ 953 MassAirFlo "Mass Air Flow";
BA_ "VNSigAllNodes" SG_ 953 MassAirFlo 1;
BA_ "SignalType" SG_ 953 GlwPlgReqdOn "BLN";
BA_ "SignalLongName" SG_ 953 GlwPlgReqdOn "Glow Plugs Requested On";
BA_ "VNSigAllNodes" SG_ 953 GlwPlgReqdOn 1;
BA_ "SignalType" SG_ 711 RdVltCrntTmpModInitStat "ENM";
BA_ "SignalLongName" SG_ 711 RdVltCrntTmpModInitStat "Redundant Voltage Current Temperature Module Initialization Status";
BA_ "VNSigAllNodes" SG_ 711 RdVltCrntTmpModInitStat 1;
BA_ "SignalType" SG_ 711 RdVltCrTmpMdCntOpFlt "BLN";
BA_ "SignalLongName" SG_ 711 RdVltCrTmpMdCntOpFlt "Redundant Voltage Current Temperature Module Contactor Open Fault";
BA_ "VNSigAllNodes" SG_ 711 RdVltCrTmpMdCntOpFlt 1;
BA_ "SignalType" SG_ 711 RdHVltBatPckVltV "ENM";
BA_ "SignalLongName" SG_ 711 RdHVltBatPckVltV "Redundant High Voltage Battery Pack Voltage Validity";
BA_ "VNSigAllNodes" SG_ 711 RdHVltBatPckVltV 1;
BA_ "SignalType" SG_ 711 RdHVltBatPckVltM "ENM";
BA_ "SignalLongName" SG_ 711 RdHVltBatPckVltM "Redundant High Voltage Battery Pack Voltage Mask";
BA_ "VNSigAllNodes" SG_ 711 RdHVltBatPckVltM 1;
BA_ "SignalType" SG_ 711 RdHVltBatPckVlt "UNM";
BA_ "SignalLongName" SG_ 711 RdHVltBatPckVlt "Redundant High Voltage Battery Pack Voltage";
BA_ "VNSigAllNodes" SG_ 711 RdHVltBatPckVlt 1;
BA_ "SignalType" SG_ 711 RdHVltBatPckCrntV "ENM";
BA_ "SignalLongName" SG_ 711 RdHVltBatPckCrntV "Redundant High Voltage Battery Pack Current Validity";
BA_ "VNSigAllNodes" SG_ 711 RdHVltBatPckCrntV 1;
BA_ "SignalType" SG_ 711 RdHVltBatPckCrntM "ENM";
BA_ "SignalLongName" SG_ 711 RdHVltBatPckCrntM "Redundant High Voltage Battery Pack Current Mask";
BA_ "VNSigAllNodes" SG_ 711 RdHVltBatPckCrntM 1;
BA_ "SignalType" SG_ 711 RdHVltBatPckCrnt "SNM";
BA_ "SignalLongName" SG_ 711 RdHVltBatPckCrnt "Redundant High Voltage Battery Pack Current";
BA_ "VNSigAllNodes" SG_ 711 RdHVltBatPckCrnt 1;
BA_ "SignalType" SG_ 711 RdntHVBatClOvrVltTstAct "BLN";
BA_ "SignalLongName" SG_ 711 RdntHVBatClOvrVltTstAct "Redundant High Voltage Battery Cell Over Voltage Test Active";
BA_ "VNSigAllNodes" SG_ 711 RdntHVBatClOvrVltTstAct 1;
BA_ "SignalType" SG_ 304 PedFrndlyAlrtCsStReq "ENM";
BA_ "SignalLongName" SG_ 304 PedFrndlyAlrtCsStReq "Pedestrian Friendly Alert Customization Setting Request";
BA_ "VNSigAllNodes" SG_ 304 PedFrndlyAlrtCsStReq 1;
BA_ "SignalType" SG_ 304 AlrmStat "ENM";
BA_ "SignalLongName" SG_ 304 AlrmStat "Alarm Status";
BA_ "VNSigAllNodes" SG_ 304 AlrmStat 1;
BA_ "SignalType" SG_ 1105 JmpStrtReq "BLN";
BA_ "SignalLongName" SG_ 1105 JmpStrtReq "Jump Start Requested";
BA_ "VNSigAllNodes" SG_ 1105 JmpStrtReq 1;
BA_ "SignalType" SG_ 1105 HybVehHiVltInvDisRqd "BLN";
BA_ "SignalLongName" SG_ 1105 HybVehHiVltInvDisRqd "Hybrid Vehicle High Voltage Inverter Disable Requested";
BA_ "VNSigAllNodes" SG_ 1105 HybVehHiVltInvDisRqd 1;
BA_ "SignalType" SG_ 1105 NESSRoSevSt "BLN";
BA_ "SignalLongName" SG_ 1105 NESSRoSevSt "Notification Event Severity Status : Rollover Severity Achieved";
BA_ "VNSigAllNodes" SG_ 1105 NESSRoSevSt 1;
BA_ "SignalType" SG_ 1105 NESSRiSiSevSt "BLN";
BA_ "SignalLongName" SG_ 1105 NESSRiSiSevSt "Notification Event Severity Status : Right Side Severity Achieved";
BA_ "VNSigAllNodes" SG_ 1105 NESSRiSiSevSt 1;
BA_ "SignalType" SG_ 1105 NESSReImpSevSt "BLN";
BA_ "SignalLongName" SG_ 1105 NESSReImpSevSt "Notification Event Severity Status : Rear Impact Severity Achieved";
BA_ "VNSigAllNodes" SG_ 1105 NESSReImpSevSt 1;
BA_ "SignalType" SG_ 1105 NESSLeSiSevSt "BLN";
BA_ "SignalLongName" SG_ 1105 NESSLeSiSevSt "Notification Event Severity Status : Left Side Severity Achieved";
BA_ "VNSigAllNodes" SG_ 1105 NESSLeSiSevSt 1;
BA_ "SignalType" SG_ 1105 NESSFrImpSt2SevSt "BLN";
BA_ "SignalLongName" SG_ 1105 NESSFrImpSt2SevSt "Notification Event Severity Status : Frontal Impact Stage 2 Severity Achieved";
BA_ "VNSigAllNodes" SG_ 1105 NESSFrImpSt2SevSt 1;
BA_ "SignalType" SG_ 1105 NESSFrImpSt1SevSt "BLN";
BA_ "SignalLongName" SG_ 1105 NESSFrImpSt1SevSt "Notification Event Severity Status : Frontal Impact Stage 1 Severity Achieved";
BA_ "VNSigAllNodes" SG_ 1105 NESSFrImpSt1SevSt 1;
BA_ "SignalType" SG_ 1105 NESSFrImpPreSevSt "BLN";
BA_ "SignalLongName" SG_ 1105 NESSFrImpPreSevSt "Notification Event Severity Status : Frontal Impact Pretensioner Severity Achieved";
BA_ "VNSigAllNodes" SG_ 1105 NESSFrImpPreSevSt 1;
BA_ "SignalType" SG_ 1105 ClmCntFrBlwFnSp "UNM";
BA_ "SignalLongName" SG_ 1105 ClmCntFrBlwFnSp "Climate Control Front Blower Fan Speed";
BA_ "VNSigAllNodes" SG_ 1105 ClmCntFrBlwFnSp 1;
BA_ "SignalType" SG_ 1005 EnhSvVehTopSpdLmR "ENM";
BA_ "SignalLongName" SG_ 1005 EnhSvVehTopSpdLmR "Enhanced Services Vehicle Top Speed Limit Request";
BA_ "VNSigAllNodes" SG_ 1005 EnhSvVehTopSpdLmR 1;
BA_ "SignalType" SG_ 1005 EnhSvVTpSpdLVlARC "UNM";
BA_ "SignalLongName" SG_ 1005 EnhSvVTpSpdLVlARC "Enhanced Services Vehicle Top Speed Limit Value Alive Rolling Count";
BA_ "VNSigAllNodes" SG_ 1005 EnhSvVTpSpdLVlARC 1;
BA_ "SignalType" SG_ 1005 EnhSvVehTopSpdLimP "UNM";
BA_ "SignalLongName" SG_ 1005 EnhSvVehTopSpdLimP "Enhanced Services Vehicle Top Speed Limit Password";
BA_ "VNSigAllNodes" SG_ 1005 EnhSvVehTopSpdLimP 1;
BA_ "SignalType" SG_ 1005 EnhSvVehTopSpdLim "UNM";
BA_ "SignalLongName" SG_ 1005 EnhSvVehTopSpdLim "Enhanced Services Vehicle Top Speed Limit Value";
BA_ "GenSigStartValue" SG_ 1005 EnhSvVehTopSpdLim 255;
BA_ "VNSigAllNodes" SG_ 1005 EnhSvVehTopSpdLim 1;
BA_ "SignalType" SG_ 688 StrtrGenSpdV "ENM";
BA_ "SignalLongName" SG_ 688 StrtrGenSpdV "Starter Generator Speed  Validity";
BA_ "VNSigAllNodes" SG_ 688 StrtrGenSpdV 1;
BA_ "SignalType" SG_ 688 StrtrGenSpd "UNM";
BA_ "SignalLongName" SG_ 688 StrtrGenSpd "Starter Generator Speed";
BA_ "VNSigAllNodes" SG_ 688 StrtrGenSpd 1;
BA_ "SignalType" SG_ 993 CstmrUsblSOCV "ENM";
BA_ "SignalLongName" SG_ 993 CstmrUsblSOCV "Customer Usable State of Charge Validity";
BA_ "VNSigAllNodes" SG_ 993 CstmrUsblSOCV 1;
BA_ "SignalType" SG_ 993 CstmrUsblSOC "UNM";
BA_ "SignalLongName" SG_ 993 CstmrUsblSOC "Customer Usable State of Charge";
BA_ "VNSigAllNodes" SG_ 993 CstmrUsblSOC 1;
BA_ "SignalType" SG_ 993 InstDrvEff "SNM";
BA_ "SignalLongName" SG_ 993 InstDrvEff "Instantaneous Drive Efficiency";
BA_ "VNSigAllNodes" SG_ 993 InstDrvEff 1;
BA_ "SignalType" SG_ 993 PwrPckAirInTempFlt "UNM";
BA_ "SignalLongName" SG_ 993 PwrPckAirInTempFlt "Power Pack Air Inlet Temperature Filtered";
BA_ "VNSigAllNodes" SG_ 993 PwrPckAirInTempFlt 1;
BA_ "SignalType" SG_ 993 PwrPkFnSpd "UNM";
BA_ "SignalLongName" SG_ 993 PwrPkFnSpd "Power Pack Fan Speed";
BA_ "VNSigAllNodes" SG_ 993 PwrPkFnSpd 1;
BA_ "SignalType" SG_ 993 JmpStrtStat "ENM";
BA_ "SignalLongName" SG_ 993 JmpStrtStat "Jump Start Status";
BA_ "VNSigAllNodes" SG_ 993 JmpStrtStat 1;
BA_ "SignalType" SG_ 993 HybVehHiVltSysDisbld "BLN";
BA_ "SignalLongName" SG_ 993 HybVehHiVltSysDisbld "Hybrid Vehicle High Voltage System Disabled";
BA_ "VNSigAllNodes" SG_ 993 HybVehHiVltSysDisbld 1;
BA_ "SignalType" SG_ 993 SvcHybridSysIO "BLN";
BA_ "SignalLongName" SG_ 993 SvcHybridSysIO "Service Hybrid System Indication On";
BA_ "VNSigAllNodes" SG_ 993 SvcHybridSysIO 1;
BA_ "SignalType" SG_ 993 HybMdDisp "ENM";
BA_ "SignalLongName" SG_ 993 HybMdDisp "Hybrid Mode Display";
BA_ "VNSigAllNodes" SG_ 993 HybMdDisp 1;
BA_ "SignalType" SG_ 490 SrvcFlSysPrkInOpnArIO "BLN";
BA_ "SignalLongName" SG_ 490 SrvcFlSysPrkInOpnArIO "Service Fuel System Park In Open Area Indication On";
BA_ "VNSigAllNodes" SG_ 490 SrvcFlSysPrkInOpnArIO 1;
BA_ "SignalType" SG_ 490 FuelTotCapTnk2 "UNM";
BA_ "SignalLongName" SG_ 490 FuelTotCapTnk2 "Fuel Total Capacity Tank 2";
BA_ "VNSigAllNodes" SG_ 490 FuelTotCapTnk2 1;
BA_ "SignalType" SG_ 490 FlLvlTank2PctV "ENM";
BA_ "SignalLongName" SG_ 490 FlLvlTank2PctV "Fuel Level Tank 2 Percent Validity";
BA_ "VNSigAllNodes" SG_ 490 FlLvlTank2PctV 1;
BA_ "SignalType" SG_ 490 FlLvlTank2Pct "UNM";
BA_ "SignalLongName" SG_ 490 FlLvlTank2Pct "Fuel Level Tank 2 Percent";
BA_ "VNSigAllNodes" SG_ 490 FlLvlTank2Pct 1;
BA_ "SignalType" SG_ 490 AltFuelPHeatAct "BLN";
BA_ "SignalLongName" SG_ 490 AltFuelPHeatAct "Alternative Fuel Pre-heating Active";
BA_ "VNSigAllNodes" SG_ 490 AltFuelPHeatAct 1;
BA_ "SignalType" SG_ 490 AltFuelMdReqDndIO "BLN";
BA_ "SignalLongName" SG_ 490 AltFuelMdReqDndIO "Alternative Fuel Mode Request Denied Indication On";
BA_ "VNSigAllNodes" SG_ 490 AltFuelMdReqDndIO 1;
BA_ "SignalType" SG_ 490 AltFuelLvlLo "BLN";
BA_ "SignalLongName" SG_ 490 AltFuelLvlLo "Alternative Fuel Level Low";
BA_ "VNSigAllNodes" SG_ 490 AltFuelLvlLo 1;
BA_ "SignalType" SG_ 490 AltFuelAccWrnngAct "BLN";
BA_ "SignalLongName" SG_ 490 AltFuelAccWrnngAct "Alternative Fuel Acceleration Warning Active";
BA_ "VNSigAllNodes" SG_ 490 AltFuelAccWrnngAct 1;
BA_ "SignalType" SG_ 490 FuelMdStat "ENM";
BA_ "SignalLongName" SG_ 490 FuelMdStat "Fuel Mode Status";
BA_ "VNSigAllNodes" SG_ 490 FuelMdStat 1;
BA_ "SignalType" SG_ 431 TransVehTopSpdLim "UNM";
BA_ "SignalLongName" SG_ 431 TransVehTopSpdLim "Transmission Vehicle Top Speed Limit Value";
BA_ "VNSigAllNodes" SG_ 431 TransVehTopSpdLim 1;
BA_ "SignalType" SG_ 431 TransMinVoltReq "UNM";
BA_ "SignalLongName" SG_ 431 TransMinVoltReq "Transmission Minimum Voltage Request";
BA_ "VNSigAllNodes" SG_ 431 TransMinVoltReq 1;
BA_ "SignalType" SG_ 431 TDslPrtFltrIdlRgtnMdAtv "BLN";
BA_ "SignalLongName" SG_ 431 TDslPrtFltrIdlRgtnMdAtv "Transmission Diesel Particulate Filter Idle Regeneration Mode Active";
BA_ "VNSigAllNodes" SG_ 431 TDslPrtFltrIdlRgtnMdAtv 1;
BA_ "SignalType" SG_ 431 DrvlneTrqStabStat "ENM";
BA_ "SignalLongName" SG_ 431 DrvlneTrqStabStat "Driveline Torque Stability Status";
BA_ "VNSigAllNodes" SG_ 431 DrvlneTrqStabStat 1;
BA_ "SignalType" SG_ 431 TrnsTrqCnvCltCmdMdF "BLN";
BA_ "SignalLongName" SG_ 431 TrnsTrqCnvCltCmdMdF "Transmission Torque Converter Clutch Commanded Mode Failure";
BA_ "VNSigAllNodes" SG_ 431 TrnsTrqCnvCltCmdMdF 1;
BA_ "SignalType" SG_ 431 AutoTransGrSftDirectFl "BLN";
BA_ "SignalLongName" SG_ 431 AutoTransGrSftDirectFl "Automatic Transmission Gear Shift Direction Failure";
BA_ "VNSigAllNodes" SG_ 431 AutoTransGrSftDirectFl 1;
BA_ "SignalType" SG_ 431 AutoTransGrSftDirect "ENM";
BA_ "SignalLongName" SG_ 431 AutoTransGrSftDirect "Automatic Transmission Gear Shift Direction";
BA_ "VNSigAllNodes" SG_ 431 AutoTransGrSftDirect 1;
BA_ "SignalType" SG_ 431 TrnsTrqCnvCltCmndMd "ENM";
BA_ "SignalLongName" SG_ 431 TrnsTrqCnvCltCmndMd "Transmission Torque Converter Clutch Commanded Mode";
BA_ "GenSigStartValue" SG_ 431 TrnsTrqCnvCltCmndMd 7;
BA_ "VNSigAllNodes" SG_ 431 TrnsTrqCnvCltCmndMd 1;
BA_ "SignalType" SG_ 431 TrnsTrqCnvCltDsrSlp "SNM";
BA_ "SignalLongName" SG_ 431 TrnsTrqCnvCltDsrSlp "Transmission Torque Converter Clutch Desired Slip";
BA_ "VNSigAllNodes" SG_ 431 TrnsTrqCnvCltDsrSlp 1;
BA_ "SignalType" SG_ 431 TrnsStWntrMdOvrd "ENM";
BA_ "SignalLongName" SG_ 431 TrnsStWntrMdOvrd "Transmission State Winter Mode Override";
BA_ "VNSigAllNodes" SG_ 431 TrnsStWntrMdOvrd 1;
BA_ "SignalType" SG_ 431 TrnsStTwHaulMdOvrd "ENM";
BA_ "SignalLongName" SG_ 431 TrnsStTwHaulMdOvrd "Transmission State Tow Haul Mode Override";
BA_ "VNSigAllNodes" SG_ 431 TrnsStTwHaulMdOvrd 1;
BA_ "SignalType" SG_ 431 TrnsStSprtMdOvrd "ENM";
BA_ "SignalLongName" SG_ 431 TrnsStSprtMdOvrd "Transmission State Sport Mode Override";
BA_ "VNSigAllNodes" SG_ 431 TrnsStSprtMdOvrd 1;
BA_ "SignalType" SG_ 431 TrnsStEconMdOvrd "ENM";
BA_ "SignalLongName" SG_ 431 TrnsStEconMdOvrd "Transmission State Economy Mode Override";
BA_ "VNSigAllNodes" SG_ 431 TrnsStEconMdOvrd 1;
BA_ "SignalType" SG_ 431 TrnsInpCltchStat "ENM";
BA_ "SignalLongName" SG_ 431 TrnsInpCltchStat "Transmission Input Clutch Status";
BA_ "VNSigAllNodes" SG_ 431 TrnsInpCltchStat 1;
BA_ "SignalType" SG_ 431 TrnsAntcptdCrpTrqRRnV "ENM";
BA_ "SignalLongName" SG_ 431 TrnsAntcptdCrpTrqRRnV "Transmission Anticipated Creep Torque Reduced Range Validity";
BA_ "VNSigAllNodes" SG_ 431 TrnsAntcptdCrpTrqRRnV 1;
BA_ "SignalType" SG_ 431 TrnsAntcptdCrpTrqRRn "UNM";
BA_ "SignalLongName" SG_ 431 TrnsAntcptdCrpTrqRRn "Transmission Anticipated Creep Torque Reduced Range";
BA_ "VNSigAllNodes" SG_ 431 TrnsAntcptdCrpTrqRRn 1;
BA_ "SignalType" SG_ 431 TrnCltAdpAtv "BLN";
BA_ "SignalLongName" SG_ 431 TrnCltAdpAtv "Transmission Clutch Adaptation Active";
BA_ "VNSigAllNodes" SG_ 431 TrnCltAdpAtv 1;
BA_ "SignalType" SG_ 431 TransCrnkPermsnStat "ENM";
BA_ "SignalLongName" SG_ 431 TransCrnkPermsnStat "Transmission Crank Permission Status";
BA_ "VNSigAllNodes" SG_ 431 TransCrnkPermsnStat 1;
BA_ "SignalType" SG_ 431 WrmUpShftPtrn "ENM";
BA_ "SignalLongName" SG_ 431 WrmUpShftPtrn "Warm Up Shift Pattern Status";
BA_ "VNSigAllNodes" SG_ 431 WrmUpShftPtrn 1;
BA_ "SignalType" SG_ 715 ACCATC_SplREngInpR "BLN";
BA_ "PacketOrder" SG_ 715 ACCATC_SplREngInpR 4;
BA_ "SignalLongName" SG_ 715 ACCATC_SplREngInpR "Adaptive Cruise Control Axle Torque Command : Special Re-engagement Input Required";
BA_ "VNSigAllNodes" SG_ 715 ACCATC_SplREngInpR 1;
BA_ "SignalType" SG_ 715 ACCATC_DrvAstdGoSt "ENM";
BA_ "PacketOrder" SG_ 715 ACCATC_DrvAstdGoSt 3;
BA_ "SignalLongName" SG_ 715 ACCATC_DrvAstdGoSt "Adaptive Cruise Control Axle Torque Command : Driver Assisted Go State";
BA_ "VNSigAllNodes" SG_ 715 ACCATC_DrvAstdGoSt 1;
BA_ "SignalType" SG_ 715 ACCATC_AxlTrqRq "UNM";
BA_ "PacketOrder" SG_ 715 ACCATC_AxlTrqRq 6;
BA_ "SignalLongName" SG_ 715 ACCATC_AxlTrqRq "Adaptive Cruise Control Axle Torque Command : Axle Torque Request";
BA_ "VNSigAllNodes" SG_ 715 ACCATC_AxlTrqRq 1;
BA_ "SignalType" SG_ 715 ACCATC_ACCTyp "ENM";
BA_ "PacketOrder" SG_ 715 ACCATC_ACCTyp 2;
BA_ "SignalLongName" SG_ 715 ACCATC_ACCTyp "Adaptive Cruise Control Axle Torque Command : Adaptive Cruise Control Type";
BA_ "VNSigAllNodes" SG_ 715 ACCATC_ACCTyp 1;
BA_ "SignalType" SG_ 715 ACCATC_ACCAct "BLN";
BA_ "PacketOrder" SG_ 715 ACCATC_ACCAct 1;
BA_ "SignalLongName" SG_ 715 ACCATC_ACCAct "Adaptive Cruise Control Axle Torque Command : Adaptive Cruise Control Active";
BA_ "VNSigAllNodes" SG_ 715 ACCATC_ACCAct 1;
BA_ "SignalType" SG_ 715 ACCAxlTrqCmdProt "UNM";
BA_ "SignalLongName" SG_ 715 ACCAxlTrqCmdProt "Adaptive Cruise Control Axle torque Command Protection";
BA_ "VNSigAllNodes" SG_ 715 ACCAxlTrqCmdProt 1;
BA_ "SignalType" SG_ 715 ACCCmndAlvRlgCnt "UNM";
BA_ "SignalLongName" SG_ 715 ACCCmndAlvRlgCnt "Adaptive Cruise Control Command Alive Rolling Count";
BA_ "VNSigAllNodes" SG_ 715 ACCCmndAlvRlgCnt 1;
BA_ "SignalType" SG_ 1267 VehMassNom "UNM";
BA_ "SignalLongName" SG_ 1267 VehMassNom "Vehicle Mass Nominal";
BA_ "VNSigAllNodes" SG_ 1267 VehMassNom 1;
BA_ "SignalType" SG_ 453 DrvIntndAxlTrqV "ENM";
BA_ "SignalLongName" SG_ 453 DrvIntndAxlTrqV "Driver Intended Axle Torque Validity";
BA_ "VNSigAllNodes" SG_ 453 DrvIntndAxlTrqV 1;
BA_ "SignalType" SG_ 453 DrvIntndAxlTrqMinV "ENM";
BA_ "SignalLongName" SG_ 453 DrvIntndAxlTrqMinV "Driver Intended Axle Torque Minimum Validity";
BA_ "VNSigAllNodes" SG_ 453 DrvIntndAxlTrqMinV 1;
BA_ "SignalType" SG_ 453 DrvIntndAxlTrqMin "UNM";
BA_ "SignalLongName" SG_ 453 DrvIntndAxlTrqMin "Driver Intended Axle Torque Minimum";
BA_ "VNSigAllNodes" SG_ 453 DrvIntndAxlTrqMin 1;
BA_ "SignalType" SG_ 453 DrvIntndAxlTrqMaxV "ENM";
BA_ "SignalLongName" SG_ 453 DrvIntndAxlTrqMaxV "Driver Intended Axle Torque Maximum Validity";
BA_ "VNSigAllNodes" SG_ 453 DrvIntndAxlTrqMaxV 1;
BA_ "SignalType" SG_ 453 DrvIntndAxlTrqMax "UNM";
BA_ "SignalLongName" SG_ 453 DrvIntndAxlTrqMax "Driver Intended Axle Torque Maximum";
BA_ "GenSigStartValue" SG_ 453 DrvIntndAxlTrqMax 32767;
BA_ "VNSigAllNodes" SG_ 453 DrvIntndAxlTrqMax 1;
BA_ "SignalType" SG_ 453 DrvIntndAxlTrq "UNM";
BA_ "SignalLongName" SG_ 453 DrvIntndAxlTrq "Driver Intended Axle Torque";
BA_ "GenSigStartValue" SG_ 453 DrvIntndAxlTrq 11267;
BA_ "VNSigAllNodes" SG_ 453 DrvIntndAxlTrq 1;
BA_REL_ "GenSigSuprvResp" BU_SG_REL_ TCM_HS SG_ 647 DrPTGrdBrkDsbMdCmd 1;
BA_REL_ "GenSigTimeoutMsg" BU_SG_REL_ TCM_HS SG_ 647 DrPTGrdBrkDsbMdCmd 647;
BA_REL_ "GenSigTimeoutTime" BU_SG_REL_ TCM_HS SG_ 647 DrPTGrdBrkDsbMdCmd 62;
BA_REL_ "GenSigSuprvResp" BU_SG_REL_ TCM_HS SG_ 647 DrvWntrMdCmd 1;
BA_REL_ "GenSigTimeoutMsg" BU_SG_REL_ TCM_HS SG_ 647 DrvWntrMdCmd 647;
BA_REL_ "GenSigTimeoutTime" BU_SG_REL_ TCM_HS SG_ 647 DrvWntrMdCmd 62;
BA_REL_ "GenSigSuprvResp" BU_SG_REL_ TCM_HS SG_ 647 DrvTwHaulMdCmd 1;
BA_REL_ "GenSigTimeoutMsg" BU_SG_REL_ TCM_HS SG_ 647 DrvTwHaulMdCmd 647;
BA_REL_ "GenSigTimeoutTime" BU_SG_REL_ TCM_HS SG_ 647 DrvTwHaulMdCmd 62;
BA_REL_ "GenSigSuprvResp" BU_SG_REL_ TCM_HS SG_ 647 DrvSprtMdCmd 1;
BA_REL_ "GenSigTimeoutMsg" BU_SG_REL_ TCM_HS SG_ 647 DrvSprtMdCmd 647;
BA_REL_ "GenSigTimeoutTime" BU_SG_REL_ TCM_HS SG_ 647 DrvSprtMdCmd 62;
BA_REL_ "GenSigSuprvResp" BU_SG_REL_ HCP_HS SG_ 647 DrvSprtMdCmd 1;
BA_REL_ "GenSigTimeoutMsg" BU_SG_REL_ HCP_HS SG_ 647 DrvSprtMdCmd 647;
BA_REL_ "GenSigTimeoutTime" BU_SG_REL_ HCP_HS SG_ 647 DrvSprtMdCmd 62;
BA_REL_ "GenSigSuprvResp" BU_SG_REL_ TCM_HS SG_ 647 DrvEconMdCmd 1;
BA_REL_ "GenSigTimeoutMsg" BU_SG_REL_ TCM_HS SG_ 647 DrvEconMdCmd 647;
BA_REL_ "GenSigTimeoutTime" BU_SG_REL_ TCM_HS SG_ 647 DrvEconMdCmd 62;
BA_REL_ "GenSigSuprvResp" BU_SG_REL_ ICCM_OBD_HS SG_ 647 EngCntrlDtrmdTrfCRng 1;
BA_REL_ "GenSigTimeoutMsg" BU_SG_REL_ ICCM_OBD_HS SG_ 647 EngCntrlDtrmdTrfCRng 647;
BA_REL_ "GenSigTimeoutTime" BU_SG_REL_ ICCM_OBD_HS SG_ 647 EngCntrlDtrmdTrfCRng 250;
BA_REL_ "GenSigSuprvResp" BU_SG_REL_ ICCM_HS SG_ 647 EngCntrlDtrmdTrfCRng 1;
BA_REL_ "GenSigTimeoutMsg" BU_SG_REL_ ICCM_HS SG_ 647 EngCntrlDtrmdTrfCRng 647;
BA_REL_ "GenSigTimeoutTime" BU_SG_REL_ ICCM_HS SG_ 647 EngCntrlDtrmdTrfCRng 250;
BA_REL_ "GenSigSuprvResp" BU_SG_REL_ EBCM_OBD_HS SG_ 647 EngCtrlUtldTrnCRgPVal 1;
BA_REL_ "GenSigTimeoutMsg" BU_SG_REL_ EBCM_OBD_HS SG_ 647 EngCtrlUtldTrnCRgPVal 647;
BA_REL_ "GenSigTimeoutTime" BU_SG_REL_ EBCM_OBD_HS SG_ 647 EngCtrlUtldTrnCRgPVal 250;
BA_REL_ "GenSigSuprvResp" BU_SG_REL_ EBCM_HS SG_ 647 EngCtrlUtldTrnCRgPVal 1;
BA_REL_ "GenSigTimeoutMsg" BU_SG_REL_ EBCM_HS SG_ 647 EngCtrlUtldTrnCRgPVal 647;
BA_REL_ "GenSigTimeoutTime" BU_SG_REL_ EBCM_HS SG_ 647 EngCtrlUtldTrnCRgPVal 250;
BA_REL_ "GenSigSuprvResp" BU_SG_REL_ EBCM_OBD_HS SG_ 647 EngCntrlUtldTrnCsRng 1;
BA_REL_ "GenSigTimeoutMsg" BU_SG_REL_ EBCM_OBD_HS SG_ 647 EngCntrlUtldTrnCsRng 647;
BA_REL_ "GenSigTimeoutTime" BU_SG_REL_ EBCM_OBD_HS SG_ 647 EngCntrlUtldTrnCsRng 250;
BA_REL_ "GenSigSuprvResp" BU_SG_REL_ EBCM_HS SG_ 647 EngCntrlUtldTrnCsRng 1;
BA_REL_ "GenSigTimeoutMsg" BU_SG_REL_ EBCM_HS SG_ 647 EngCntrlUtldTrnCsRng 647;
BA_REL_ "GenSigTimeoutTime" BU_SG_REL_ EBCM_HS SG_ 647 EngCntrlUtldTrnCsRng 250;
BA_REL_ "GenSigSuprvResp" BU_SG_REL_ EBCM_OBD_HS SG_ 647 EngCntrlUtldTrnCsRgIn 1;
BA_REL_ "GenSigTimeoutMsg" BU_SG_REL_ EBCM_OBD_HS SG_ 647 EngCntrlUtldTrnCsRgIn 647;
BA_REL_ "GenSigTimeoutTime" BU_SG_REL_ EBCM_OBD_HS SG_ 647 EngCntrlUtldTrnCsRgIn 250;
BA_REL_ "GenSigSuprvResp" BU_SG_REL_ EBCM_HS SG_ 647 EngCntrlUtldTrnCsRgIn 1;
BA_REL_ "GenSigTimeoutMsg" BU_SG_REL_ EBCM_HS SG_ 647 EngCntrlUtldTrnCsRgIn 647;
BA_REL_ "GenSigTimeoutTime" BU_SG_REL_ EBCM_HS SG_ 647 EngCntrlUtldTrnCsRgIn 250;
BA_REL_ "GenSigSuprvResp" BU_SG_REL_ EBCM_OBD_HS SG_ 647 EngCtrlUtldTrnCRgARC 1;
BA_REL_ "GenSigTimeoutMsg" BU_SG_REL_ EBCM_OBD_HS SG_ 647 EngCtrlUtldTrnCRgARC 647;
BA_REL_ "GenSigTimeoutTime" BU_SG_REL_ EBCM_OBD_HS SG_ 647 EngCtrlUtldTrnCRgARC 250;
BA_REL_ "GenSigSuprvResp" BU_SG_REL_ EBCM_HS SG_ 647 EngCtrlUtldTrnCRgARC 1;
BA_REL_ "GenSigTimeoutMsg" BU_SG_REL_ EBCM_HS SG_ 647 EngCtrlUtldTrnCRgARC 647;
BA_REL_ "GenSigTimeoutTime" BU_SG_REL_ EBCM_HS SG_ 647 EngCtrlUtldTrnCRgARC 250;
BA_REL_ "GenSigSuprvResp" BU_SG_REL_ VICM_HS SG_ 995 RdHVBatMinSnsTmp 1;
BA_REL_ "GenSigTimeoutMsg" BU_SG_REL_ VICM_HS SG_ 995 RdHVBatMinSnsTmp 995;
BA_REL_ "GenSigTimeoutTime" BU_SG_REL_ VICM_HS SG_ 995 RdHVBatMinSnsTmp 250;
BA_REL_ "GenSigSuprvResp" BU_SG_REL_ VICM_HS SG_ 995 RdHVltBatMinClVlt 1;
BA_REL_ "GenSigTimeoutMsg" BU_SG_REL_ VICM_HS SG_ 995 RdHVltBatMinClVlt 995;
BA_REL_ "GenSigTimeoutTime" BU_SG_REL_ VICM_HS SG_ 995 RdHVltBatMinClVlt 250;
BA_REL_ "GenSigSuprvResp" BU_SG_REL_ VICM_HS SG_ 995 RdHVltBatMaxSnsTmp 1;
BA_REL_ "GenSigTimeoutMsg" BU_SG_REL_ VICM_HS SG_ 995 RdHVltBatMaxSnsTmp 995;
BA_REL_ "GenSigTimeoutTime" BU_SG_REL_ VICM_HS SG_ 995 RdHVltBatMaxSnsTmp 250;
BA_REL_ "GenSigSuprvResp" BU_SG_REL_ VICM_HS SG_ 995 RdHVltBatMaxClVlt 1;
BA_REL_ "GenSigTimeoutMsg" BU_SG_REL_ VICM_HS SG_ 995 RdHVltBatMaxClVlt 995;
BA_REL_ "GenSigTimeoutTime" BU_SG_REL_ VICM_HS SG_ 995 RdHVltBatMaxClVlt 250;
BA_REL_ "GenSigSuprvResp" BU_SG_REL_ VICM_HS SG_ 995 RdHVltBatAvgClVlt 1;
BA_REL_ "GenSigTimeoutMsg" BU_SG_REL_ VICM_HS SG_ 995 RdHVltBatAvgClVlt 995;
BA_REL_ "GenSigTimeoutTime" BU_SG_REL_ VICM_HS SG_ 995 RdHVltBatAvgClVlt 250;
BA_REL_ "GenSigSuprvResp" BU_SG_REL_ ECM_HS SG_ 209 ChsBrkPdlPsERltdPVal 1;
BA_REL_ "GenSigTimeoutMsg" BU_SG_REL_ ECM_HS SG_ 209 ChsBrkPdlPsERltdPVal 209;
BA_REL_ "GenSigTimeoutTime" BU_SG_REL_ ECM_HS SG_ 209 ChsBrkPdlPsERltdPVal 250;
BA_REL_ "GenSigSuprvResp" BU_SG_REL_ ECM_HS SG_ 209 ChsBrkPdlPsERltdARC 1;
BA_REL_ "GenSigTimeoutMsg" BU_SG_REL_ ECM_HS SG_ 209 ChsBrkPdlPsERltdARC 209;
BA_REL_ "GenSigTimeoutTime" BU_SG_REL_ ECM_HS SG_ 209 ChsBrkPdlPsERltdARC 250;
BA_REL_ "GenSigSuprvResp" BU_SG_REL_ ECM_HS SG_ 209 ChsBrkPdlPsERltd 1;
BA_REL_ "GenSigTimeoutMsg" BU_SG_REL_ ECM_HS SG_ 209 ChsBrkPdlPsERltd 209;
BA_REL_ "GenSigTimeoutTime" BU_SG_REL_ ECM_HS SG_ 209 ChsBrkPdlPsERltd 250;
BA_REL_ "GenSigSuprvResp" BU_SG_REL_ VICM_HS SG_ 209 DrvIntndTtlBrkTrq 1;
BA_REL_ "GenSigTimeoutMsg" BU_SG_REL_ VICM_HS SG_ 209 DrvIntndTtlBrkTrq 209;
BA_REL_ "GenSigTimeoutTime" BU_SG_REL_ VICM_HS SG_ 209 DrvIntndTtlBrkTrq 250;
BA_REL_ "GenSigSuprvResp" BU_SG_REL_ VICM_HS SG_ 554 ElecPrkBrkAvailStat 1;
BA_REL_ "GenSigTimeoutMsg" BU_SG_REL_ VICM_HS SG_ 554 ElecPrkBrkAvailStat 554;
BA_REL_ "GenSigTimeoutTime" BU_SG_REL_ VICM_HS SG_ 554 ElecPrkBrkAvailStat 250;
BA_REL_ "GenSigSuprvResp" BU_SG_REL_ VICM_HS SG_ 554 ElecPrkBrkApplStat 1;
BA_REL_ "GenSigTimeoutMsg" BU_SG_REL_ VICM_HS SG_ 554 ElecPrkBrkApplStat 554;
BA_REL_ "GenSigTimeoutTime" BU_SG_REL_ VICM_HS SG_ 554 ElecPrkBrkApplStat 250;
BA_REL_ "GenSigSuprvResp" BU_SG_REL_ ICCM_OBD_HS SG_ 487 CmmndAirFuelRatio 1;
BA_REL_ "GenSigTimeoutMsg" BU_SG_REL_ ICCM_OBD_HS SG_ 487 CmmndAirFuelRatio 487;
BA_REL_ "GenSigTimeoutTime" BU_SG_REL_ ICCM_OBD_HS SG_ 487 CmmndAirFuelRatio 31;
BA_REL_ "GenSigSuprvResp" BU_SG_REL_ ICCM_HS SG_ 487 CmmndAirFuelRatio 1;
BA_REL_ "GenSigTimeoutMsg" BU_SG_REL_ ICCM_HS SG_ 487 CmmndAirFuelRatio 487;
BA_REL_ "GenSigTimeoutTime" BU_SG_REL_ ICCM_HS SG_ 487 CmmndAirFuelRatio 31;
BA_REL_ "GenSigSuprvResp" BU_SG_REL_ FSCM_ITBC_HS SG_ 487 CmmndAirFuelRatio 1;
BA_REL_ "GenSigTimeoutMsg" BU_SG_REL_ FSCM_ITBC_HS SG_ 487 CmmndAirFuelRatio 487;
BA_REL_ "GenSigTimeoutTime" BU_SG_REL_ FSCM_ITBC_HS SG_ 487 CmmndAirFuelRatio 31;
BA_REL_ "GenSigSuprvResp" BU_SG_REL_ FSCM_HS SG_ 487 CmmndAirFuelRatio 1;
BA_REL_ "GenSigTimeoutMsg" BU_SG_REL_ FSCM_HS SG_ 487 CmmndAirFuelRatio 487;
BA_REL_ "GenSigTimeoutTime" BU_SG_REL_ FSCM_HS SG_ 487 CmmndAirFuelRatio 31;
BA_REL_ "GenSigSuprvResp" BU_SG_REL_ ICCM_OBD_HS SG_ 487 InstFuelFlowEst 1;
BA_REL_ "GenSigTimeoutMsg" BU_SG_REL_ ICCM_OBD_HS SG_ 487 InstFuelFlowEst 487;
BA_REL_ "GenSigTimeoutTime" BU_SG_REL_ ICCM_OBD_HS SG_ 487 InstFuelFlowEst 31;
BA_REL_ "GenSigSuprvResp" BU_SG_REL_ ICCM_HS SG_ 487 InstFuelFlowEst 1;
BA_REL_ "GenSigTimeoutMsg" BU_SG_REL_ ICCM_HS SG_ 487 InstFuelFlowEst 487;
BA_REL_ "GenSigTimeoutTime" BU_SG_REL_ ICCM_HS SG_ 487 InstFuelFlowEst 31;
BA_REL_ "GenSigSuprvResp" BU_SG_REL_ FSCM_ITBC_HS SG_ 487 InstFuelFlowEst 1;
BA_REL_ "GenSigTimeoutMsg" BU_SG_REL_ FSCM_ITBC_HS SG_ 487 InstFuelFlowEst 487;
BA_REL_ "GenSigTimeoutTime" BU_SG_REL_ FSCM_ITBC_HS SG_ 487 InstFuelFlowEst 31;
BA_REL_ "GenSigSuprvResp" BU_SG_REL_ FSCM_HS SG_ 487 InstFuelFlowEst 1;
BA_REL_ "GenSigTimeoutMsg" BU_SG_REL_ FSCM_HS SG_ 487 InstFuelFlowEst 487;
BA_REL_ "GenSigTimeoutTime" BU_SG_REL_ FSCM_HS SG_ 487 InstFuelFlowEst 31;
BA_REL_ "GenSigSuprvResp" BU_SG_REL_ ICCM_OBD_HS SG_ 487 FuelDelPressRqd 1;
BA_REL_ "GenSigTimeoutMsg" BU_SG_REL_ ICCM_OBD_HS SG_ 487 FuelDelPressRqd 487;
BA_REL_ "GenSigTimeoutTime" BU_SG_REL_ ICCM_OBD_HS SG_ 487 FuelDelPressRqd 31;
BA_REL_ "GenSigSuprvResp" BU_SG_REL_ ICCM_HS SG_ 487 FuelDelPressRqd 1;
BA_REL_ "GenSigTimeoutMsg" BU_SG_REL_ ICCM_HS SG_ 487 FuelDelPressRqd 487;
BA_REL_ "GenSigTimeoutTime" BU_SG_REL_ ICCM_HS SG_ 487 FuelDelPressRqd 31;
BA_REL_ "GenSigSuprvResp" BU_SG_REL_ FSCM_ITBC_HS SG_ 487 FuelDelPressRqd 1;
BA_REL_ "GenSigTimeoutMsg" BU_SG_REL_ FSCM_ITBC_HS SG_ 487 FuelDelPressRqd 487;
BA_REL_ "GenSigTimeoutTime" BU_SG_REL_ FSCM_ITBC_HS SG_ 487 FuelDelPressRqd 31;
BA_REL_ "GenSigSuprvResp" BU_SG_REL_ FSCM_HS SG_ 487 FuelDelPressRqd 1;
BA_REL_ "GenSigTimeoutMsg" BU_SG_REL_ FSCM_HS SG_ 487 FuelDelPressRqd 487;
BA_REL_ "GenSigTimeoutTime" BU_SG_REL_ FSCM_HS SG_ 487 FuelDelPressRqd 31;
BA_REL_ "GenSigSuprvResp" BU_SG_REL_ ICCM_OBD_HS SG_ 487 EngRunng 1;
BA_REL_ "GenSigTimeoutMsg" BU_SG_REL_ ICCM_OBD_HS SG_ 487 EngRunng 487;
BA_REL_ "GenSigTimeoutTime" BU_SG_REL_ ICCM_OBD_HS SG_ 487 EngRunng 31;
BA_REL_ "GenSigSuprvResp" BU_SG_REL_ ICCM_HS SG_ 487 EngRunng 1;
BA_REL_ "GenSigTimeoutMsg" BU_SG_REL_ ICCM_HS SG_ 487 EngRunng 487;
BA_REL_ "GenSigTimeoutTime" BU_SG_REL_ ICCM_HS SG_ 487 EngRunng 31;
BA_REL_ "GenSigSuprvResp" BU_SG_REL_ FSCM_ITBC_HS SG_ 487 EngRunng 1;
BA_REL_ "GenSigTimeoutMsg" BU_SG_REL_ FSCM_ITBC_HS SG_ 487 EngRunng 487;
BA_REL_ "GenSigTimeoutTime" BU_SG_REL_ FSCM_ITBC_HS SG_ 487 EngRunng 31;
BA_REL_ "GenSigSuprvResp" BU_SG_REL_ FSCM_HS SG_ 487 EngRunng 1;
BA_REL_ "GenSigTimeoutMsg" BU_SG_REL_ FSCM_HS SG_ 487 EngRunng 487;
BA_REL_ "GenSigTimeoutTime" BU_SG_REL_ FSCM_HS SG_ 487 EngRunng 31;
BA_REL_ "GenSigSuprvResp" BU_SG_REL_ ICCM_OBD_HS SG_ 487 FlPmpEDscOtptCmdSta 1;
BA_REL_ "GenSigTimeoutMsg" BU_SG_REL_ ICCM_OBD_HS SG_ 487 FlPmpEDscOtptCmdSta 487;
BA_REL_ "GenSigTimeoutTime" BU_SG_REL_ ICCM_OBD_HS SG_ 487 FlPmpEDscOtptCmdSta 31;
BA_REL_ "GenSigSuprvResp" BU_SG_REL_ ICCM_HS SG_ 487 FlPmpEDscOtptCmdSta 1;
BA_REL_ "GenSigTimeoutMsg" BU_SG_REL_ ICCM_HS SG_ 487 FlPmpEDscOtptCmdSta 487;
BA_REL_ "GenSigTimeoutTime" BU_SG_REL_ ICCM_HS SG_ 487 FlPmpEDscOtptCmdSta 31;
BA_REL_ "GenSigSuprvResp" BU_SG_REL_ FSCM_ITBC_HS SG_ 487 FlPmpEDscOtptCmdSta 1;
BA_REL_ "GenSigTimeoutMsg" BU_SG_REL_ FSCM_ITBC_HS SG_ 487 FlPmpEDscOtptCmdSta 487;
BA_REL_ "GenSigTimeoutTime" BU_SG_REL_ FSCM_ITBC_HS SG_ 487 FlPmpEDscOtptCmdSta 31;
BA_REL_ "GenSigSuprvResp" BU_SG_REL_ FSCM_HS SG_ 487 FlPmpEDscOtptCmdSta 1;
BA_REL_ "GenSigTimeoutMsg" BU_SG_REL_ FSCM_HS SG_ 487 FlPmpEDscOtptCmdSta 487;
BA_REL_ "GenSigTimeoutTime" BU_SG_REL_ FSCM_HS SG_ 487 FlPmpEDscOtptCmdSta 31;
BA_REL_ "GenSigSuprvResp" BU_SG_REL_ ICCM_OBD_HS SG_ 487 FuelCntlSysFltPrsnt 1;
BA_REL_ "GenSigTimeoutMsg" BU_SG_REL_ ICCM_OBD_HS SG_ 487 FuelCntlSysFltPrsnt 487;
BA_REL_ "GenSigTimeoutTime" BU_SG_REL_ ICCM_OBD_HS SG_ 487 FuelCntlSysFltPrsnt 31;
BA_REL_ "GenSigSuprvResp" BU_SG_REL_ ICCM_HS SG_ 487 FuelCntlSysFltPrsnt 1;
BA_REL_ "GenSigTimeoutMsg" BU_SG_REL_ ICCM_HS SG_ 487 FuelCntlSysFltPrsnt 487;
BA_REL_ "GenSigTimeoutTime" BU_SG_REL_ ICCM_HS SG_ 487 FuelCntlSysFltPrsnt 31;
BA_REL_ "GenSigSuprvResp" BU_SG_REL_ FSCM_ITBC_HS SG_ 487 FuelCntlSysFltPrsnt 1;
BA_REL_ "GenSigTimeoutMsg" BU_SG_REL_ FSCM_ITBC_HS SG_ 487 FuelCntlSysFltPrsnt 487;
BA_REL_ "GenSigTimeoutTime" BU_SG_REL_ FSCM_ITBC_HS SG_ 487 FuelCntlSysFltPrsnt 31;
BA_REL_ "GenSigSuprvResp" BU_SG_REL_ FSCM_HS SG_ 487 FuelCntlSysFltPrsnt 1;
BA_REL_ "GenSigTimeoutMsg" BU_SG_REL_ FSCM_HS SG_ 487 FuelCntlSysFltPrsnt 487;
BA_REL_ "GenSigTimeoutTime" BU_SG_REL_ FSCM_HS SG_ 487 FuelCntlSysFltPrsnt 31;
BA_REL_ "GenSigSuprvResp" BU_SG_REL_ ICCM_OBD_HS SG_ 487 HiPresFuelPmpDelDur 1;
BA_REL_ "GenSigTimeoutMsg" BU_SG_REL_ ICCM_OBD_HS SG_ 487 HiPresFuelPmpDelDur 487;
BA_REL_ "GenSigTimeoutTime" BU_SG_REL_ ICCM_OBD_HS SG_ 487 HiPresFuelPmpDelDur 31;
BA_REL_ "GenSigSuprvResp" BU_SG_REL_ ICCM_HS SG_ 487 HiPresFuelPmpDelDur 1;
BA_REL_ "GenSigTimeoutMsg" BU_SG_REL_ ICCM_HS SG_ 487 HiPresFuelPmpDelDur 487;
BA_REL_ "GenSigTimeoutTime" BU_SG_REL_ ICCM_HS SG_ 487 HiPresFuelPmpDelDur 31;
BA_REL_ "GenSigSuprvResp" BU_SG_REL_ FSCM_ITBC_HS SG_ 487 HiPresFuelPmpDelDur 1;
BA_REL_ "GenSigTimeoutMsg" BU_SG_REL_ FSCM_ITBC_HS SG_ 487 HiPresFuelPmpDelDur 487;
BA_REL_ "GenSigTimeoutTime" BU_SG_REL_ FSCM_ITBC_HS SG_ 487 HiPresFuelPmpDelDur 31;
BA_REL_ "GenSigSuprvResp" BU_SG_REL_ FSCM_HS SG_ 487 HiPresFuelPmpDelDur 1;
BA_REL_ "GenSigTimeoutMsg" BU_SG_REL_ FSCM_HS SG_ 487 HiPresFuelPmpDelDur 487;
BA_REL_ "GenSigTimeoutTime" BU_SG_REL_ FSCM_HS SG_ 487 HiPresFuelPmpDelDur 31;
BA_REL_ "GenSigSuprvResp" BU_SG_REL_ ICCM_OBD_HS SG_ 487 HiPresFuelPmpCntMd 1;
BA_REL_ "GenSigTimeoutMsg" BU_SG_REL_ ICCM_OBD_HS SG_ 487 HiPresFuelPmpCntMd 487;
BA_REL_ "GenSigTimeoutTime" BU_SG_REL_ ICCM_OBD_HS SG_ 487 HiPresFuelPmpCntMd 31;
BA_REL_ "GenSigSuprvResp" BU_SG_REL_ ICCM_HS SG_ 487 HiPresFuelPmpCntMd 1;
BA_REL_ "GenSigTimeoutMsg" BU_SG_REL_ ICCM_HS SG_ 487 HiPresFuelPmpCntMd 487;
BA_REL_ "GenSigTimeoutTime" BU_SG_REL_ ICCM_HS SG_ 487 HiPresFuelPmpCntMd 31;
BA_REL_ "GenSigSuprvResp" BU_SG_REL_ FSCM_ITBC_HS SG_ 487 HiPresFuelPmpCntMd 1;
BA_REL_ "GenSigTimeoutMsg" BU_SG_REL_ FSCM_ITBC_HS SG_ 487 HiPresFuelPmpCntMd 487;
BA_REL_ "GenSigTimeoutTime" BU_SG_REL_ FSCM_ITBC_HS SG_ 487 HiPresFuelPmpCntMd 31;
BA_REL_ "GenSigSuprvResp" BU_SG_REL_ FSCM_HS SG_ 487 HiPresFuelPmpCntMd 1;
BA_REL_ "GenSigTimeoutMsg" BU_SG_REL_ FSCM_HS SG_ 487 HiPresFuelPmpCntMd 487;
BA_REL_ "GenSigTimeoutTime" BU_SG_REL_ FSCM_HS SG_ 487 HiPresFuelPmpCntMd 31;
BA_REL_ "GenSigSuprvResp" BU_SG_REL_ VITM_OBD_HS SG_ 566 RdHVBatLwParMdReq 1;
BA_REL_ "GenSigTimeoutMsg" BU_SG_REL_ VITM_OBD_HS SG_ 566 RdHVBatLwParMdReq 566;
BA_REL_ "GenSigTimeoutTime" BU_SG_REL_ VITM_OBD_HS SG_ 566 RdHVBatLwParMdReq 250;
BA_REL_ "GenSigSuprvResp" BU_SG_REL_ VITM_OBD_HS SG_ 566 RdHVBtClOVFFTstRq 1;
BA_REL_ "GenSigTimeoutMsg" BU_SG_REL_ VITM_OBD_HS SG_ 566 RdHVBtClOVFFTstRq 566;
BA_REL_ "GenSigTimeoutTime" BU_SG_REL_ VITM_OBD_HS SG_ 566 RdHVBtClOVFFTstRq 250;
BA_REL_ "GenSigSuprvResp" BU_SG_REL_ VITM_OBD_HS SG_ 566 RdHVBtClOVFFTstIdx 1;
BA_REL_ "GenSigTimeoutMsg" BU_SG_REL_ VITM_OBD_HS SG_ 566 RdHVBtClOVFFTstIdx 566;
BA_REL_ "GenSigTimeoutTime" BU_SG_REL_ VITM_OBD_HS SG_ 566 RdHVBtClOVFFTstIdx 250;
BA_REL_ "GenSigSuprvResp" BU_SG_REL_ VICM2_HS SG_ 566 VICMHVEnMgCmEnTrS 1;
BA_REL_ "GenSigTimeoutMsg" BU_SG_REL_ VICM2_HS SG_ 566 VICMHVEnMgCmEnTrS 566;
BA_REL_ "GenSigTimeoutTime" BU_SG_REL_ VICM2_HS SG_ 566 VICMHVEnMgCmEnTrS 250;
BA_REL_ "GenSigSuprvResp" BU_SG_REL_ TCM_HS SG_ 421 HybSnsBrkPdlPosPVal 1;
BA_REL_ "GenSigTimeoutMsg" BU_SG_REL_ TCM_HS SG_ 421 HybSnsBrkPdlPosPVal 421;
BA_REL_ "GenSigTimeoutTime" BU_SG_REL_ TCM_HS SG_ 421 HybSnsBrkPdlPosPVal 250;
BA_REL_ "GenSigSuprvResp" BU_SG_REL_ PCM_HS SG_ 421 HybSnsBrkPdlPosPVal 1;
BA_REL_ "GenSigTimeoutMsg" BU_SG_REL_ PCM_HS SG_ 421 HybSnsBrkPdlPosPVal 421;
BA_REL_ "GenSigTimeoutTime" BU_SG_REL_ PCM_HS SG_ 421 HybSnsBrkPdlPosPVal 250;
BA_REL_ "GenSigSuprvResp" BU_SG_REL_ ECM_HS SG_ 421 HybSnsBrkPdlPosPVal 1;
BA_REL_ "GenSigTimeoutMsg" BU_SG_REL_ ECM_HS SG_ 421 HybSnsBrkPdlPosPVal 421;
BA_REL_ "GenSigTimeoutTime" BU_SG_REL_ ECM_HS SG_ 421 HybSnsBrkPdlPosPVal 250;
BA_REL_ "GenSigSuprvResp" BU_SG_REL_ TCM_HS SG_ 421 HybSnsBrkPdlPosARC 1;
BA_REL_ "GenSigTimeoutMsg" BU_SG_REL_ TCM_HS SG_ 421 HybSnsBrkPdlPosARC 421;
BA_REL_ "GenSigTimeoutTime" BU_SG_REL_ TCM_HS SG_ 421 HybSnsBrkPdlPosARC 250;
BA_REL_ "GenSigSuprvResp" BU_SG_REL_ PCM_HS SG_ 421 HybSnsBrkPdlPosARC 1;
BA_REL_ "GenSigTimeoutMsg" BU_SG_REL_ PCM_HS SG_ 421 HybSnsBrkPdlPosARC 421;
BA_REL_ "GenSigTimeoutTime" BU_SG_REL_ PCM_HS SG_ 421 HybSnsBrkPdlPosARC 250;
BA_REL_ "GenSigSuprvResp" BU_SG_REL_ ECM_HS SG_ 421 HybSnsBrkPdlPosARC 1;
BA_REL_ "GenSigTimeoutMsg" BU_SG_REL_ ECM_HS SG_ 421 HybSnsBrkPdlPosARC 421;
BA_REL_ "GenSigTimeoutTime" BU_SG_REL_ ECM_HS SG_ 421 HybSnsBrkPdlPosARC 250;
BA_REL_ "GenSigSuprvResp" BU_SG_REL_ TCM_HS SG_ 421 HybSnsBrkPdlPos 1;
BA_REL_ "GenSigTimeoutMsg" BU_SG_REL_ TCM_HS SG_ 421 HybSnsBrkPdlPos 421;
BA_REL_ "GenSigTimeoutTime" BU_SG_REL_ TCM_HS SG_ 421 HybSnsBrkPdlPos 250;
BA_REL_ "GenSigSuprvResp" BU_SG_REL_ PCM_HS SG_ 421 HybSnsBrkPdlPos 1;
BA_REL_ "GenSigTimeoutMsg" BU_SG_REL_ PCM_HS SG_ 421 HybSnsBrkPdlPos 421;
BA_REL_ "GenSigTimeoutTime" BU_SG_REL_ PCM_HS SG_ 421 HybSnsBrkPdlPos 250;
BA_REL_ "GenSigSuprvResp" BU_SG_REL_ ECM_HS SG_ 421 HybSnsBrkPdlPos 1;
BA_REL_ "GenSigTimeoutMsg" BU_SG_REL_ ECM_HS SG_ 421 HybSnsBrkPdlPos 421;
BA_REL_ "GenSigTimeoutTime" BU_SG_REL_ ECM_HS SG_ 421 HybSnsBrkPdlPos 250;
BA_REL_ "GenSigSuprvResp" BU_SG_REL_ LVMPC_HS SG_ 456 PTESR_EngSpdRqVal 1;
BA_REL_ "GenSigTimeoutMsg" BU_SG_REL_ LVMPC_HS SG_ 456 PTESR_EngSpdRqVal 456;
BA_REL_ "GenSigTimeoutTime" BU_SG_REL_ LVMPC_HS SG_ 456 PTESR_EngSpdRqVal 250;
BA_REL_ "GenSigSuprvResp" BU_SG_REL_ LVMPC_HS SG_ 456 PTESR_EngSpdCntlRs 1;
BA_REL_ "GenSigTimeoutMsg" BU_SG_REL_ LVMPC_HS SG_ 456 PTESR_EngSpdCntlRs 456;
BA_REL_ "GenSigTimeoutTime" BU_SG_REL_ LVMPC_HS SG_ 456 PTESR_EngSpdCntlRs 250;
BA_REL_ "GenSigSuprvResp" BU_SG_REL_ LVMPC_HS SG_ 456 PTESR_EngSpdIntTyp 1;
BA_REL_ "GenSigTimeoutMsg" BU_SG_REL_ LVMPC_HS SG_ 456 PTESR_EngSpdIntTyp 456;
BA_REL_ "GenSigTimeoutTime" BU_SG_REL_ LVMPC_HS SG_ 456 PTESR_EngSpdIntTyp 250;
BA_REL_ "GenSigSuprvResp" BU_SG_REL_ ICCM_OBD_HS SG_ 456 PTTR_TrqReqVal 1;
BA_REL_ "GenSigTimeoutMsg" BU_SG_REL_ ICCM_OBD_HS SG_ 456 PTTR_TrqReqVal 456;
BA_REL_ "GenSigTimeoutTime" BU_SG_REL_ ICCM_OBD_HS SG_ 456 PTTR_TrqReqVal 250;
BA_REL_ "GenSigSuprvResp" BU_SG_REL_ ICCM_HS SG_ 456 PTTR_TrqReqVal 1;
BA_REL_ "GenSigTimeoutMsg" BU_SG_REL_ ICCM_HS SG_ 456 PTTR_TrqReqVal 456;
BA_REL_ "GenSigTimeoutTime" BU_SG_REL_ ICCM_HS SG_ 456 PTTR_TrqReqVal 250;
BA_REL_ "GenSigSuprvResp" BU_SG_REL_ ICCM_OBD_HS SG_ 456 PTTR_TrqRedRlzSugg 1;
BA_REL_ "GenSigTimeoutMsg" BU_SG_REL_ ICCM_OBD_HS SG_ 456 PTTR_TrqRedRlzSugg 456;
BA_REL_ "GenSigTimeoutTime" BU_SG_REL_ ICCM_OBD_HS SG_ 456 PTTR_TrqRedRlzSugg 250;
BA_REL_ "GenSigSuprvResp" BU_SG_REL_ ICCM_HS SG_ 456 PTTR_TrqRedRlzSugg 1;
BA_REL_ "GenSigTimeoutMsg" BU_SG_REL_ ICCM_HS SG_ 456 PTTR_TrqRedRlzSugg 456;
BA_REL_ "GenSigTimeoutTime" BU_SG_REL_ ICCM_HS SG_ 456 PTTR_TrqRedRlzSugg 250;
BA_REL_ "GenSigSuprvResp" BU_SG_REL_ ICCM_OBD_HS SG_ 456 PTTR_TrqInvTyp 1;
BA_REL_ "GenSigTimeoutMsg" BU_SG_REL_ ICCM_OBD_HS SG_ 456 PTTR_TrqInvTyp 456;
BA_REL_ "GenSigTimeoutTime" BU_SG_REL_ ICCM_OBD_HS SG_ 456 PTTR_TrqInvTyp 250;
BA_REL_ "GenSigSuprvResp" BU_SG_REL_ ICCM_HS SG_ 456 PTTR_TrqInvTyp 1;
BA_REL_ "GenSigTimeoutMsg" BU_SG_REL_ ICCM_HS SG_ 456 PTTR_TrqInvTyp 456;
BA_REL_ "GenSigTimeoutTime" BU_SG_REL_ ICCM_HS SG_ 456 PTTR_TrqInvTyp 250;
BA_REL_ "GenSigSuprvResp" BU_SG_REL_ BCM_HS SG_ 882 AdvFrntLghtSysHiBmIO 1;
BA_REL_ "GenSigTimeoutMsg" BU_SG_REL_ BCM_HS SG_ 882 AdvFrntLghtSysHiBmIO 882;
BA_REL_ "GenSigTimeoutTime" BU_SG_REL_ BCM_HS SG_ 882 AdvFrntLghtSysHiBmIO 250;
BA_REL_ "GenSigSuprvResp" BU_SG_REL_ FCM_HS SG_ 882 AdvFrntLghtSysHiBmIO 1;
BA_REL_ "GenSigTimeoutMsg" BU_SG_REL_ FCM_HS SG_ 882 AdvFrntLghtSysHiBmIO 882;
BA_REL_ "GenSigTimeoutTime" BU_SG_REL_ FCM_HS SG_ 882 AdvFrntLghtSysHiBmIO 250;
BA_REL_ "GenSigSuprvResp" BU_SG_REL_ ICCM_OBD_HS SG_ 199 TORSTimestamp 1;
BA_REL_ "GenSigTimeoutMsg" BU_SG_REL_ ICCM_OBD_HS SG_ 199 TORSTimestamp 199;
BA_REL_ "GenSigTimeoutTime" BU_SG_REL_ ICCM_OBD_HS SG_ 199 TORSTimestamp 250;
BA_REL_ "GenSigSuprvResp" BU_SG_REL_ ICCM_HS SG_ 199 TORSTimestamp 1;
BA_REL_ "GenSigTimeoutMsg" BU_SG_REL_ ICCM_HS SG_ 199 TORSTimestamp 199;
BA_REL_ "GenSigTimeoutTime" BU_SG_REL_ ICCM_HS SG_ 199 TORSTimestamp 250;
BA_REL_ "GenSigSuprvResp" BU_SG_REL_ TCCM_HS SG_ 199 TORSTimestamp 1;
BA_REL_ "GenSigTimeoutMsg" BU_SG_REL_ TCCM_HS SG_ 199 TORSTimestamp 199;
BA_REL_ "GenSigTimeoutTime" BU_SG_REL_ TCCM_HS SG_ 199 TORSTimestamp 250;
BA_REL_ "GenSigSuprvResp" BU_SG_REL_ ICCM_OBD_HS SG_ 199 TORSPulsCntr 1;
BA_REL_ "GenSigTimeoutMsg" BU_SG_REL_ ICCM_OBD_HS SG_ 199 TORSPulsCntr 199;
BA_REL_ "GenSigTimeoutTime" BU_SG_REL_ ICCM_OBD_HS SG_ 199 TORSPulsCntr 250;
BA_REL_ "GenSigSuprvResp" BU_SG_REL_ ICCM_HS SG_ 199 TORSPulsCntr 1;
BA_REL_ "GenSigTimeoutMsg" BU_SG_REL_ ICCM_HS SG_ 199 TORSPulsCntr 199;
BA_REL_ "GenSigTimeoutTime" BU_SG_REL_ ICCM_HS SG_ 199 TORSPulsCntr 250;
BA_REL_ "GenSigSuprvResp" BU_SG_REL_ TCCM_HS SG_ 199 TORSPulsCntr 1;
BA_REL_ "GenSigTimeoutMsg" BU_SG_REL_ TCCM_HS SG_ 199 TORSPulsCntr 199;
BA_REL_ "GenSigTimeoutTime" BU_SG_REL_ TCCM_HS SG_ 199 TORSPulsCntr 250;
BA_REL_ "GenSigSuprvResp" BU_SG_REL_ ICCM_OBD_HS SG_ 199 TORSValidity 1;
BA_REL_ "GenSigTimeoutMsg" BU_SG_REL_ ICCM_OBD_HS SG_ 199 TORSValidity 199;
BA_REL_ "GenSigTimeoutTime" BU_SG_REL_ ICCM_OBD_HS SG_ 199 TORSValidity 250;
BA_REL_ "GenSigSuprvResp" BU_SG_REL_ ICCM_HS SG_ 199 TORSValidity 1;
BA_REL_ "GenSigTimeoutMsg" BU_SG_REL_ ICCM_HS SG_ 199 TORSValidity 199;
BA_REL_ "GenSigTimeoutTime" BU_SG_REL_ ICCM_HS SG_ 199 TORSValidity 250;
BA_REL_ "GenSigSuprvResp" BU_SG_REL_ TCCM_HS SG_ 199 TORSValidity 1;
BA_REL_ "GenSigTimeoutMsg" BU_SG_REL_ TCCM_HS SG_ 199 TORSValidity 199;
BA_REL_ "GenSigTimeoutTime" BU_SG_REL_ TCCM_HS SG_ 199 TORSValidity 250;
BA_REL_ "GenSigSuprvResp" BU_SG_REL_ ICCM_OBD_HS SG_ 199 TORSRstOcrd 1;
BA_REL_ "GenSigTimeoutMsg" BU_SG_REL_ ICCM_OBD_HS SG_ 199 TORSRstOcrd 199;
BA_REL_ "GenSigTimeoutTime" BU_SG_REL_ ICCM_OBD_HS SG_ 199 TORSRstOcrd 250;
BA_REL_ "GenSigSuprvResp" BU_SG_REL_ ICCM_HS SG_ 199 TORSRstOcrd 1;
BA_REL_ "GenSigTimeoutMsg" BU_SG_REL_ ICCM_HS SG_ 199 TORSRstOcrd 199;
BA_REL_ "GenSigTimeoutTime" BU_SG_REL_ ICCM_HS SG_ 199 TORSRstOcrd 250;
BA_REL_ "GenSigSuprvResp" BU_SG_REL_ TCCM_HS SG_ 199 TORSRstOcrd 1;
BA_REL_ "GenSigTimeoutMsg" BU_SG_REL_ TCCM_HS SG_ 199 TORSRstOcrd 199;
BA_REL_ "GenSigTimeoutTime" BU_SG_REL_ TCCM_HS SG_ 199 TORSRstOcrd 250;
BA_REL_ "GenSigSuprvResp" BU_SG_REL_ ICCM_OBD_HS SG_ 199 TORSLstTransType 1;
BA_REL_ "GenSigTimeoutMsg" BU_SG_REL_ ICCM_OBD_HS SG_ 199 TORSLstTransType 199;
BA_REL_ "GenSigTimeoutTime" BU_SG_REL_ ICCM_OBD_HS SG_ 199 TORSLstTransType 250;
BA_REL_ "GenSigSuprvResp" BU_SG_REL_ ICCM_HS SG_ 199 TORSLstTransType 1;
BA_REL_ "GenSigTimeoutMsg" BU_SG_REL_ ICCM_HS SG_ 199 TORSLstTransType 199;
BA_REL_ "GenSigTimeoutTime" BU_SG_REL_ ICCM_HS SG_ 199 TORSLstTransType 250;
BA_REL_ "GenSigSuprvResp" BU_SG_REL_ TCCM_HS SG_ 199 TORSLstTransType 1;
BA_REL_ "GenSigTimeoutMsg" BU_SG_REL_ TCCM_HS SG_ 199 TORSLstTransType 199;
BA_REL_ "GenSigTimeoutTime" BU_SG_REL_ TCCM_HS SG_ 199 TORSLstTransType 250;
BA_REL_ "GenSigSuprvResp" BU_SG_REL_ ICCM_OBD_HS SG_ 199 TORSRotDir 1;
BA_REL_ "GenSigTimeoutMsg" BU_SG_REL_ ICCM_OBD_HS SG_ 199 TORSRotDir 199;
BA_REL_ "GenSigTimeoutTime" BU_SG_REL_ ICCM_OBD_HS SG_ 199 TORSRotDir 250;
BA_REL_ "GenSigSuprvResp" BU_SG_REL_ ICCM_HS SG_ 199 TORSRotDir 1;
BA_REL_ "GenSigTimeoutMsg" BU_SG_REL_ ICCM_HS SG_ 199 TORSRotDir 199;
BA_REL_ "GenSigTimeoutTime" BU_SG_REL_ ICCM_HS SG_ 199 TORSRotDir 250;
BA_REL_ "GenSigSuprvResp" BU_SG_REL_ TCCM_HS SG_ 199 TORSRotDir 1;
BA_REL_ "GenSigTimeoutMsg" BU_SG_REL_ TCCM_HS SG_ 199 TORSRotDir 199;
BA_REL_ "GenSigTimeoutTime" BU_SG_REL_ TCCM_HS SG_ 199 TORSRotDir 250;
BA_REL_ "GenSigSuprvResp" BU_SG_REL_ TCCM_HS SG_ 398 EngActStdyStTorq 1;
BA_REL_ "GenSigTimeoutMsg" BU_SG_REL_ TCCM_HS SG_ 398 EngActStdyStTorq 398;
BA_REL_ "GenSigTimeoutTime" BU_SG_REL_ TCCM_HS SG_ 398 EngActStdyStTorq 250;
BA_REL_ "GenSigSuprvResp" BU_SG_REL_ TCM_HS SG_ 398 EngActStdyStTorq 1;
BA_REL_ "GenSigTimeoutMsg" BU_SG_REL_ TCM_HS SG_ 398 EngActStdyStTorq 398;
BA_REL_ "GenSigTimeoutTime" BU_SG_REL_ TCM_HS SG_ 398 EngActStdyStTorq 250;
BA_REL_ "GenSigSuprvResp" BU_SG_REL_ TCM_HS SG_ 398 AccKdwnAtv 1;
BA_REL_ "GenSigTimeoutMsg" BU_SG_REL_ TCM_HS SG_ 398 AccKdwnAtv 398;
BA_REL_ "GenSigTimeoutTime" BU_SG_REL_ TCM_HS SG_ 398 AccKdwnAtv 250;
BA_REL_ "GenSigSuprvResp" BU_SG_REL_ TCCM_HS SG_ 398 AccKdwnAtv 1;
BA_REL_ "GenSigTimeoutMsg" BU_SG_REL_ TCCM_HS SG_ 398 AccKdwnAtv 398;
BA_REL_ "GenSigTimeoutTime" BU_SG_REL_ TCCM_HS SG_ 398 AccKdwnAtv 250;
BA_REL_ "GenSigSuprvResp" BU_SG_REL_ TCM_HS SG_ 398 TrnsEngSpdReqFld 1;
BA_REL_ "GenSigTimeoutMsg" BU_SG_REL_ TCM_HS SG_ 398 TrnsEngSpdReqFld 398;
BA_REL_ "GenSigTimeoutTime" BU_SG_REL_ TCM_HS SG_ 398 TrnsEngSpdReqFld 250;
BA_REL_ "GenSigSuprvResp" BU_SG_REL_ TCCM_HS SG_ 398 TrnsEngSpdReqFld 1;
BA_REL_ "GenSigTimeoutMsg" BU_SG_REL_ TCCM_HS SG_ 398 TrnsEngSpdReqFld 398;
BA_REL_ "GenSigTimeoutTime" BU_SG_REL_ TCCM_HS SG_ 398 TrnsEngSpdReqFld 250;
BA_REL_ "GenSigSuprvResp" BU_SG_REL_ VICM_HS SG_ 390 RdHVInvRatVlt 1;
BA_REL_ "GenSigTimeoutMsg" BU_SG_REL_ VICM_HS SG_ 390 RdHVInvRatVlt 390;
BA_REL_ "GenSigTimeoutTime" BU_SG_REL_ VICM_HS SG_ 390 RdHVInvRatVlt 250;
BA_REL_ "GenSigSuprvResp" BU_SG_REL_ PCM_HS SG_ 390 EngActDmpgDsblReq 1;
BA_REL_ "GenSigTimeoutMsg" BU_SG_REL_ PCM_HS SG_ 390 EngActDmpgDsblReq 390;
BA_REL_ "GenSigTimeoutTime" BU_SG_REL_ PCM_HS SG_ 390 EngActDmpgDsblReq 250;
BA_REL_ "GenSigSuprvResp" BU_SG_REL_ ECM_HS SG_ 390 EngActDmpgDsblReq 1;
BA_REL_ "GenSigTimeoutMsg" BU_SG_REL_ ECM_HS SG_ 390 EngActDmpgDsblReq 390;
BA_REL_ "GenSigTimeoutTime" BU_SG_REL_ ECM_HS SG_ 390 EngActDmpgDsblReq 250;
BA_REL_ "GenSigSuprvResp" BU_SG_REL_ VICM2_HS SG_ 390 HESSI_EngStrtTyp 1;
BA_REL_ "GenSigTimeoutMsg" BU_SG_REL_ VICM2_HS SG_ 390 HESSI_EngStrtTyp 390;
BA_REL_ "GenSigTimeoutTime" BU_SG_REL_ VICM2_HS SG_ 390 HESSI_EngStrtTyp 250;
BA_REL_ "GenSigSuprvResp" BU_SG_REL_ VICM_HS SG_ 390 HESSI_EngStrtTyp 1;
BA_REL_ "GenSigTimeoutMsg" BU_SG_REL_ VICM_HS SG_ 390 HESSI_EngStrtTyp 390;
BA_REL_ "GenSigTimeoutTime" BU_SG_REL_ VICM_HS SG_ 390 HESSI_EngStrtTyp 250;
BA_REL_ "GenSigSuprvResp" BU_SG_REL_ VICM2_HS SG_ 390 HESSI_EngStrtStpMd 1;
BA_REL_ "GenSigTimeoutMsg" BU_SG_REL_ VICM2_HS SG_ 390 HESSI_EngStrtStpMd 390;
BA_REL_ "GenSigTimeoutTime" BU_SG_REL_ VICM2_HS SG_ 390 HESSI_EngStrtStpMd 250;
BA_REL_ "GenSigSuprvResp" BU_SG_REL_ VICM_HS SG_ 390 HESSI_EngStrtStpMd 1;
BA_REL_ "GenSigTimeoutMsg" BU_SG_REL_ VICM_HS SG_ 390 HESSI_EngStrtStpMd 390;
BA_REL_ "GenSigTimeoutTime" BU_SG_REL_ VICM_HS SG_ 390 HESSI_EngStrtStpMd 250;
BA_REL_ "GenSigSuprvResp" BU_SG_REL_ VICM_HS SG_ 390 RdPTHVCntrReq 1;
BA_REL_ "GenSigTimeoutMsg" BU_SG_REL_ VICM_HS SG_ 390 RdPTHVCntrReq 390;
BA_REL_ "GenSigTimeoutTime" BU_SG_REL_ VICM_HS SG_ 390 RdPTHVCntrReq 250;
BA_REL_ "GenSigSuprvRespSubValue" BU_SG_REL_ BCM_HS SG_ 817 RrDrvlnSysVehTpSpdLmVal 255;
BA_REL_ "GenSigSuprvResp" BU_SG_REL_ BCM_HS SG_ 817 RrDrvlnSysVehTpSpdLmVal 2;
BA_REL_ "GenSigTimeoutMsg" BU_SG_REL_ BCM_HS SG_ 817 RrDrvlnSysVehTpSpdLmVal 817;
BA_REL_ "GenSigTimeoutTime" BU_SG_REL_ BCM_HS SG_ 817 RrDrvlnSysVehTpSpdLmVal 500;
BA_REL_ "GenSigSuprvResp" BU_SG_REL_ BCM_HS SG_ 817 RrAxlMalfIO 1;
BA_REL_ "GenSigTimeoutMsg" BU_SG_REL_ BCM_HS SG_ 817 RrAxlMalfIO 817;
BA_REL_ "GenSigTimeoutTime" BU_SG_REL_ BCM_HS SG_ 817 RrAxlMalfIO 250;
BA_REL_ "GenSigSuprvResp" BU_SG_REL_ EOCM_F_HS SG_ 460 SecAxlStat 1;
BA_REL_ "GenSigTimeoutMsg" BU_SG_REL_ EOCM_F_HS SG_ 460 SecAxlStat 460;
BA_REL_ "GenSigTimeoutTime" BU_SG_REL_ EOCM_F_HS SG_ 460 SecAxlStat 120;
BA_REL_ "GenSigSuprvResp" BU_SG_REL_ TCCM_HS SG_ 462 SATRCplReqVal 1;
BA_REL_ "GenSigTimeoutMsg" BU_SG_REL_ TCCM_HS SG_ 462 SATRCplReqVal 462;
BA_REL_ "GenSigTimeoutTime" BU_SG_REL_ TCCM_HS SG_ 462 SATRCplReqVal 250;
BA_REL_ "GenSigSuprvResp" BU_SG_REL_ TCCM_HS SG_ 462 SATRCplReqAtv 1;
BA_REL_ "GenSigTimeoutMsg" BU_SG_REL_ TCCM_HS SG_ 462 SATRCplReqAtv 462;
BA_REL_ "GenSigTimeoutTime" BU_SG_REL_ TCCM_HS SG_ 462 SATRCplReqAtv 250;
BA_REL_ "GenSigSuprvResp" BU_SG_REL_ BCM_HS SG_ 463 FourWhlDrvIndReq 1;
BA_REL_ "GenSigTimeoutMsg" BU_SG_REL_ BCM_HS SG_ 463 FourWhlDrvIndReq 463;
BA_REL_ "GenSigTimeoutTime" BU_SG_REL_ BCM_HS SG_ 463 FourWhlDrvIndReq 250;
BA_REL_ "GenSigSuprvResp" BU_SG_REL_ BCM_HS SG_ 463 TrnsfrCsRngShfSpdLmt 1;
BA_REL_ "GenSigTimeoutMsg" BU_SG_REL_ BCM_HS SG_ 463 TrnsfrCsRngShfSpdLmt 463;
BA_REL_ "GenSigTimeoutTime" BU_SG_REL_ BCM_HS SG_ 463 TrnsfrCsRngShfSpdLmt 250;
BA_REL_ "GenSigSuprvResp" BU_SG_REL_ BCM_HS SG_ 463 SecAxlNonEmMalfIO 1;
BA_REL_ "GenSigTimeoutMsg" BU_SG_REL_ BCM_HS SG_ 463 SecAxlNonEmMalfIO 463;
BA_REL_ "GenSigTimeoutTime" BU_SG_REL_ BCM_HS SG_ 463 SecAxlNonEmMalfIO 250;
BA_REL_ "GenSigSuprvResp" BU_SG_REL_ VICM_HS SG_ 463 SecAxlOperMod 1;
BA_REL_ "GenSigTimeoutMsg" BU_SG_REL_ VICM_HS SG_ 463 SecAxlOperMod 463;
BA_REL_ "GenSigTimeoutTime" BU_SG_REL_ VICM_HS SG_ 463 SecAxlOperMod 250;
BA_REL_ "GenSigSuprvResp" BU_SG_REL_ BCM_HS SG_ 463 SecAxlOperMod 1;
BA_REL_ "GenSigTimeoutMsg" BU_SG_REL_ BCM_HS SG_ 463 SecAxlOperMod 463;
BA_REL_ "GenSigTimeoutTime" BU_SG_REL_ BCM_HS SG_ 463 SecAxlOperMod 250;
BA_REL_ "GenSigSuprvResp" BU_SG_REL_ EOCM_F_HS SG_ 463 SecAxlOperMod 1;
BA_REL_ "GenSigTimeoutMsg" BU_SG_REL_ EOCM_F_HS SG_ 463 SecAxlOperMod 463;
BA_REL_ "GenSigTimeoutTime" BU_SG_REL_ EOCM_F_HS SG_ 463 SecAxlOperMod 250;
BA_REL_ "GenSigSuprvResp" BU_SG_REL_ PCM_HS SG_ 719 RrVrtlBmpAxlTrqCmdRC 1;
BA_REL_ "GenSigTimeoutTime" BU_SG_REL_ PCM_HS SG_ 719 RrVrtlBmpAxlTrqCmdRC 250;
BA_REL_ "GenSigSuprvResp" BU_SG_REL_ ECM_HS SG_ 719 RrVrtlBmpAxlTrqCmdRC 1;
BA_REL_ "GenSigTimeoutTime" BU_SG_REL_ ECM_HS SG_ 719 RrVrtlBmpAxlTrqCmdRC 250;
BA_REL_ "GenSigSuprvResp" BU_SG_REL_ PCM_HS SG_ 719 RrVrtlBmpAxlTrqCmdProtVal 1;
BA_REL_ "GenSigTimeoutTime" BU_SG_REL_ PCM_HS SG_ 719 RrVrtlBmpAxlTrqCmdProtVal 250;
BA_REL_ "GenSigSuprvResp" BU_SG_REL_ ECM_HS SG_ 719 RrVrtlBmpAxlTrqCmdProtVal 1;
BA_REL_ "GenSigTimeoutTime" BU_SG_REL_ ECM_HS SG_ 719 RrVrtlBmpAxlTrqCmdProtVal 250;
BA_REL_ "GenSigSuprvResp" BU_SG_REL_ PCM_HS SG_ 719 RVBATC_AxlTrqRqstAct 1;
BA_REL_ "GenSigTimeoutTime" BU_SG_REL_ PCM_HS SG_ 719 RVBATC_AxlTrqRqstAct 250;
BA_REL_ "GenSigSuprvResp" BU_SG_REL_ ECM_HS SG_ 719 RVBATC_AxlTrqRqstAct 1;
BA_REL_ "GenSigTimeoutTime" BU_SG_REL_ ECM_HS SG_ 719 RVBATC_AxlTrqRqstAct 250;
BA_REL_ "GenSigSuprvResp" BU_SG_REL_ PCM_HS SG_ 719 RVBATC_AxlTrqRqst 1;
BA_REL_ "GenSigTimeoutTime" BU_SG_REL_ PCM_HS SG_ 719 RVBATC_AxlTrqRqst 250;
BA_REL_ "GenSigSuprvResp" BU_SG_REL_ ECM_HS SG_ 719 RVBATC_AxlTrqRqst 1;
BA_REL_ "GenSigTimeoutTime" BU_SG_REL_ ECM_HS SG_ 719 RVBATC_AxlTrqRqst 250;
BA_REL_ "GenSigSuprvResp" BU_SG_REL_ BCM_HS SG_ 853 SrvPedtrnProtSysIO 1;
BA_REL_ "GenSigTimeoutMsg" BU_SG_REL_ BCM_HS SG_ 853 SrvPedtrnProtSysIO 853;
BA_REL_ "GenSigTimeoutTime" BU_SG_REL_ BCM_HS SG_ 853 SrvPedtrnProtSysIO 2500;
BA_REL_ "GenSigSuprvResp" BU_SG_REL_ BCM_HS SG_ 869 FCACustStngAvlbl 1;
BA_REL_ "GenSigTimeoutTime" BU_SG_REL_ BCM_HS SG_ 869 FCACustStngAvlbl 250;
BA_REL_ "GenSigSuprvResp" BU_SG_REL_ BCM_HS SG_ 869 FwdClnAlrtCustCrntSetngVal 1;
BA_REL_ "GenSigTimeoutTime" BU_SG_REL_ BCM_HS SG_ 869 FwdClnAlrtCustCrntSetngVal 250;
BA_REL_ "GenSigSuprvResp" BU_SG_REL_ BCM_HS SG_ 869 GNCustSetngAvlbl 1;
BA_REL_ "GenSigTimeoutTime" BU_SG_REL_ BCM_HS SG_ 869 GNCustSetngAvlbl 250;
BA_REL_ "GenSigSuprvResp" BU_SG_REL_ BCM_HS SG_ 869 CPSUnblIO 1;
BA_REL_ "GenSigTimeoutTime" BU_SG_REL_ BCM_HS SG_ 869 CPSUnblIO 250;
BA_REL_ "GenSigSuprvResp" BU_SG_REL_ BCM_HS SG_ 869 ColPrSysStngAvl 1;
BA_REL_ "GenSigTimeoutTime" BU_SG_REL_ BCM_HS SG_ 869 ColPrSysStngAvl 250;
BA_REL_ "GenSigSuprvResp" BU_SG_REL_ BCM_HS SG_ 869 CPSOffIO 1;
BA_REL_ "GenSigTimeoutTime" BU_SG_REL_ BCM_HS SG_ 869 CPSOffIO 250;
BA_REL_ "GenSigSuprvResp" BU_SG_REL_ BCM_HS SG_ 869 CPSFldIO 1;
BA_REL_ "GenSigTimeoutTime" BU_SG_REL_ BCM_HS SG_ 869 CPSFldIO 250;
BA_REL_ "GenSigSuprvResp" BU_SG_REL_ BCM_HS SG_ 869 ColPrSysCrntStng 1;
BA_REL_ "GenSigTimeoutTime" BU_SG_REL_ BCM_HS SG_ 869 ColPrSysCrntStng 250;
BA_REL_ "GenSigSuprvResp" BU_SG_REL_ BCM_HS SG_ 869 CPSAlrtOnlIO 1;
BA_REL_ "GenSigTimeoutTime" BU_SG_REL_ BCM_HS SG_ 869 CPSAlrtOnlIO 250;
BA_REL_ "GenSigSuprvResp" BU_SG_REL_ BCM_HS SG_ 869 GNCustCrntStngVal 1;
BA_REL_ "GenSigTimeoutTime" BU_SG_REL_ BCM_HS SG_ 869 GNCustCrntStngVal 250;
BA_REL_ "GenSigSuprvResp" BU_SG_REL_ PCM_HS SG_ 717 ColPrSysAxlTrqCmdProtVal 1;
BA_REL_ "GenSigTimeoutTime" BU_SG_REL_ PCM_HS SG_ 717 ColPrSysAxlTrqCmdProtVal 250;
BA_REL_ "GenSigSuprvResp" BU_SG_REL_ ECM_HS SG_ 717 ColPrSysAxlTrqCmdProtVal 1;
BA_REL_ "GenSigTimeoutTime" BU_SG_REL_ ECM_HS SG_ 717 ColPrSysAxlTrqCmdProtVal 250;
BA_REL_ "GenSigSuprvResp" BU_SG_REL_ PCM_HS SG_ 717 CPSATC_AxlTrqRqstAct 1;
BA_REL_ "GenSigTimeoutTime" BU_SG_REL_ PCM_HS SG_ 717 CPSATC_AxlTrqRqstAct 250;
BA_REL_ "GenSigSuprvResp" BU_SG_REL_ ECM_HS SG_ 717 CPSATC_AxlTrqRqstAct 1;
BA_REL_ "GenSigTimeoutTime" BU_SG_REL_ ECM_HS SG_ 717 CPSATC_AxlTrqRqstAct 250;
BA_REL_ "GenSigSuprvResp" BU_SG_REL_ PCM_HS SG_ 717 CPSATC_AxlTrqRqst 1;
BA_REL_ "GenSigTimeoutTime" BU_SG_REL_ PCM_HS SG_ 717 CPSATC_AxlTrqRqst 250;
BA_REL_ "GenSigSuprvResp" BU_SG_REL_ ECM_HS SG_ 717 CPSATC_AxlTrqRqst 1;
BA_REL_ "GenSigTimeoutTime" BU_SG_REL_ ECM_HS SG_ 717 CPSATC_AxlTrqRqst 250;
BA_REL_ "GenSigSuprvResp" BU_SG_REL_ PCM_HS SG_ 717 ColPrSysAxlTrqCmdRC 1;
BA_REL_ "GenSigTimeoutTime" BU_SG_REL_ PCM_HS SG_ 717 ColPrSysAxlTrqCmdRC 250;
BA_REL_ "GenSigSuprvResp" BU_SG_REL_ ECM_HS SG_ 717 ColPrSysAxlTrqCmdRC 1;
BA_REL_ "GenSigTimeoutTime" BU_SG_REL_ ECM_HS SG_ 717 ColPrSysAxlTrqCmdRC 250;
BA_REL_ "GenSigSuprvResp" BU_SG_REL_ VICM2_HS SG_ 568 a_12VSysVlt 1;
BA_REL_ "GenSigTimeoutMsg" BU_SG_REL_ VICM2_HS SG_ 568 a_12VSysVlt 568;
BA_REL_ "GenSigTimeoutTime" BU_SG_REL_ VICM2_HS SG_ 568 a_12VSysVlt 250;
BA_REL_ "GenSigSuprvResp" BU_SG_REL_ ICCM_OBD_HS SG_ 568 a_12VSysVlt 1;
BA_REL_ "GenSigTimeoutMsg" BU_SG_REL_ ICCM_OBD_HS SG_ 568 a_12VSysVlt 568;
BA_REL_ "GenSigTimeoutTime" BU_SG_REL_ ICCM_OBD_HS SG_ 568 a_12VSysVlt 250;
BA_REL_ "GenSigSuprvResp" BU_SG_REL_ ICCM_HS SG_ 568 a_12VSysVlt 1;
BA_REL_ "GenSigTimeoutMsg" BU_SG_REL_ ICCM_HS SG_ 568 a_12VSysVlt 568;
BA_REL_ "GenSigTimeoutTime" BU_SG_REL_ ICCM_HS SG_ 568 a_12VSysVlt 250;
BA_REL_ "GenSigSuprvResp" BU_SG_REL_ FSCM_HS SG_ 568 a_12VSysVlt 1;
BA_REL_ "GenSigTimeoutMsg" BU_SG_REL_ FSCM_HS SG_ 568 a_12VSysVlt 568;
BA_REL_ "GenSigTimeoutTime" BU_SG_REL_ FSCM_HS SG_ 568 a_12VSysVlt 250;
BA_REL_ "GenSigSuprvResp" BU_SG_REL_ BCM_HS SG_ 564 TrlrStabAstActIO 1;
BA_REL_ "GenSigTimeoutMsg" BU_SG_REL_ BCM_HS SG_ 564 TrlrStabAstActIO 564;
BA_REL_ "GenSigTimeoutTime" BU_SG_REL_ BCM_HS SG_ 564 TrlrStabAstActIO 250;
BA_REL_ "GenSigSuprvResp" BU_SG_REL_ LVMPC_HS SG_ 564 PerfTrcCrnExStngVal 1;
BA_REL_ "GenSigTimeoutMsg" BU_SG_REL_ LVMPC_HS SG_ 564 PerfTrcCrnExStngVal 564;
BA_REL_ "GenSigTimeoutTime" BU_SG_REL_ LVMPC_HS SG_ 564 PerfTrcCrnExStngVal 250;
BA_REL_ "GenSigSuprvResp" BU_SG_REL_ ACC_HS SG_ 313 PrkAstAdvSysAct 1;
BA_REL_ "GenSigTimeoutMsg" BU_SG_REL_ ACC_HS SG_ 313 PrkAstAdvSysAct 313;
BA_REL_ "GenSigTimeoutTime" BU_SG_REL_ ACC_HS SG_ 313 PrkAstAdvSysAct 250;
BA_REL_ "GenSigSuprvResp" BU_SG_REL_ EBCM_OBD_HS SG_ 313 SndPerfMdCsStRq 1;
BA_REL_ "GenSigTimeoutMsg" BU_SG_REL_ EBCM_OBD_HS SG_ 313 SndPerfMdCsStRq 313;
BA_REL_ "GenSigTimeoutTime" BU_SG_REL_ EBCM_OBD_HS SG_ 313 SndPerfMdCsStRq 250;
BA_REL_ "GenSigSuprvResp" BU_SG_REL_ EBCM_HS SG_ 313 SndPerfMdCsStRq 1;
BA_REL_ "GenSigTimeoutMsg" BU_SG_REL_ EBCM_HS SG_ 313 SndPerfMdCsStRq 313;
BA_REL_ "GenSigTimeoutTime" BU_SG_REL_ EBCM_HS SG_ 313 SndPerfMdCsStRq 250;
BA_REL_ "GenSigSuprvResp" BU_SG_REL_ ACC_HS SG_ 313 HptcStVbnStat 1;
BA_REL_ "GenSigTimeoutMsg" BU_SG_REL_ ACC_HS SG_ 313 HptcStVbnStat 313;
BA_REL_ "GenSigTimeoutTime" BU_SG_REL_ ACC_HS SG_ 313 HptcStVbnStat 250;
BA_REL_ "GenSigSuprvResp" BU_SG_REL_ ACC_HS SG_ 313 ACCSettingType 1;
BA_REL_ "GenSigTimeoutMsg" BU_SG_REL_ ACC_HS SG_ 313 ACCSettingType 313;
BA_REL_ "GenSigTimeoutTime" BU_SG_REL_ ACC_HS SG_ 313 ACCSettingType 250;
BA_REL_ "GenSigSuprvResp" BU_SG_REL_ AHL_AFL_HS SG_ 313 ISA2CCC_ScndCdChr 1;
BA_REL_ "GenSigTimeoutMsg" BU_SG_REL_ AHL_AFL_HS SG_ 313 ISA2CCC_ScndCdChr 313;
BA_REL_ "GenSigTimeoutTime" BU_SG_REL_ AHL_AFL_HS SG_ 313 ISA2CCC_ScndCdChr 250;
BA_REL_ "GenSigSuprvResp" BU_SG_REL_ AHL_AFL_HS SG_ 313 ISA2CCC_FrstCdChr 1;
BA_REL_ "GenSigTimeoutMsg" BU_SG_REL_ AHL_AFL_HS SG_ 313 ISA2CCC_FrstCdChr 313;
BA_REL_ "GenSigTimeoutTime" BU_SG_REL_ AHL_AFL_HS SG_ 313 ISA2CCC_FrstCdChr 250;
BA_REL_ "GenSigSuprvResp" BU_SG_REL_ EBCM_OBD_HS SG_ 313 DispPerfMdCsStRq 1;
BA_REL_ "GenSigTimeoutMsg" BU_SG_REL_ EBCM_OBD_HS SG_ 313 DispPerfMdCsStRq 313;
BA_REL_ "GenSigTimeoutTime" BU_SG_REL_ EBCM_OBD_HS SG_ 313 DispPerfMdCsStRq 250;
BA_REL_ "GenSigSuprvResp" BU_SG_REL_ EBCM_HS SG_ 313 DispPerfMdCsStRq 1;
BA_REL_ "GenSigTimeoutMsg" BU_SG_REL_ EBCM_HS SG_ 313 DispPerfMdCsStRq 313;
BA_REL_ "GenSigTimeoutTime" BU_SG_REL_ EBCM_HS SG_ 313 DispPerfMdCsStRq 250;
BA_REL_ "GenSigSuprvResp" BU_SG_REL_ EBCM_OBD_HS SG_ 313 CrshAlrtStPrsnt 1;
BA_REL_ "GenSigTimeoutMsg" BU_SG_REL_ EBCM_OBD_HS SG_ 313 CrshAlrtStPrsnt 313;
BA_REL_ "GenSigTimeoutTime" BU_SG_REL_ EBCM_OBD_HS SG_ 313 CrshAlrtStPrsnt 250;
BA_REL_ "GenSigSuprvResp" BU_SG_REL_ EBCM_HS SG_ 313 CrshAlrtStPrsnt 1;
BA_REL_ "GenSigTimeoutMsg" BU_SG_REL_ EBCM_HS SG_ 313 CrshAlrtStPrsnt 313;
BA_REL_ "GenSigTimeoutTime" BU_SG_REL_ EBCM_HS SG_ 313 CrshAlrtStPrsnt 250;
BA_REL_ "GenSigSuprvResp" BU_SG_REL_ EOCM_F_HS SG_ 313 FwdClnAlrtCustStngReq 1;
BA_REL_ "GenSigTimeoutMsg" BU_SG_REL_ EOCM_F_HS SG_ 313 FwdClnAlrtCustStngReq 313;
BA_REL_ "GenSigTimeoutTime" BU_SG_REL_ EOCM_F_HS SG_ 313 FwdClnAlrtCustStngReq 250;
BA_REL_ "GenSigSuprvResp" BU_SG_REL_ ACC_HS SG_ 313 FwdClnAlrtCustStngReq 1;
BA_REL_ "GenSigTimeoutMsg" BU_SG_REL_ ACC_HS SG_ 313 FwdClnAlrtCustStngReq 313;
BA_REL_ "GenSigTimeoutTime" BU_SG_REL_ ACC_HS SG_ 313 FwdClnAlrtCustStngReq 250;
BA_REL_ "GenSigSuprvResp" BU_SG_REL_ EOCM_F_HS SG_ 313 GNCustStngReq 1;
BA_REL_ "GenSigTimeoutMsg" BU_SG_REL_ EOCM_F_HS SG_ 313 GNCustStngReq 313;
BA_REL_ "GenSigTimeoutTime" BU_SG_REL_ EOCM_F_HS SG_ 313 GNCustStngReq 250;
BA_REL_ "GenSigSuprvResp" BU_SG_REL_ ACC_HS SG_ 313 GNCustStngReq 1;
BA_REL_ "GenSigTimeoutMsg" BU_SG_REL_ ACC_HS SG_ 313 GNCustStngReq 313;
BA_REL_ "GenSigTimeoutTime" BU_SG_REL_ ACC_HS SG_ 313 GNCustStngReq 250;
BA_REL_ "GenSigSuprvResp" BU_SG_REL_ FCM_HS SG_ 1296 ACCAutoSetSpdStat 1;
BA_REL_ "GenSigTimeoutMsg" BU_SG_REL_ FCM_HS SG_ 1296 ACCAutoSetSpdStat 1296;
BA_REL_ "GenSigTimeoutTime" BU_SG_REL_ FCM_HS SG_ 1296 ACCAutoSetSpdStat 250;
BA_REL_ "GenSigSuprvResp" BU_SG_REL_ BCM_HS SG_ 1296 ACCAutoSetSpdStat 1;
BA_REL_ "GenSigTimeoutMsg" BU_SG_REL_ BCM_HS SG_ 1296 ACCAutoSetSpdStat 1296;
BA_REL_ "GenSigTimeoutTime" BU_SG_REL_ BCM_HS SG_ 1296 ACCAutoSetSpdStat 250;
BA_REL_ "GenSigSuprvResp" BU_SG_REL_ BCM_HS SG_ 536 ACCHptcStVbnRqSeqN 1;
BA_REL_ "GenSigTimeoutMsg" BU_SG_REL_ BCM_HS SG_ 536 ACCHptcStVbnRqSeqN 536;
BA_REL_ "GenSigTimeoutTime" BU_SG_REL_ BCM_HS SG_ 536 ACCHptcStVbnRqSeqN 500;
BA_REL_ "GenSigSuprvResp" BU_SG_REL_ BCM_HS SG_ 536 ACCHptcStVbnReq 1;
BA_REL_ "GenSigTimeoutMsg" BU_SG_REL_ BCM_HS SG_ 536 ACCHptcStVbnReq 536;
BA_REL_ "GenSigTimeoutTime" BU_SG_REL_ BCM_HS SG_ 536 ACCHptcStVbnReq 500;
BA_REL_ "GenSigSuprvResp" BU_SG_REL_ BCM_HS SG_ 570 FCAHptcStVbnRqSeqN 1;
BA_REL_ "GenSigTimeoutMsg" BU_SG_REL_ BCM_HS SG_ 570 FCAHptcStVbnRqSeqN 570;
BA_REL_ "GenSigTimeoutTime" BU_SG_REL_ BCM_HS SG_ 570 FCAHptcStVbnRqSeqN 500;
BA_REL_ "GenSigSuprvResp" BU_SG_REL_ BCM_HS SG_ 570 FCAHptcStVbnReq 1;
BA_REL_ "GenSigTimeoutMsg" BU_SG_REL_ BCM_HS SG_ 570 FCAHptcStVbnReq 570;
BA_REL_ "GenSigTimeoutTime" BU_SG_REL_ BCM_HS SG_ 570 FCAHptcStVbnReq 500;
BA_REL_ "GenSigSuprvResp" BU_SG_REL_ EBCM_OBD_HS SG_ 848 TrlrBrkngGainSet 1;
BA_REL_ "GenSigTimeoutMsg" BU_SG_REL_ EBCM_OBD_HS SG_ 848 TrlrBrkngGainSet 848;
BA_REL_ "GenSigTimeoutTime" BU_SG_REL_ EBCM_OBD_HS SG_ 848 TrlrBrkngGainSet 250;
BA_REL_ "GenSigSuprvResp" BU_SG_REL_ EBCM_OBD_HS SG_ 848 TrlrBrkngGainSet 1;
BA_REL_ "GenSigTimeoutMsg" BU_SG_REL_ EBCM_OBD_HS SG_ 848 TrlrBrkngGainSet 848;
BA_REL_ "GenSigTimeoutTime" BU_SG_REL_ EBCM_OBD_HS SG_ 848 TrlrBrkngGainSet 250;
BA_REL_ "GenSigSuprvResp" BU_SG_REL_ EBCM_HS SG_ 848 TrlrBrkngGainSet 1;
BA_REL_ "GenSigTimeoutMsg" BU_SG_REL_ EBCM_HS SG_ 848 TrlrBrkngGainSet 848;
BA_REL_ "GenSigTimeoutTime" BU_SG_REL_ EBCM_HS SG_ 848 TrlrBrkngGainSet 250;
BA_REL_ "GenSigSuprvResp" BU_SG_REL_ EBCM_HS SG_ 848 TrlrBrkngGainSet 1;
BA_REL_ "GenSigTimeoutMsg" BU_SG_REL_ EBCM_HS SG_ 848 TrlrBrkngGainSet 848;
BA_REL_ "GenSigTimeoutTime" BU_SG_REL_ EBCM_HS SG_ 848 TrlrBrkngGainSet 250;
BA_REL_ "GenSigSuprvResp" BU_SG_REL_ EBCM_OBD_HS SG_ 848 TrlrBrkngFrcOtpt 1;
BA_REL_ "GenSigTimeoutMsg" BU_SG_REL_ EBCM_OBD_HS SG_ 848 TrlrBrkngFrcOtpt 848;
BA_REL_ "GenSigTimeoutTime" BU_SG_REL_ EBCM_OBD_HS SG_ 848 TrlrBrkngFrcOtpt 250;
BA_REL_ "GenSigSuprvResp" BU_SG_REL_ EBCM_OBD_HS SG_ 848 TrlrBrkngFrcOtpt 1;
BA_REL_ "GenSigTimeoutMsg" BU_SG_REL_ EBCM_OBD_HS SG_ 848 TrlrBrkngFrcOtpt 848;
BA_REL_ "GenSigTimeoutTime" BU_SG_REL_ EBCM_OBD_HS SG_ 848 TrlrBrkngFrcOtpt 250;
BA_REL_ "GenSigSuprvResp" BU_SG_REL_ EBCM_HS SG_ 848 TrlrBrkngFrcOtpt 1;
BA_REL_ "GenSigTimeoutMsg" BU_SG_REL_ EBCM_HS SG_ 848 TrlrBrkngFrcOtpt 848;
BA_REL_ "GenSigTimeoutTime" BU_SG_REL_ EBCM_HS SG_ 848 TrlrBrkngFrcOtpt 250;
BA_REL_ "GenSigSuprvResp" BU_SG_REL_ EBCM_HS SG_ 848 TrlrBrkngFrcOtpt 1;
BA_REL_ "GenSigTimeoutMsg" BU_SG_REL_ EBCM_HS SG_ 848 TrlrBrkngFrcOtpt 848;
BA_REL_ "GenSigTimeoutTime" BU_SG_REL_ EBCM_HS SG_ 848 TrlrBrkngFrcOtpt 250;
BA_REL_ "GenSigSuprvResp" BU_SG_REL_ EOCM_F_HS SG_ 848 TrlrHtchSwAtv_ITBC 1;
BA_REL_ "GenSigTimeoutMsg" BU_SG_REL_ EOCM_F_HS SG_ 848 TrlrHtchSwAtv_ITBC 848;
BA_REL_ "GenSigTimeoutTime" BU_SG_REL_ EOCM_F_HS SG_ 848 TrlrHtchSwAtv_ITBC 250;
BA_REL_ "GenSigSuprvResp" BU_SG_REL_ BCM_HS SG_ 848 TrlrHtchSwAtv_ITBC 1;
BA_REL_ "GenSigTimeoutMsg" BU_SG_REL_ BCM_HS SG_ 848 TrlrHtchSwAtv_ITBC 848;
BA_REL_ "GenSigTimeoutTime" BU_SG_REL_ BCM_HS SG_ 848 TrlrHtchSwAtv_ITBC 250;
BA_REL_ "GenSigSuprvResp" BU_SG_REL_ GPCM_HS SG_ 953 DslGlwTypReqd 1;
BA_REL_ "GenSigTimeoutMsg" BU_SG_REL_ GPCM_HS SG_ 953 DslGlwTypReqd 953;
BA_REL_ "GenSigTimeoutTime" BU_SG_REL_ GPCM_HS SG_ 953 DslGlwTypReqd 250;
BA_REL_ "GenSigSuprvResp" BU_SG_REL_ GPCM_HS SG_ 953 RdctHtrCReq 1;
BA_REL_ "GenSigTimeoutMsg" BU_SG_REL_ GPCM_HS SG_ 953 RdctHtrCReq 953;
BA_REL_ "GenSigTimeoutTime" BU_SG_REL_ GPCM_HS SG_ 953 RdctHtrCReq 250;
BA_REL_ "GenSigSuprvResp" BU_SG_REL_ GPCM_HS SG_ 953 RdctHtrBReq 1;
BA_REL_ "GenSigTimeoutMsg" BU_SG_REL_ GPCM_HS SG_ 953 RdctHtrBReq 953;
BA_REL_ "GenSigTimeoutTime" BU_SG_REL_ GPCM_HS SG_ 953 RdctHtrBReq 250;
BA_REL_ "GenSigSuprvResp" BU_SG_REL_ GPCM_HS SG_ 953 RdctHtrAReq 1;
BA_REL_ "GenSigTimeoutMsg" BU_SG_REL_ GPCM_HS SG_ 953 RdctHtrAReq 953;
BA_REL_ "GenSigTimeoutTime" BU_SG_REL_ GPCM_HS SG_ 953 RdctHtrAReq 250;
BA_REL_ "GenSigSuprvResp" BU_SG_REL_ VICM_HS SG_ 711 RdVltCrntTmpModInitStat 1;
BA_REL_ "GenSigTimeoutMsg" BU_SG_REL_ VICM_HS SG_ 711 RdVltCrntTmpModInitStat 711;
BA_REL_ "GenSigTimeoutTime" BU_SG_REL_ VICM_HS SG_ 711 RdVltCrntTmpModInitStat 250;
BA_REL_ "GenSigSuprvResp" BU_SG_REL_ VICM_HS SG_ 711 RdHVltBatPckVlt 1;
BA_REL_ "GenSigTimeoutMsg" BU_SG_REL_ VICM_HS SG_ 711 RdHVltBatPckVlt 711;
BA_REL_ "GenSigTimeoutTime" BU_SG_REL_ VICM_HS SG_ 711 RdHVltBatPckVlt 250;
BA_REL_ "GenSigSuprvResp" BU_SG_REL_ VICM_HS SG_ 711 RdHVltBatPckVlt 1;
BA_REL_ "GenSigTimeoutMsg" BU_SG_REL_ VICM_HS SG_ 711 RdHVltBatPckVlt 711;
BA_REL_ "GenSigTimeoutTime" BU_SG_REL_ VICM_HS SG_ 711 RdHVltBatPckVlt 250;
BA_REL_ "GenSigSuprvResp" BU_SG_REL_ VICM_HS SG_ 711 RdHVltBatPckCrnt 1;
BA_REL_ "GenSigTimeoutMsg" BU_SG_REL_ VICM_HS SG_ 711 RdHVltBatPckCrnt 711;
BA_REL_ "GenSigTimeoutTime" BU_SG_REL_ VICM_HS SG_ 711 RdHVltBatPckCrnt 250;
BA_REL_ "GenSigSuprvResp" BU_SG_REL_ VICM_HS SG_ 711 RdHVltBatPckCrnt 1;
BA_REL_ "GenSigTimeoutMsg" BU_SG_REL_ VICM_HS SG_ 711 RdHVltBatPckCrnt 711;
BA_REL_ "GenSigTimeoutTime" BU_SG_REL_ VICM_HS SG_ 711 RdHVltBatPckCrnt 250;
BA_REL_ "GenSigSuprvResp" BU_SG_REL_ VICM_HS SG_ 711 RdntHVBatClOvrVltTstAct 1;
BA_REL_ "GenSigTimeoutMsg" BU_SG_REL_ VICM_HS SG_ 711 RdntHVBatClOvrVltTstAct 711;
BA_REL_ "GenSigTimeoutTime" BU_SG_REL_ VICM_HS SG_ 711 RdntHVBatClOvrVltTstAct 250;
BA_REL_ "GenSigSuprvResp" BU_SG_REL_ PFAF_HS SG_ 304 PedFrndlyAlrtCsStReq 1;
BA_REL_ "GenSigTimeoutMsg" BU_SG_REL_ PFAF_HS SG_ 304 PedFrndlyAlrtCsStReq 304;
BA_REL_ "GenSigTimeoutTime" BU_SG_REL_ PFAF_HS SG_ 304 PedFrndlyAlrtCsStReq 2500;
BA_REL_ "GenSigVDAFailComment" BU_SG_REL_ BCP_HS SG_ 1105 HybVehHiVltInvDisRqd "Airbag Virtual Device Availability";
BA_REL_ "GenSigVDAFailResp" BU_SG_REL_ BCP_HS SG_ 1105 HybVehHiVltInvDisRqd 1;
BA_REL_ "GenSigSuprvResp" BU_SG_REL_ BCP_HS SG_ 1105 HybVehHiVltInvDisRqd 1;
BA_REL_ "GenSigTimeoutMsg" BU_SG_REL_ BCP_HS SG_ 1105 HybVehHiVltInvDisRqd 1105;
BA_REL_ "GenSigTimeoutTime" BU_SG_REL_ BCP_HS SG_ 1105 HybVehHiVltInvDisRqd 250;
BA_REL_ "GenSigRxStartValue" BU_SG_REL_ PCM_HS SG_ 1005 EnhSvVehTopSpdLmR "$0 - No Action";
BA_REL_ "GenSigRxStartValue" BU_SG_REL_ ECM_HS SG_ 1005 EnhSvVehTopSpdLmR "$0 - No Action";
BA_REL_ "GenSigSuprvResp" BU_SG_REL_ PCM_HS SG_ 688 StrtrGenSpd 1;
BA_REL_ "GenSigTimeoutMsg" BU_SG_REL_ PCM_HS SG_ 688 StrtrGenSpd 688;
BA_REL_ "GenSigTimeoutTime" BU_SG_REL_ PCM_HS SG_ 688 StrtrGenSpd 250;
BA_REL_ "GenSigSuprvResp" BU_SG_REL_ ECM_HS SG_ 688 StrtrGenSpd 1;
BA_REL_ "GenSigTimeoutMsg" BU_SG_REL_ ECM_HS SG_ 688 StrtrGenSpd 688;
BA_REL_ "GenSigTimeoutTime" BU_SG_REL_ ECM_HS SG_ 688 StrtrGenSpd 250;
BA_REL_ "GenSigSuprvResp" BU_SG_REL_ EBCM_OBD_HS SG_ 688 StrtrGenSpd 1;
BA_REL_ "GenSigTimeoutMsg" BU_SG_REL_ EBCM_OBD_HS SG_ 688 StrtrGenSpd 688;
BA_REL_ "GenSigTimeoutTime" BU_SG_REL_ EBCM_OBD_HS SG_ 688 StrtrGenSpd 250;
BA_REL_ "GenSigSuprvResp" BU_SG_REL_ EBCM_HS SG_ 688 StrtrGenSpd 1;
BA_REL_ "GenSigTimeoutMsg" BU_SG_REL_ EBCM_HS SG_ 688 StrtrGenSpd 688;
BA_REL_ "GenSigTimeoutTime" BU_SG_REL_ EBCM_HS SG_ 688 StrtrGenSpd 250;
BA_REL_ "GenSigSuprvResp" BU_SG_REL_ FCP_HS SG_ 993 HybVehHiVltSysDisbld 1;
BA_REL_ "GenSigTimeoutMsg" BU_SG_REL_ FCP_HS SG_ 993 HybVehHiVltSysDisbld 993;
BA_REL_ "GenSigTimeoutTime" BU_SG_REL_ FCP_HS SG_ 993 HybVehHiVltSysDisbld 250;
BA_REL_ "GenSigSuprvResp" BU_SG_REL_ ONSTAR_HS SG_ 993 HybVehHiVltSysDisbld 1;
BA_REL_ "GenSigTimeoutMsg" BU_SG_REL_ ONSTAR_HS SG_ 993 HybVehHiVltSysDisbld 993;
BA_REL_ "GenSigTimeoutTime" BU_SG_REL_ ONSTAR_HS SG_ 993 HybVehHiVltSysDisbld 250;
BA_REL_ "GenSigSuprvResp" BU_SG_REL_ BCM_HS SG_ 993 SvcHybridSysIO 1;
BA_REL_ "GenSigTimeoutMsg" BU_SG_REL_ BCM_HS SG_ 993 SvcHybridSysIO 993;
BA_REL_ "GenSigTimeoutTime" BU_SG_REL_ BCM_HS SG_ 993 SvcHybridSysIO 250;
BA_REL_ "GenSigSuprvResp" BU_SG_REL_ BCM_HS SG_ 490 SrvcFlSysPrkInOpnArIO 1;
BA_REL_ "GenSigTimeoutMsg" BU_SG_REL_ BCM_HS SG_ 490 SrvcFlSysPrkInOpnArIO 490;
BA_REL_ "GenSigTimeoutTime" BU_SG_REL_ BCM_HS SG_ 490 SrvcFlSysPrkInOpnArIO 250;
BA_REL_ "GenSigSuprvResp" BU_SG_REL_ PCM_HS SG_ 431 TransVehTopSpdLim 1;
BA_REL_ "GenSigTimeoutMsg" BU_SG_REL_ PCM_HS SG_ 431 TransVehTopSpdLim 431;
BA_REL_ "GenSigTimeoutTime" BU_SG_REL_ PCM_HS SG_ 431 TransVehTopSpdLim 250;
BA_REL_ "GenSigSuprvResp" BU_SG_REL_ ECM_HS SG_ 431 TransVehTopSpdLim 1;
BA_REL_ "GenSigTimeoutMsg" BU_SG_REL_ ECM_HS SG_ 431 TransVehTopSpdLim 431;
BA_REL_ "GenSigTimeoutTime" BU_SG_REL_ ECM_HS SG_ 431 TransVehTopSpdLim 250;
BA_REL_ "GenSigSuprvResp" BU_SG_REL_ PCM_HS SG_ 431 TransMinVoltReq 1;
BA_REL_ "GenSigTimeoutMsg" BU_SG_REL_ PCM_HS SG_ 431 TransMinVoltReq 431;
BA_REL_ "GenSigTimeoutTime" BU_SG_REL_ PCM_HS SG_ 431 TransMinVoltReq 250;
BA_REL_ "GenSigSuprvResp" BU_SG_REL_ ECM_HS SG_ 431 TransMinVoltReq 1;
BA_REL_ "GenSigTimeoutMsg" BU_SG_REL_ ECM_HS SG_ 431 TransMinVoltReq 431;
BA_REL_ "GenSigTimeoutTime" BU_SG_REL_ ECM_HS SG_ 431 TransMinVoltReq 250;
BA_REL_ "GenSigSuprvResp" BU_SG_REL_ PCM_HS SG_ 431 TDslPrtFltrIdlRgtnMdAtv 1;
BA_REL_ "GenSigTimeoutMsg" BU_SG_REL_ PCM_HS SG_ 431 TDslPrtFltrIdlRgtnMdAtv 431;
BA_REL_ "GenSigTimeoutTime" BU_SG_REL_ PCM_HS SG_ 431 TDslPrtFltrIdlRgtnMdAtv 250;
BA_REL_ "GenSigSuprvResp" BU_SG_REL_ ECM_HS SG_ 431 TDslPrtFltrIdlRgtnMdAtv 1;
BA_REL_ "GenSigTimeoutMsg" BU_SG_REL_ ECM_HS SG_ 431 TDslPrtFltrIdlRgtnMdAtv 431;
BA_REL_ "GenSigTimeoutTime" BU_SG_REL_ ECM_HS SG_ 431 TDslPrtFltrIdlRgtnMdAtv 250;
BA_REL_ "GenSigSuprvResp" BU_SG_REL_ PCM_HS SG_ 431 DrvlneTrqStabStat 1;
BA_REL_ "GenSigTimeoutMsg" BU_SG_REL_ PCM_HS SG_ 431 DrvlneTrqStabStat 431;
BA_REL_ "GenSigTimeoutTime" BU_SG_REL_ PCM_HS SG_ 431 DrvlneTrqStabStat 250;
BA_REL_ "GenSigSuprvResp" BU_SG_REL_ ECM_HS SG_ 431 DrvlneTrqStabStat 1;
BA_REL_ "GenSigTimeoutMsg" BU_SG_REL_ ECM_HS SG_ 431 DrvlneTrqStabStat 431;
BA_REL_ "GenSigTimeoutTime" BU_SG_REL_ ECM_HS SG_ 431 DrvlneTrqStabStat 250;
BA_REL_ "GenSigSuprvResp" BU_SG_REL_ PCM_HS SG_ 431 TrnsTrqCnvCltDsrSlp 1;
BA_REL_ "GenSigTimeoutMsg" BU_SG_REL_ PCM_HS SG_ 431 TrnsTrqCnvCltDsrSlp 431;
BA_REL_ "GenSigTimeoutTime" BU_SG_REL_ PCM_HS SG_ 431 TrnsTrqCnvCltDsrSlp 250;
BA_REL_ "GenSigSuprvResp" BU_SG_REL_ ECM_HS SG_ 431 TrnsTrqCnvCltDsrSlp 1;
BA_REL_ "GenSigTimeoutMsg" BU_SG_REL_ ECM_HS SG_ 431 TrnsTrqCnvCltDsrSlp 431;
BA_REL_ "GenSigTimeoutTime" BU_SG_REL_ ECM_HS SG_ 431 TrnsTrqCnvCltDsrSlp 250;
BA_REL_ "GenSigSuprvResp" BU_SG_REL_ PCM_HS SG_ 431 TrnsStWntrMdOvrd 1;
BA_REL_ "GenSigTimeoutMsg" BU_SG_REL_ PCM_HS SG_ 431 TrnsStWntrMdOvrd 431;
BA_REL_ "GenSigTimeoutTime" BU_SG_REL_ PCM_HS SG_ 431 TrnsStWntrMdOvrd 250;
BA_REL_ "GenSigSuprvResp" BU_SG_REL_ ECM_HS SG_ 431 TrnsStWntrMdOvrd 1;
BA_REL_ "GenSigTimeoutMsg" BU_SG_REL_ ECM_HS SG_ 431 TrnsStWntrMdOvrd 431;
BA_REL_ "GenSigTimeoutTime" BU_SG_REL_ ECM_HS SG_ 431 TrnsStWntrMdOvrd 250;
BA_REL_ "GenSigSuprvResp" BU_SG_REL_ PCM_HS SG_ 431 TrnsStTwHaulMdOvrd 1;
BA_REL_ "GenSigTimeoutMsg" BU_SG_REL_ PCM_HS SG_ 431 TrnsStTwHaulMdOvrd 431;
BA_REL_ "GenSigTimeoutTime" BU_SG_REL_ PCM_HS SG_ 431 TrnsStTwHaulMdOvrd 250;
BA_REL_ "GenSigSuprvResp" BU_SG_REL_ ECM_HS SG_ 431 TrnsStTwHaulMdOvrd 1;
BA_REL_ "GenSigTimeoutMsg" BU_SG_REL_ ECM_HS SG_ 431 TrnsStTwHaulMdOvrd 431;
BA_REL_ "GenSigTimeoutTime" BU_SG_REL_ ECM_HS SG_ 431 TrnsStTwHaulMdOvrd 250;
BA_REL_ "GenSigSuprvResp" BU_SG_REL_ PCM_HS SG_ 431 TrnsStSprtMdOvrd 1;
BA_REL_ "GenSigTimeoutMsg" BU_SG_REL_ PCM_HS SG_ 431 TrnsStSprtMdOvrd 431;
BA_REL_ "GenSigTimeoutTime" BU_SG_REL_ PCM_HS SG_ 431 TrnsStSprtMdOvrd 250;
BA_REL_ "GenSigSuprvResp" BU_SG_REL_ ECM_HS SG_ 431 TrnsStSprtMdOvrd 1;
BA_REL_ "GenSigTimeoutMsg" BU_SG_REL_ ECM_HS SG_ 431 TrnsStSprtMdOvrd 431;
BA_REL_ "GenSigTimeoutTime" BU_SG_REL_ ECM_HS SG_ 431 TrnsStSprtMdOvrd 250;
BA_REL_ "GenSigSuprvResp" BU_SG_REL_ PCM_HS SG_ 431 TrnsStEconMdOvrd 1;
BA_REL_ "GenSigTimeoutMsg" BU_SG_REL_ PCM_HS SG_ 431 TrnsStEconMdOvrd 431;
BA_REL_ "GenSigTimeoutTime" BU_SG_REL_ PCM_HS SG_ 431 TrnsStEconMdOvrd 250;
BA_REL_ "GenSigSuprvResp" BU_SG_REL_ ECM_HS SG_ 431 TrnsStEconMdOvrd 1;
BA_REL_ "GenSigTimeoutMsg" BU_SG_REL_ ECM_HS SG_ 431 TrnsStEconMdOvrd 431;
BA_REL_ "GenSigTimeoutTime" BU_SG_REL_ ECM_HS SG_ 431 TrnsStEconMdOvrd 250;
BA_REL_ "GenSigSuprvResp" BU_SG_REL_ PCM_HS SG_ 715 ACCATC_SplREngInpR 1;
BA_REL_ "GenSigTimeoutTime" BU_SG_REL_ PCM_HS SG_ 715 ACCATC_SplREngInpR 250;
BA_REL_ "GenSigSuprvResp" BU_SG_REL_ ECM_HS SG_ 715 ACCATC_SplREngInpR 1;
BA_REL_ "GenSigTimeoutTime" BU_SG_REL_ ECM_HS SG_ 715 ACCATC_SplREngInpR 250;
BA_REL_ "GenSigSuprvResp" BU_SG_REL_ PCM_HS SG_ 715 ACCATC_DrvAstdGoSt 1;
BA_REL_ "GenSigTimeoutTime" BU_SG_REL_ PCM_HS SG_ 715 ACCATC_DrvAstdGoSt 250;
BA_REL_ "GenSigSuprvResp" BU_SG_REL_ ECM_HS SG_ 715 ACCATC_DrvAstdGoSt 1;
BA_REL_ "GenSigTimeoutTime" BU_SG_REL_ ECM_HS SG_ 715 ACCATC_DrvAstdGoSt 250;
BA_REL_ "GenSigSuprvResp" BU_SG_REL_ PCM_HS SG_ 715 ACCATC_AxlTrqRq 1;
BA_REL_ "GenSigTimeoutTime" BU_SG_REL_ PCM_HS SG_ 715 ACCATC_AxlTrqRq 250;
BA_REL_ "GenSigSuprvResp" BU_SG_REL_ ECM_HS SG_ 715 ACCATC_AxlTrqRq 1;
BA_REL_ "GenSigTimeoutTime" BU_SG_REL_ ECM_HS SG_ 715 ACCATC_AxlTrqRq 250;
BA_REL_ "GenSigSuprvResp" BU_SG_REL_ PCM_HS SG_ 715 ACCATC_ACCTyp 1;
BA_REL_ "GenSigTimeoutTime" BU_SG_REL_ PCM_HS SG_ 715 ACCATC_ACCTyp 250;
BA_REL_ "GenSigSuprvResp" BU_SG_REL_ ECM_HS SG_ 715 ACCATC_ACCTyp 1;
BA_REL_ "GenSigTimeoutTime" BU_SG_REL_ ECM_HS SG_ 715 ACCATC_ACCTyp 250;
BA_REL_ "GenSigSuprvResp" BU_SG_REL_ PCM_HS SG_ 715 ACCATC_ACCAct 1;
BA_REL_ "GenSigTimeoutTime" BU_SG_REL_ PCM_HS SG_ 715 ACCATC_ACCAct 250;
BA_REL_ "GenSigSuprvResp" BU_SG_REL_ ECM_HS SG_ 715 ACCATC_ACCAct 1;
BA_REL_ "GenSigTimeoutTime" BU_SG_REL_ ECM_HS SG_ 715 ACCATC_ACCAct 250;
BA_REL_ "GenSigSuprvResp" BU_SG_REL_ PCM_HS SG_ 715 ACCAxlTrqCmdProt 1;
BA_REL_ "GenSigTimeoutTime" BU_SG_REL_ PCM_HS SG_ 715 ACCAxlTrqCmdProt 250;
BA_REL_ "GenSigSuprvResp" BU_SG_REL_ ECM_HS SG_ 715 ACCAxlTrqCmdProt 1;
BA_REL_ "GenSigTimeoutTime" BU_SG_REL_ ECM_HS SG_ 715 ACCAxlTrqCmdProt 250;
BA_REL_ "GenSigSuprvResp" BU_SG_REL_ PCM_HS SG_ 715 ACCCmndAlvRlgCnt 1;
BA_REL_ "GenSigTimeoutTime" BU_SG_REL_ PCM_HS SG_ 715 ACCCmndAlvRlgCnt 250;
BA_REL_ "GenSigSuprvResp" BU_SG_REL_ ECM_HS SG_ 715 ACCCmndAlvRlgCnt 1;
BA_REL_ "GenSigTimeoutTime" BU_SG_REL_ ECM_HS SG_ 715 ACCCmndAlvRlgCnt 250;
BA_REL_ "GenSigSuprvResp" BU_SG_REL_ EOCM_F_HS SG_ 1267 VehMassNom 1;
BA_REL_ "GenSigTimeoutMsg" BU_SG_REL_ EOCM_F_HS SG_ 1267 VehMassNom 1267;
BA_REL_ "GenSigTimeoutTime" BU_SG_REL_ EOCM_F_HS SG_ 1267 VehMassNom 2500;
BA_REL_ "GenSigSuprvResp" BU_SG_REL_ ACC_HS SG_ 1267 VehMassNom 1;
BA_REL_ "GenSigTimeoutMsg" BU_SG_REL_ ACC_HS SG_ 1267 VehMassNom 1267;
BA_REL_ "GenSigTimeoutTime" BU_SG_REL_ ACC_HS SG_ 1267 VehMassNom 5000;
BA_REL_ "GenSigSuprvResp" BU_SG_REL_ EOCM_F_HS SG_ 453 DrvIntndAxlTrqMin 1;
BA_REL_ "GenSigTimeoutTime" BU_SG_REL_ EOCM_F_HS SG_ 453 DrvIntndAxlTrqMin 120;
BA_REL_ "GenSigSuprvResp" BU_SG_REL_ ACC_HS SG_ 453 DrvIntndAxlTrqMin 1;
BA_REL_ "GenSigTimeoutMsg" BU_SG_REL_ ACC_HS SG_ 453 DrvIntndAxlTrqMin 453;
BA_REL_ "GenSigTimeoutTime" BU_SG_REL_ ACC_HS SG_ 453 DrvIntndAxlTrqMin 125;
BA_REL_ "GenSigSuprvResp" BU_SG_REL_ EOCM_F_HS SG_ 453 DrvIntndAxlTrqMax 1;
BA_REL_ "GenSigTimeoutTime" BU_SG_REL_ EOCM_F_HS SG_ 453 DrvIntndAxlTrqMax 120;
BA_REL_ "GenSigSuprvResp" BU_SG_REL_ ACC_HS SG_ 453 DrvIntndAxlTrqMax 1;
BA_REL_ "GenSigTimeoutMsg" BU_SG_REL_ ACC_HS SG_ 453 DrvIntndAxlTrqMax 453;
BA_REL_ "GenSigTimeoutTime" BU_SG_REL_ ACC_HS SG_ 453 DrvIntndAxlTrqMax 125;
BA_REL_ "GenSigSuprvResp" BU_SG_REL_ VICM_HS SG_ 453 DrvIntndAxlTrq 1;
BA_REL_ "GenSigTimeoutMsg" BU_SG_REL_ VICM_HS SG_ 453 DrvIntndAxlTrq 453;
BA_REL_ "GenSigTimeoutTime" BU_SG_REL_ VICM_HS SG_ 453 DrvIntndAxlTrq 250;
BA_REL_ "GenSigSuprvResp" BU_SG_REL_ EOCM_F_HS SG_ 453 DrvIntndAxlTrq 1;
BA_REL_ "GenSigTimeoutTime" BU_SG_REL_ EOCM_F_HS SG_ 453 DrvIntndAxlTrq 120;
BA_REL_ "GenSigVBitResp" BU_SG_REL_ ACC_HS SG_ 453 DrvIntndAxlTrq 1;
BA_REL_ "GenSigRxStartValue" BU_SG_REL_ ACC_HS SG_ 453 DrvIntndAxlTrq "0";
BA_REL_ "GenSigSuprvResp" BU_SG_REL_ ACC_HS SG_ 453 DrvIntndAxlTrq 1;
BA_REL_ "GenSigTimeoutMsg" BU_SG_REL_ ACC_HS SG_ 453 DrvIntndAxlTrq 453;
BA_REL_ "GenSigTimeoutTime" BU_SG_REL_ ACC_HS SG_ 453 DrvIntndAxlTrq 125;
VAL_ 647 DrvMntnMdCmnd 1 "true" 0 "false" ;
VAL_ 647 DrvHldMdCmnd 1 "true" 0 "false" ;
VAL_ 647 DrPTGrdBrkDsbMdCmd 1 "true" 0 "false" ;
VAL_ 647 DrvWntrMdCmd 1 "true" 0 "false" ;
VAL_ 647 DrvTwHaulMdCmd 1 "true" 0 "false" ;
VAL_ 647 DrvSprtMdCmd 1 "true" 0 "false" ;
VAL_ 647 DrvEconMdCmd 1 "true" 0 "false" ;
VAL_ 647 EngCntrlDtrmdTrfCRngV 1 "Invalid" 0 "Valid" ;
VAL_ 647 EngCntrlDtrmdTrfCRng 3 "Neutral" 2 "Unused and Reserved" 1 "Low" 0 "High" ;
VAL_ 647 EngCntrlUtldTrnCsRng 3 "Neutral" 2 "Unused and Reserved" 1 "Low" 0 "High" ;
VAL_ 647 EngCntrlUtldTrnCsRgIn 1 "true" 0 "false" ;
VAL_ 368 EnvIdRspSt5 0 "No info" 1 "Info valid" 2 "Incorrect immo id" 3 "Environment id request" ;
VAL_ 995 RdHVltBatMaxSnsTmpV 0 "Valid" 1 "Invalid" ;
VAL_ 995 RdHVltBatMaxSnsTmpM 0 "Don't Use Data" 1 "Use Data" ;
VAL_ 995 RdHVltBatMinClVltV 1 "Invalid" 0 "Valid" ;
VAL_ 995 RdHVltBatMinClVltM 1 "Use Data" 0 "Don't Use Data" ;
VAL_ 995 RdHVBatMinSnsTmpV 1 "Invalid" 0 "Valid" ;
VAL_ 995 RdHVBatMinSnsTmpM 0 "Don't Use Data" 1 "Use Data" ;
VAL_ 995 RdHVltBatMaxClVltV 1 "Invalid" 0 "Valid" ;
VAL_ 995 RdHVltBatMaxClVltM 1 "Use Data" 0 "Don't Use Data" ;
VAL_ 995 RdHVltBatAvgClVltV 1 "Invalid" 0 "Valid" ;
VAL_ 995 RdHVltBatAvgClVltM 0 "Don't Use Data" 1 "Use Data" ;
VAL_ 971 BatVltHiResV 1 "Invalid" 0 "Valid" ;
VAL_ 971 BCHR_BattCrntRwVlMu 3 "Multiplier Factor 256" 2 "Multiplier Factor 64" 1 "Multiplier Factor 8" 0 "Multiplier Factor 1" ;
VAL_ 971 BCHR_BattCrntRwValV 1 "Invalid" 0 "Valid" ;
VAL_ 209 ChsBrkPdlPsERltdV 1 "Invalid" 0 "Valid" ;
VAL_ 454 CSPATR_TrqIntrvnTyp 3 "Minimum and Maximum Limit" 2 "Minimum Limit" 1 "Maximum Limit" 0 "No Intervention" ;
VAL_ 454 CSPATR_TrqRqTyp 0 "Absolute Torque Request" ;
VAL_ 454 ChsSysAxlTqRqRspTyp 4 "Braking Torque Request" 3 "Automatic Actuator Selection" 2 "Maximum Range Request" 1 "Pleasability Limited Request" 0 "Inactive" ;
VAL_ 554 ElecPrkBrkAvailStat 7 "Unused and Reserved 3" 6 "Unused and Reserved 2" 5 "Unused and Reserved 1" 4 "Unavailable, Failed other" 3 "Unavailable, Failed Released" 2 "Unavailable, Failed Applied" 1 "Available, Not Failed" 0 "Unavailable, Not Failed" ;
VAL_ 554 ElecPrkBrkApplStat 3 "Park Brake Application in Progress" 2 "Park brake Released" 1 "Park Brake Applied" 0 "Unknown" ;
VAL_ 487 EngRunng 1 "true" 0 "false" ;
VAL_ 487 FlPmpEDscOtptCmdSta 1 "Fuel Pump Enabled" 0 "Fuel Pump Disabled" ;
VAL_ 487 FuelCntlSysFltPrsnt 1 "true" 0 "false" ;
VAL_ 487 HiPresFuelPmpCntMd 6 "Zero Flow Mode" 5 "Noise Control Max Mode" 4 "Noise Control Disable Mode" 3 "Start Mode" 2 "Normal Mode" 1 "DFCO Mode" 0 "Disable Mode" ;
VAL_ 566 RdHVBatLwParMdReq 1 "true" 0 "false" ;
VAL_ 566 RdHVBtClOVFFTstRq 1 "true" 0 "false" ;
VAL_ 566 ClimCtrlHVDvcShtdwnCmd 1 "true" 0 "false" ;
VAL_ 566 VICntlModRunCrkTrmSt 1 "Active" 0 "Inactive" ;
VAL_ 566 VICMHVEnMgCmEnTrS 0 "Inactive" 1 "Active" ;
VAL_ 566 ChrgSysPrkBrkAnmsBrkReq 1 "true" 0 "false" ;
VAL_ 566 VICMClrLgsDgInfo 1 "true" 0 "false" ;
VAL_ 566 HybVehHiVltSysDisbld_236 1 "true" 0 "false" ;
VAL_ 421 AccPwrMdlHiVltInpCrntV 1 "Invalid" 0 "Valid" ;
VAL_ 421 HTGR_ReqVal 0 "No Action" 1 "First Gear" 2 "Second Gear" 3 "Third Gear" 4 "Fourth Gear" 5 "Fifth Gear" 6 "Sixth Gear" 7 "Seventh Gear" 8 "Eighth Gear" ;
VAL_ 421 HTGR_ReqTyp 0 "No Request" 1 "Max Gear Request" 2 "Min Gear Request" 3 "Hold Gear" ;
VAL_ 421 HTGR_ReqPrty 0 "Desired" 1 "Recommended" 2 "Strongly Recommended" 3 "Mandatory" ;
VAL_ 421 HTCCR_ReqVal 0 "No Request" 1 "Immediate Off" 2 "Ramp Off A" 3 "Ramp Off B" 4 "Apply" ;
VAL_ 421 HTCCR_ReqPrty 0 "Desired" 1 "Recommended" 2 "Strongly Recommended" 3 "Mandatory" ;
VAL_ 421 TrnsAuxPmpAct 1 "true" 0 "false" ;
VAL_ 421 HybSnsBrkPdlPosV 1 "Invalid" 0 "Valid" ;
VAL_ 456 PTESR_EngSpdCntlRs 3 "Stability Optimized Cond 2" 2 "Stability Optimized Cond 1" 1 "Transient Optimized" 0 "No Suggestion" ;
VAL_ 456 PTESR_EngSpdIntTyp 1 "Engine Speed Max Limit" 0 "No Intervention" ;
VAL_ 456 PTTR_TrqRedRlzSugg 1 "Transient Optimized" 0 "No Suggestion" ;
VAL_ 456 PTTR_TrqInvTyp 1 "Maximum Limit" 0 "No Intervention" ;
VAL_ 884 AdvWthrStat 0 "Clear weather" 1 "Fog" 2 "Snow" 3 "Rain" ;
VAL_ 884 DtctdLghtSrcDrvngDrctn 0 "Unknown" 1 "Incoming Traffic" 2 "Ahead Traffic" ;
VAL_ 884 TwnDtctnSts 0 "Not Active" 1 "Town Not Detected" 2 "Town Detected" 3 "Undefined" ;
VAL_ 884 DtctdLghtSrcDstncV 1 "Invalid" 0 "Valid" ;
VAL_ 884 IntLghtRngAct 1 "true" 0 "false" ;
VAL_ 882 AdvFrntLghtSysHiBmIO 1 "true" 0 "false" ;
VAL_ 882 RghtHndLftHndTrffc 0 "Left Hand Traffic" 1 "Right Hand Traffic" ;
VAL_ 393 TPCTR_TrqIntrvnTyp 3 "Unused and Reserved" 2 "Minimum Limit" 1 "Maximum Limit" 0 "No Request" ;
VAL_ 393 TICTR_TorqRespTyp 3 "Automatic Actuator Selection" 2 "Maximum Range" 1 "Pleasability Limited" 0 "Inactive" ;
VAL_ 199 TORSValidity 1 "Invalid" 0 "Valid" ;
VAL_ 199 TORSRstOcrd 1 "true" 0 "false" ;
VAL_ 199 TORSLstTransType 3 "Undefined" 2 "Falling Transition" 1 "Rising Transition" 0 "Single Edge Sensor" ;
VAL_ 199 TORSRotDir 3 "Undefined" 2 "Reverse" 1 "Forward" 0 "Unknown" ;
VAL_ 398 EngNTrnsRegStdyStTqV 1 "Invalid" 0 "Valid" ;
VAL_ 398 AccKdwnAtv 1 "true" 0 "false" ;
VAL_ 398 EngActStdyStTorqV 1 "Invalid" 0 "Valid" ;
VAL_ 398 TrnsEngSpdReqFld 1 "true" 0 "false" ;
VAL_ 398 PTACCAct 1 "true" 0 "false" ;
VAL_ 398 CTSS_StbltyLvl 7 "Level 7" 6 "Level 6" 5 "Level 5" 4 "Level 4" 3 "Level 3" 2 "Level 2" 1 "Level 1" 0 "Level 0" ;
VAL_ 398 CTSS_StbltyTyp 7 "Unused and Reserved 4" 6 "Unused and Reserved 3" 5 "Unused and Reserved 2" 4 "Unused and Reserved 1" 3 "Torque Increase Pending" 2 "Torque Decrease Pending" 1 "Torque High Pulsation" 0 "Normal Stability" ;
VAL_ 398 EngImmTrqTnsRqStat 0 "No Request" 7 "Unused and Reserved" 6 "Control System Failure Permanent" 5 "Control System Failure Temporary" 4 "Serial Data Failure Permanent" 3 "Serial Data Failure Temporary" 2 "Lost Arbitration" 1 "Request Honored" ;
VAL_ 398 EngImmTrqTnsRqLmSt 7 "Unused and Reserved 4" 6 "Unused and Reserved 3" 5 "Unused and Reserved 2" 4 "Unused and Reserved 1" 3 "Value Limited High" 2 "Value Limited Low" 1 "Rate Limited" 0 "Not Limited" ;
VAL_ 398 EngPrdctTrqTnsRqStat 7 "Unused and Reserved" 6 "Control System Failure Permanent" 5 "Control System Failure Temporary" 4 "Serial Data Failure Permanent" 3 "Serial Data Failure Temporary" 2 "Lost Arbitration" 1 "Request Honored" 0 "No Request" ;
VAL_ 398 EngPrdctTrqTnsRqLmS 7 "Unused and Reserved 4" 6 "Unused and Reserved 3" 5 "Unused and Reserved 2" 4 "Unused and Reserved 1" 3 "Value Limited High" 2 "Value Limited Low" 1 "Rate Limited" 0 "Not Limited" ;
VAL_ 464 FrtAxlOpeMod 0 "Open" 1 "Active" 2 "Locked" 3 "Unknown" ;
VAL_ 390 RdHVInvRatVltV 1 "Invalid" 0 "Valid" ;
VAL_ 390 EngActDmpgDsblReq 1 "true" 0 "false" ;
VAL_ 390 HybExtndDcFuelCORq 1 "true" 0 "false" ;
VAL_ 390 EstMtrPwrLossV 1 "Invalid" 0 "Valid" ;
VAL_ 390 HybCmmFailRdPwrCmd 1 "true" 0 "false" ;
VAL_ 390 HybACCompRq 3 "Reserved" 2 "Disengage" 1 "Engage" 0 "No Action" ;
VAL_ 390 HESSI_EngStrtTyp 9 "Compression Test" 8 "Auto Start Generic" 7 "Auto Start Aggressive" 6 "Auto Start Normal" 5 "Auto Start Smooth" 4 "Key Start Generic" 3 "Key Start Low Power B" 2 "Key Start Low Power" 1 "Key Start Normal" 0 "No Start" ;
VAL_ 390 HESSI_EngStrtStpMd 7 "Start Failed" 6 "Stop Pending" 5 "Disable Fuel" 4 "Producing Torque" 3 "Enable Fuel" 2 "Start Pending" 1 "Immediate Stop" 0 "Stop" ;
VAL_ 390 HybCrnkAbrtd 1 "true" 0 "false" ;
VAL_ 390 CnvntlEngStrtEnbld 1 "true" 0 "false" ;
VAL_ 390 HybEngCylDeactReq 1 "true" 0 "false" ;
VAL_ 390 HybDFCOReq 1 "DFCO Requested" 0 "DFCO Not Requested" ;
VAL_ 390 RdPTHVCntrReq 0 "Undetermined" 1 "Close Allowed" 2 "Request Open" ;
VAL_ 817 RrAxlTmpInhIO 1 "true" 0 "false" ;
VAL_ 817 RrAxlMalfIO 1 "true" 0 "false" ;
VAL_ 465 RrAxlOpeMod 3 "Unknown" 2 "Locked" 1 "Active" 0 "Open" ;
VAL_ 465 RrAxlEstTrqV 1 "Invalid" 0 "Valid" ;
VAL_ 465 RrAxlStat 3 "Permanently Failed" 2 "Temporary Limited" 1 "Temporary Inhibit" 0 "Normal" ;
VAL_ 465 RrAxlCtrlMod 1 "External" 0 "Internal" ;
VAL_ 465 RAMDVLAtv 1 "true" 0 "false" ;
VAL_ 460 SecAxlStat 3 "Permanently Failed" 2 "Temporary Limited" 1 "Temporary Inhibit" 0 "Normal" ;
VAL_ 460 SecAxlEstTrqV 1 "Invalid" 0 "Valid" ;
VAL_ 460 SAMDVLAtv 1 "true" 0 "false" ;
VAL_ 460 PTTrnsfrCseMd 3 "Neutral" 2 "4 Wheel Drive Low" 1 "4 Wheel Drive High" 0 "2 Wheel Drive High" ;
VAL_ 460 SecAxlCtrlMod 1 "External" 0 "Internal" ;
VAL_ 462 SATRCplReqAtv 1 "true" 0 "false" ;
VAL_ 463 FourWhlDrvIndReq 0 "No Indication" 1 "Indication 1" 2 "Indication 2" 3 "Indication 3" 4 "Indication 4" 5 "Indication 5" 6 "Indication 6" 7 "Unused and Reserved" ;
VAL_ 463 SecAxlNonEmMalfIO 1 "true" 0 "false" ;
VAL_ 463 SecAxlOperMod 3 "Active All Wheel Drive (High)" 2 "4 Wheel Drive Low Locked" 1 "4 Wheel Drive High Locked" 0 "2 Wheel Drive High" 15 "Neutral" 14 "Unknown" 7 "2 Wheel Drive Low" 6 "Active All Wheel Drive (Low)" 5 "4 Wheel Drive Low Open" 4 "4 Wheel Drive High Open" ;
VAL_ 463 SecAxlTmpInhIO 1 "true" 0 "false" ;
VAL_ 719 RVBATC_AxlTrqRqstAct 1 "true" 0 "false" ;
VAL_ 853 SrvPedtrnProtSysIO 1 "true" 0 "false" ;
VAL_ 853 PedtrnProtSysDisbld 1 "true" 0 "false" ;
VAL_ 853 PedtrnProtSysDpl 1 "true" 0 "false" ;
VAL_ 869 FCACustStngAvlbl 1 "true" 0 "false" ;
VAL_ 869 FwdClnAlrtCustCrntSetngVal 0 "No Action" 1 "Off" 2 "On" ;
VAL_ 869 GNCustSetngAvlbl 1 "true" 0 "false" ;
VAL_ 869 CPSUnblIO 1 "true" 0 "false" ;
VAL_ 869 ColPrSysStngAvl 1 "true" 0 "false" ;
VAL_ 869 CPSOffIO 1 "true" 0 "false" ;
VAL_ 869 CPSFldIO 1 "true" 0 "false" ;
VAL_ 869 ColPrSysCrntStng 0 "No Action" 1 "Off" 2 "Alert" 3 "Alert and Brake" ;
VAL_ 869 CPSAlrtOnlIO 1 "true" 0 "false" ;
VAL_ 869 GNCustCrntStngVal 0 "No Action" 1 "Off" 2 "On" ;
VAL_ 717 CPSATC_AxlTrqRqstAct 1 "true" 0 "false" ;
VAL_ 564 TrlrStabAstActIO 1 "true" 0 "false" ;
VAL_ 564 PerfTracSysStat 0 "Enabled" 1 "Disabled" 2 "Unavailable" 3 "Failed" ;
VAL_ 564 PerfTrcCrnExStngVal 0 "No Action" 1 "Off" 2 "Setting 1" 3 "Setting 2" 4 "Setting 3" 5 "Setting 4" 6 "Setting 5" 7 "Setting 6" 8 "Setting 7" 9 "Setting 8" 10 "Setting 9" 11 "Setting 10" 12 "Setting 11" 13 "Setting 12" 14 "Setting 13" 15 "Setting 14" 16 "Setting 15" ;
VAL_ 313 PrkAstAdvSysAct 1 "true" 0 "false" ;
VAL_ 313 SndPerfMdCsStRq 0 "No Action" 1 "Performance Mode 1" 2 "Performance Mode 2" 3 "Performance Mode 3" 4 "Performance Mode 4" 5 "Performance Mode 5" 6 "Performance Mode 6" 7 "Auto" ;
VAL_ 313 HptcStVbnStat 0 "Normal Operation" 1 "Unknown" 2 "Failed" ;
VAL_ 313 ACCSettingType 0 "Manual" 1 "Auto" ;
VAL_ 313 FCABrkPrflReq 1 "true" 0 "false" ;
VAL_ 313 ISA2CCC_ScndCdChr 0 "Unknown" 1 "A" 2 "B" 3 "C" 4 "D" 5 "E" 6 "F" 7 "G" 8 "H" 9 "I" 10 "J" 11 "K" 12 "L" 13 "M" 14 "N" 15 "O" 16 "P" 17 "Q" 18 "R" 19 "S" 20 "T" 21 "U" 22 "V" 23 "W" 24 "X" 25 "Y" 26 "Z" ;
VAL_ 313 ISA2CCC_FrstCdChr 0 "Unknown" 1 "A" 2 "B" 3 "C" 4 "D" 5 "E" 6 "F" 7 "G" 8 "H" 9 "I" 10 "J" 11 "K" 12 "L" 13 "M" 14 "N" 15 "O" 16 "P" 17 "Q" 18 "R" 19 "S" 20 "T" 21 "U" 22 "V" 23 "W" 24 "X" 25 "Y" 26 "Z" ;
VAL_ 313 DispPerfMdCsStRq 0 "No Action" 1 "Performance Mode 1" 2 "Performance Mode 2" 3 "Performance Mode 3" 4 "Performance Mode 4" 5 "Performance Mode 5" 6 "Performance Mode 6" 7 "Auto" ;
VAL_ 313 CrshAlrtStPrsnt 1 "true" 0 "false" ;
VAL_ 313 FwdClnAlrtCustStngReq 0 "No Action" 1 "Off" 2 "On" ;
VAL_ 313 GNCustStngReq 0 "No Action" 1 "Off" 2 "On" ;
VAL_ 818 FrntAxlTmpInhIO 1 "true" 0 "false" ;
VAL_ 818 FrAxlMalfIO 1 "true" 0 "false" ;
VAL_ 1328 ACSAlarm9 2 "Expired" 1 "Active" 0 "Inactive" ;
VAL_ 1328 ACSAlarm8 2 "Expired" 1 "Active" 0 "Inactive" ;
VAL_ 1328 ACSAlarm7 2 "Expired" 1 "Active" 0 "Inactive" ;
VAL_ 1328 ACSAlarm6 2 "Expired" 1 "Active" 0 "Inactive" ;
VAL_ 1328 ACSAlarm5 2 "Expired" 1 "Active" 0 "Inactive" ;
VAL_ 1328 ACSAlarm4 2 "Expired" 1 "Active" 0 "Inactive" ;
VAL_ 1328 ACSAlarm3 2 "Expired" 1 "Active" 0 "Inactive" ;
VAL_ 1328 ACSAlarm2 2 "Expired" 1 "Active" 0 "Inactive" ;
VAL_ 1328 ACSAlarm15 2 "Expired" 1 "Active" 0 "Inactive" ;
VAL_ 1328 ACSAlarm14 2 "Expired" 1 "Active" 0 "Inactive" ;
VAL_ 1328 ACSAlarm13 2 "Expired" 1 "Active" 0 "Inactive" ;
VAL_ 1328 ACSAlarm12 2 "Expired" 1 "Active" 0 "Inactive" ;
VAL_ 1328 ACSAlarm11 2 "Expired" 1 "Active" 0 "Inactive" ;
VAL_ 1328 ACSAlarm10 2 "Expired" 1 "Active" 0 "Inactive" ;
VAL_ 1328 ACSAlarm1 2 "Expired" 1 "Active" 0 "Inactive" ;
VAL_ 1328 ACSAlarm0 2 "Expired" 1 "Active" 0 "Inactive" ;
VAL_ 1296 ACCAutoSetSpdStat 0 "No Set Speed Change" 1 "Proposed Speed Limit Change" 2 "Accepted Speed Limit Change" 3 "Declined Speed Limit Change" ;
VAL_ 1296 FwdClnAlrtOffIO 1 "true" 0 "false" ;
VAL_ 1296 VADIR_IndLvl 0 "No indication" 1 "Indication level 1" 2 "Indication Level 2" 3 "Indication Level 3" 4 "Indication Level 4" 5 "Indication Level 5" 6 "Indication Level 6" 7 "Indication Level 7" 8 "Indication Level 8" ;
VAL_ 311 PsngSysHdingV 1 "Invalid" 0 "Valid" ;
VAL_ 311 HrsV 1 "Invalid" 0 "Valid" ;
VAL_ 311 MinsV 1 "Invalid" 0 "Valid" ;
VAL_ 311 PsngSysDilPrcsV 1 "Invalid" 0 "Valid" ;
VAL_ 311 PsngSysElvtnV 1 "Invalid" 0 "Valid" ;
VAL_ 311 VehSpeSta 3 "Invalid" 2 "Fast" 1 "Slow" 0 "Stationary" ;
VAL_ 536 ShtToPrkBfExtngVehIO 1 "true" 0 "false" ;
VAL_ 536 AutoBrkRlsIO 1 "true" 0 "false" ;
VAL_ 536 HdUpDsplyUnblIO 1 "true" 0 "false" ;
VAL_ 536 FSRACCFrstRsmPrssIO 1 "true" 0 "false" ;
VAL_ 536 FrtRdrBlckdIO 1 "true" 0 "false" ;
VAL_ 810 PsngSysLongV 1 "Invalid" 0 "Valid" ;
VAL_ 810 PsngSysLatV 1 "Invalid" 0 "Valid" ;
VAL_ 848 TrlrBrkStat 6 "Integration Calibrated Off" 0 "Normal Operation" 1 "Brake Control Interactive" 2 "Temporary Inhibit" 3 "Temporarily Limited" 4 "Permanently Failed" 5 "Communication Failed" ;
VAL_ 848 TrlrBrkngSysBrkLtsReq 1 "true" 0 "false" ;
VAL_ 848 SrvTrlrBrkngSysIO 1 "true" 0 "false" ;
VAL_ 848 TrlrWiringFltIO 1 "true" 0 "false" ;
VAL_ 848 TrlrCnctdIO 1 "true" 0 "false" ;
VAL_ 848 TrlrBrkngGainSetIO 1 "true" 0 "false" ;
VAL_ 848 ChkTrlrIO 1 "true" 0 "false" ;
VAL_ 848 TrlrHtchSwAtv_ITBC 1 "true" 0 "false" ;
VAL_ 953 DslGlwTypReqd 0 "Cold Start" 1 "Intermediate" 2 "Diesel Particulate Filter Cleaning" ;
VAL_ 953 RdctHtrCReq 0 "Off" 1 "On" ;
VAL_ 953 RdctHtrBReq 0 "Off" 1 "On" ;
VAL_ 953 RdctHtrAReq 0 "Off" 1 "On" ;
VAL_ 953 EngPwrCnfg 15 "Configuration 15" 14 "Configuration 14" 13 "Configuration 13" 12 "Configuration 12" 11 "Configuration 11" 10 "Configuration 10" 9 "Configuration 9" 8 "Configuration 8" 7 "Configuration 7" 6 "Configuration 6" 5 "Configuration 5" 4 "Configuration 4" 3 "Configuration 3" 2 "Configuration 2" 1 "Configuration 1" 0 "Default" ;
VAL_ 953 EngCntlSenPTRlyVltM 1 "Use Data" 0 "Don't Use Data" ;
VAL_ 953 CrntFlConsmpV 1 "Invalid" 0 "Valid" ;
VAL_ 953 DslPartFltrClngAlgActM 1 "Use Data" 0 "Don't Use Data" ;
VAL_ 953 DslPartFltrClngAlgAct 1 "true" 0 "false" ;
VAL_ 953 MassAirFloV 1 "Invalid" 0 "Valid" ;
VAL_ 953 GlwPlgReqdOn 1 "true" 0 "false" ;
VAL_ 711 RdVltCrntTmpModInitStat 0 "Not Complete" 1 "Complete" ;
VAL_ 711 RdVltCrTmpMdCntOpFlt 1 "true" 0 "false" ;
VAL_ 711 RdHVltBatPckVltV 1 "Invalid" 0 "Valid" ;
VAL_ 711 RdHVltBatPckVltM 1 "Use Data" 0 "Don't Use Data" ;
VAL_ 711 RdHVltBatPckCrntV 1 "Invalid" 0 "Valid" ;
VAL_ 711 RdHVltBatPckCrntM 1 "Use Data" 0 "Don't Use Data" ;
VAL_ 711 RdntHVBatClOvrVltTstAct 1 "true" 0 "false" ;
VAL_ 304 PedFrndlyAlrtCsStReq 0 "No Action" 1 "Off" 2 "On" ;
VAL_ 304 AlrmStat 4 "Arming Delay" 3 "Alarm Active" 2 "Disarmed" 1 "Armed" 0 "Off" ;
VAL_ 1105 JmpStrtReq 1 "true" 0 "false" ;
VAL_ 1105 HybVehHiVltInvDisRqd 1 "true" 0 "false" ;
VAL_ 1105 NESSRoSevSt 1 "true" 0 "false" ;
VAL_ 1105 NESSRiSiSevSt 1 "true" 0 "false" ;
VAL_ 1105 NESSReImpSevSt 1 "true" 0 "false" ;
VAL_ 1105 NESSLeSiSevSt 1 "true" 0 "false" ;
VAL_ 1105 NESSFrImpSt2SevSt 1 "true" 0 "false" ;
VAL_ 1105 NESSFrImpSt1SevSt 1 "true" 0 "false" ;
VAL_ 1105 NESSFrImpPreSevSt 1 "true" 0 "false" ;
VAL_ 1005 EnhSvVehTopSpdLmR 2 "Inactive" 1 "Active" 0 "No Action" ;
VAL_ 688 StrtrGenSpdV 1 "Invalid" 0 "Valid" ;
VAL_ 993 CstmrUsblSOCV 1 "Invalid" 0 "Valid" ;
VAL_ 993 JmpStrtStat 0 "Inactive" 1 "In Progress" 2 "Complete" 3 "Power Mode" 4 "Disabled" ;
VAL_ 993 HybVehHiVltSysDisbld 1 "true" 0 "false" ;
VAL_ 993 SvcHybridSysIO 1 "true" 0 "false" ;
VAL_ 993 HybMdDisp 15 "Engine Charging Battery While Idle" 14 "Engine Charging Battery Moving" 13 "Engine Power Load Sharing" 12 "Battery Power Load Sharing" 11 "Undetermined" 10 "Charging With Engine On" 9 "Charging With Engine Off" 8 "Hybrid Power 4WD" 7 "Hybrid Power 2WD" 6 "Engine Power 4WD" 5 "Engine Power 2WD" 4 "Battery Power 4WD" 3 "Battery Power 2WD" 2 "Auto Stop" 1 "Engine Idle" 0 "Default / Accessory" ;
VAL_ 490 SrvcFlSysPrkInOpnArIO 1 "true" 0 "false" ;
VAL_ 490 FlLvlTank2PctV 1 "Invalid" 0 "Valid" ;
VAL_ 490 AltFuelPHeatAct 1 "true" 0 "false" ;
VAL_ 490 AltFuelMdReqDndIO 1 "true" 0 "false" ;
VAL_ 490 AltFuelLvlLo 1 "true" 0 "false" ;
VAL_ 490 AltFuelAccWrnngAct 1 "true" 0 "false" ;
VAL_ 490 FuelMdStat 3 "Alternative Fuel Cut-off Active" 2 "Liquified Petroleum Gas Mode" 1 "Natural Gas Mode" 0 "Gasoline Mode" ;
VAL_ 431 TDslPrtFltrIdlRgtnMdAtv 1 "true" 0 "false" ;
VAL_ 431 DrvlneTrqStabStat 3 "Level 3" 0 "Normal Stability" 1 "Level 1" 2 "Level 2" ;
VAL_ 431 TrnsTrqCnvCltCmdMdF 1 "true" 0 "false" ;
VAL_ 431 AutoTransGrSftDirectFl 1 "true" 0 "false" ;
VAL_ 431 AutoTransGrSftDirect 2 "Downshift in Progress" 1 "Upshift in Progress" 0 "No Shift in Progress" ;
VAL_ 431 TrnsTrqCnvCltCmndMd 7 "Not Supported" 3 "Locked" 2 "Controlled Slip" 1 "Transitioning" 0 "Unlocked" ;
VAL_ 431 TrnsStWntrMdOvrd 2 "Override To Winter" 1 "Override To Not Winter" 0 "No Override" ;
VAL_ 431 TrnsStTwHaulMdOvrd 2 "Override To Tow Haul" 1 "Override To Not Tow Haul" 0 "No Override" ;
VAL_ 431 TrnsStSprtMdOvrd 2 "Override To Sport" 1 "Override To Not Sport" 0 "No Override" ;
VAL_ 431 TrnsStEconMdOvrd 2 "Override To Economy" 1 "Override To Not Economy" 0 "No Override" ;
VAL_ 431 TrnsInpCltchStat 0 "Disengaged" 1 "Engaging" 2 "Engaged" 3 "Disengaging" 4 "Controlled Slip" 5 "Reserved" 6 "Reserved" 7 "Not Supported" ;
VAL_ 431 TrnsAntcptdCrpTrqRRnV 1 "Invalid" 0 "Valid" ;
VAL_ 431 TrnCltAdpAtv 1 "true" 0 "false" ;
VAL_ 431 TransCrnkPermsnStat 0 "Crank Not Permitted" 1 "Crank Permitted" ;
VAL_ 431 WrmUpShftPtrn 0 "Inactive" 1 "Active" ;
VAL_ 715 ACCATC_SplREngInpR 1 "true" 0 "false" ;
VAL_ 715 ACCATC_DrvAstdGoSt 2 "Apply Acc Pedal or Resume Sw To Go" 1 "Apply Accel Pedal to Go" 0 "Not Stopped" ;
VAL_ 715 ACCATC_ACCTyp 2 "Full Speed Range ACC with Booster" 1 "Full Speed Range ACC" 0 "Adaptive Cruise Control" ;
VAL_ 715 ACCATC_ACCAct 1 "true" 0 "false" ;
VAL_ 453 DrvIntndAxlTrqV 1 "Invalid" 0 "Valid" ;
VAL_ 453 DrvIntndAxlTrqMinV 1 "Invalid" 0 "Valid" ;
VAL_ 453 DrvIntndAxlTrqMaxV 1 "Invalid" 0 "Valid" ;
SIG_GROUP_ 971 BattCrntHiRes 1 : BCHR_BattCrntRwVal BCHR_BattCrntRwVlMu BCHR_BattCrntRwValV;
SIG_GROUP_ 454 ChsSysPrdAxlTqRq 1 : CSPATR_TrqIntrvnTyp CSPATR_PrdTrqRqVal CSPATR_TrqRqTyp;
SIG_GROUP_ 421 HybTransGrReq 1 : HTGR_ReqVal HTGR_ReqTyp HTGR_ReqPrty;
SIG_GROUP_ 421 HybTrqCnvCltReq 1 : HTCCR_ReqVal HTCCR_ReqPrty;
SIG_GROUP_ 456 PerfTrcEngSpdReq 1 : PTESR_EngSpdRqVal PTESR_EngSpdCntlRs PTESR_EngSpdIntTyp;
SIG_GROUP_ 456 PerfTrcTrqRq 1 : PTTR_TrqReqVal PTTR_TrqRedRlzSugg PTTR_TrqInvTyp;
SIG_GROUP_ 393 TrnsPrdCrkshftTrqRq 1 : TPCTR_TorqReqVal TPCTR_TrqIntrvnTyp;
SIG_GROUP_ 393 TrnsImmCrksftTrqRq 1 : TICTR_TorqRqVal TICTR_TorqRespTyp;
SIG_GROUP_ 199 TransOutputRotStat 1 : TORSTimestamp TORSPulsCntr TORSValidity TORSRstOcrd TORSLstTransType TORSRotDir;
SIG_GROUP_ 398 CrksftTrqStbStat 1 : CTSS_StbltyLvl CTSS_StbltyTyp;
SIG_GROUP_ 390 HybEngStStpInfo 1 : HESSI_EngStrtTyp HESSI_EngStrtStpMd;
SIG_GROUP_ 465 RrAxlMaxDifVelLm 1 : RAMDVLReqVal RAMDVLAtv;
SIG_GROUP_ 460 SecAxlMaxDifVelLm 1 : SAMDVLReqVal SAMDVLAtv;
SIG_GROUP_ 462 SecAxlTrqReq 1 : SATRCplReqVal SATRCplReqAtv;
SIG_GROUP_ 719 RrVrtlBmpAxlTrqCmd 1 : RVBATC_AxlTrqRqstAct RVBATC_AxlTrqRqst;
SIG_GROUP_ 717 ColPrSysAxlTrqCmd 1 : CPSATC_AxlTrqRqstAct CPSATC_AxlTrqRqst;
SIG_GROUP_ 313 IntlStdAlph2CddCntryCd 1 : ISA2CCC_ScndCdChr ISA2CCC_FrstCdChr;
SIG_GROUP_ 1328 AlrmClkStat 1 : ACSAlarm9 ACSAlarm8 ACSAlarm7 ACSAlarm6 ACSAlarm5 ACSAlarm4 ACSAlarm3 ACSAlarm2 ACSAlarm15 ACSAlarm14 ACSAlarm13 ACSAlarm12 ACSAlarm11 ACSAlarm10 ACSAlarm1 ACSAlarm0;
SIG_GROUP_ 1296 VhlAhdDstIndReq 1 : VADIR_IndLvl VADIR_FlwTme VADIR_FlwDst;
SIG_GROUP_ 1105 NoEvSevSt 1 : NESSRoSevSt NESSRiSiSevSt NESSReImpSevSt NESSLeSiSevSt NESSFrImpSt2SevSt NESSFrImpSt1SevSt NESSFrImpPreSevSt;
SIG_GROUP_ 715 ACCAxlTrqCmd 1 : ACCATC_SplREngInpR ACCATC_DrvAstdGoSt ACCATC_AxlTrqRq ACCATC_ACCTyp ACCATC_ACCAct;
